VERSION ""

NS_ :

BS_:

BU_: BMS PCU DASH DCU LVPDB DART SN_FRONT SN_REAR IVT

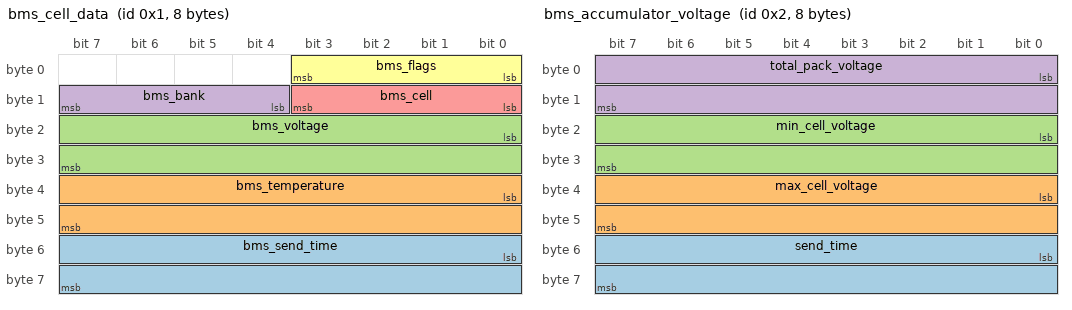
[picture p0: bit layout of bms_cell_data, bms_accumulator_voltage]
BO_ 1 bms_cell_data: 8 BMS
 SG_ bms_send_time : 48|16@1+ (1,0) [0|0] "" Vector__XXX
 SG_ bms_temperature : 32|16@1- (1,0) [0|0] "" Vector__XXX
 SG_ bms_voltage : 16|16@1+ (1,0) [0|0] "" Vector__XXX
 SG_ bms_bank : 12|4@1+ (1,0) [0|0] "" Vector__XXX
 SG_ bms_cell : 8|4@1+ (1,0) [0|0] "" Vector__XXX
 SG_ bms_flags : 0|4@1+ (1,0) [0|0] "" Vector__XXX

BO_ 2 bms_accumulator_voltage: 8 BMS
 SG_ send_time : 48|16@1+ (1,0) [0|0] "" Vector__XXX
 SG_ max_cell_voltage : 32|16@1+ (1,0) [0|0] "" Vector__XXX
 SG_ min_cell_voltage : 16|16@1+ (1,0) [0|0] "" Vector__XXX
 SG_ total_pack_voltage : 0|16@1+ (1,0) [0|0] "" Vector__XXX

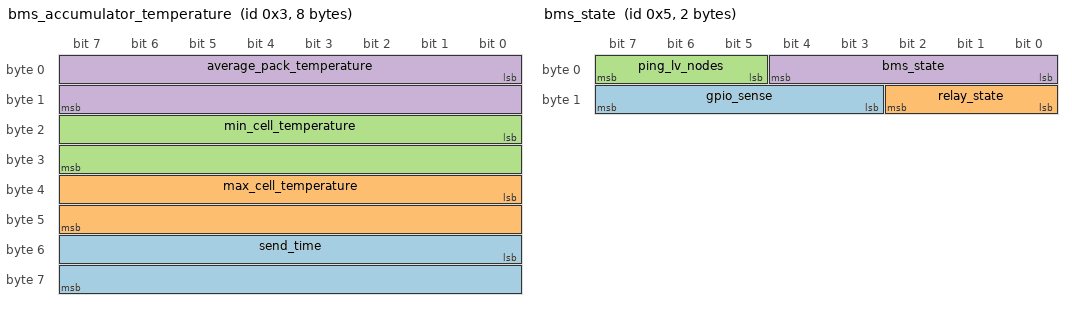
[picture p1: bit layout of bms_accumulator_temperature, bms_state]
BO_ 3 bms_accumulator_temperature: 8 BMS
 SG_ send_time : 48|16@1+ (1,0) [0|0] "" Vector__XXX
 SG_ max_cell_temperature : 32|16@1- (1,0) [0|0] "" Vector__XXX
 SG_ min_cell_temperature : 16|16@1- (1,0) [0|0] "" Vector__XXX
 SG_ average_pack_temperature : 0|16@1- (1,0) [0|0] "" Vector__XXX

BO_ 4 accumulator_faults: 1 BMS
 SG_ imd_fault : 1|1@1+ (1,0) [0|0] "" Vector__XXX
 SG_ bms_fault : 0|1@1+ (1,0) [0|0] "" Vector__XXX

BO_ 5 bms_state: 2 BMS
 SG_ gpio_sense : 11|5@1+ (1,0) [0|0] "" Vector__XXX
 SG_ relay_state : 8|3@1+ (1,0) [0|0] "" Vector__XXX
 SG_ ping_lv_nodes : 5|3@1+ (1,0) [0|0] "" Vector__XXX
 SG_ bms_state : 0|5@1+ (1,0) [0|0] "" Vector__XXX

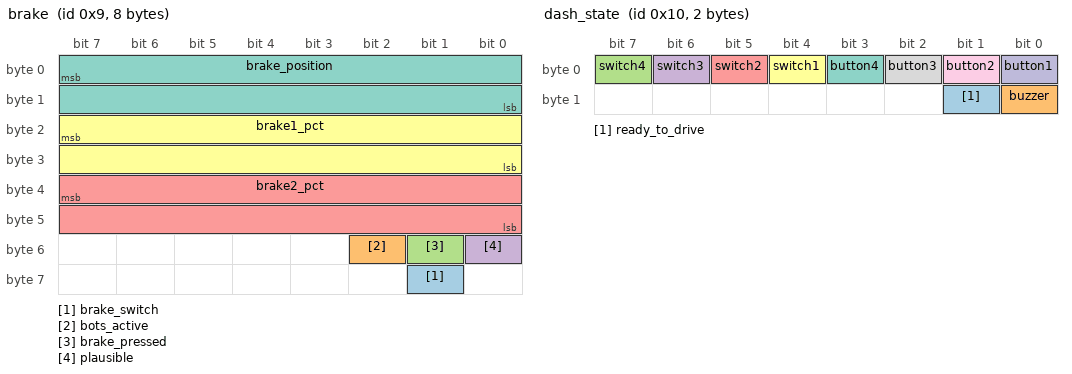
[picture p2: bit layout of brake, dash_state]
BO_ 9 brake: 8 PCU
 SG_ brake_switch : 57|1@1+ (1,0) [0|0] "" Vector__XXX
 SG_ bots_active : 50|1@1+ (1,0) [0|0] "" Vector__XXX
 SG_ brake_pressed : 49|1@1+ (1,0) [0|0] "" Vector__XXX
 SG_ plausible : 48|1@1+ (1,0) [0|0] "" Vector__XXX
 SG_ brake2_pct : 39|16@0+ (0.01,0) [0|0] "%" Vector__XXX
 SG_ brake1_pct : 23|16@0+ (0.01,0) [0|0] "%" Vector__XXX
 SG_ brake_position : 7|16@0+ (0.01,0) [0|0] "%" Vector__XXX

BO_ 10 bspd_state: 1 PCU
 SG_ bspd_state : 0|8@1+ (1,0) [0|0] "" Vector__XXX

BO_ 11 res_state: 2 PCU
 SG_ res_state : 0|8@1+ (1,0) [0|0] "" Vector__XXX

BO_ 16 dash_state: 2 DASH
 SG_ ready_to_drive : 9|1@1+ (1,0) [0|0] "" Vector__XXX
 SG_ buzzer : 8|1@1+ (1,0) [0|0] "" Vector__XXX
 SG_ switch4 : 7|1@1+ (1,0) [0|0] "" Vector__XXX
 SG_ switch3 : 6|1@1+ (1,0) [0|0] "" Vector__XXX
 SG_ switch2 : 5|1@1+ (1,0) [0|0] "" Vector__XXX
 SG_ switch1 : 4|1@1+ (1,0) [0|0] "" Vector__XXX
 SG_ button4 : 3|1@1+ (1,0) [0|0] "" Vector__XXX
 SG_ button3 : 2|1@1+ (1,0) [0|0] "" Vector__XXX
 SG_ button2 : 1|1@1+ (1,0) [0|0] "" Vector__XXX
 SG_ button1 : 0|1@1+ (1,0) [0|0] "" Vector__XXX

BO_ 22 lvpdb_lv_24v_bus_and_12v_bus_vol: 4 LVPDB
 SG_ lv_12v_voltage : 16|16@1+ (1,0) [0|0] "" Vector__XXX
 SG_ lv_24v_voltage : 0|16@1+ (1,0) [0|0] "" Vector__XXX

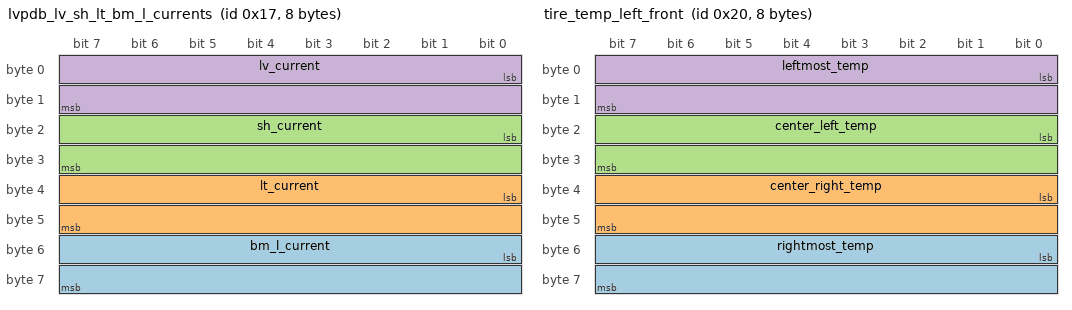
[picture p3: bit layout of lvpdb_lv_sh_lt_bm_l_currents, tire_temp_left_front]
BO_ 23 lvpdb_lv_sh_lt_bm_l_currents: 8 LVPDB
 SG_ bm_l_current : 48|16@1+ (1,0) [0|0] "" Vector__XXX
 SG_ lt_current : 32|16@1+ (1,0) [0|0] "" Vector__XXX
 SG_ sh_current : 16|16@1+ (1,0) [0|0] "" Vector__XXX
 SG_ lv_current : 0|16@1+ (1,0) [0|0] "" Vector__XXX

BO_ 24 lvpdb_sm_af1_af2_cp_rf_currents: 8 LVPDB
 SG_ cp_rf_current : 32|16@1+ (1,0) [0|0] "" Vector__XXX
 SG_ af1_af2_current : 16|16@1+ (1,0) [0|0] "" Vector__XXX
 SG_ sm_current : 0|16@1+ (1,0) [0|0] "" Vector__XXX

BO_ 30 linpot_front: 4 SN_FRONT
 SG_ linpot_right : 16|16@1+ (0.01,0) [0|0] "mm" Vector__XXX
 SG_ linpot_left : 0|16@1+ (0.01,0) [0|0] "mm" Vector__XXX

BO_ 31 linpot_rear: 4 SN_REAR
 SG_ linpot_right : 16|16@1+ (0.01,0) [0|0] "mm" Vector__XXX
 SG_ linpot_left : 0|16@1+ (0.01,0) [0|0] "mm" Vector__XXX

BO_ 32 tire_temp_left_front: 8 SN_FRONT
 SG_ rightmost_temp : 48|16@1+ (1,0) [0|0] "" Vector__XXX
 SG_ center_right_temp : 32|16@1+ (1,0) [0|0] "" Vector__XXX
 SG_ center_left_temp : 16|16@1+ (1,0) [0|0] "" Vector__XXX
 SG_ leftmost_temp : 0|16@1+ (1,0) [0|0] "" Vector__XXX

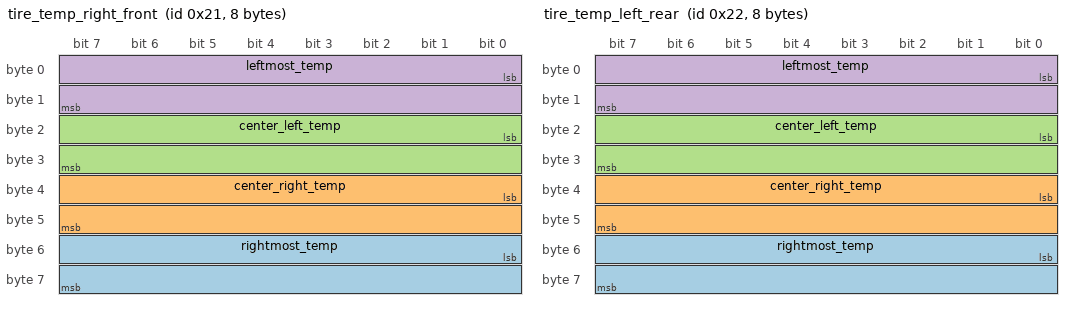
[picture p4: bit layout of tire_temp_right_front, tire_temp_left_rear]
BO_ 33 tire_temp_right_front: 8 SN_FRONT
 SG_ rightmost_temp : 48|16@1+ (1,0) [0|0] "" Vector__XXX
 SG_ center_right_temp : 32|16@1+ (1,0) [0|0] "" Vector__XXX
 SG_ center_left_temp : 16|16@1+ (1,0) [0|0] "" Vector__XXX
 SG_ leftmost_temp : 0|16@1+ (1,0) [0|0] "" Vector__XXX

BO_ 34 tire_temp_left_rear: 8 SN_REAR
 SG_ rightmost_temp : 48|16@1+ (1,0) [0|0] "" Vector__XXX
 SG_ center_right_temp : 32|16@1+ (1,0) [0|0] "" Vector__XXX
 SG_ center_left_temp : 16|16@1+ (1,0) [0|0] "" Vector__XXX
 SG_ leftmost_temp : 0|16@1+ (1,0) [0|0] "" Vector__XXX

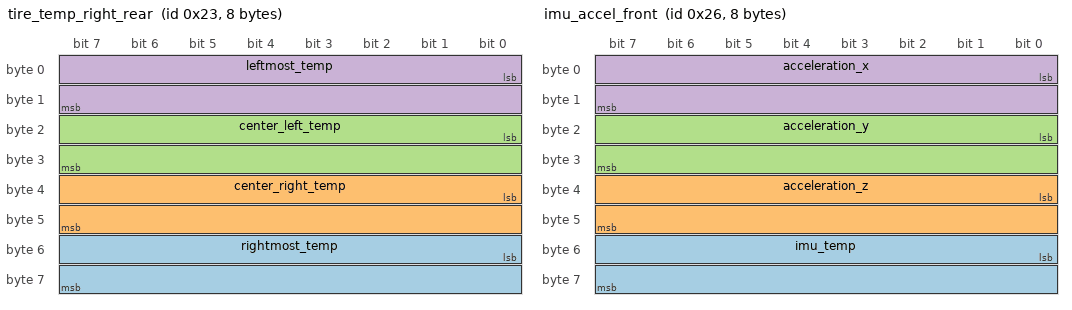
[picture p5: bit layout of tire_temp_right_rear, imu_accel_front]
BO_ 35 tire_temp_right_rear: 8 SN_REAR
 SG_ rightmost_temp : 48|16@1+ (1,0) [0|0] "" Vector__XXX
 SG_ center_right_temp : 32|16@1+ (1,0) [0|0] "" Vector__XXX
 SG_ center_left_temp : 16|16@1+ (1,0) [0|0] "" Vector__XXX
 SG_ leftmost_temp : 0|16@1+ (1,0) [0|0] "" Vector__XXX

BO_ 36 wss_front: 8 SN_FRONT
 SG_ wss_dir_flags : 32|8@1+ (1,0) [0|0] "" Vector__XXX
 SG_ wss_right : 16|16@1+ (0.01,0) [0|0] "mph" Vector__XXX
 SG_ wss_left : 0|16@1+ (0.01,0) [0|0] "mph" Vector__XXX

BO_ 37 wss_rear: 8 SN_REAR
 SG_ wss_dir_flags : 32|8@1+ (1,0) [0|0] "" Vector__XXX
 SG_ wss_right : 16|16@1+ (0.01,0) [0|0] "mph" Vector__XXX
 SG_ wss_left : 0|16@1+ (0.01,0) [0|0] "mph" Vector__XXX

BO_ 38 imu_accel_front: 8 SN_FRONT
 SG_ imu_temp : 48|16@1- (0.01,0) [0|0] "degC" Vector__XXX
 SG_ acceleration_z : 32|16@1- (0.061,0) [0|0] "mg" Vector__XXX
 SG_ acceleration_y : 16|16@1- (0.061,0) [0|0] "mg" Vector__XXX
 SG_ acceleration_x : 0|16@1- (0.061,0) [0|0] "mg" Vector__XXX

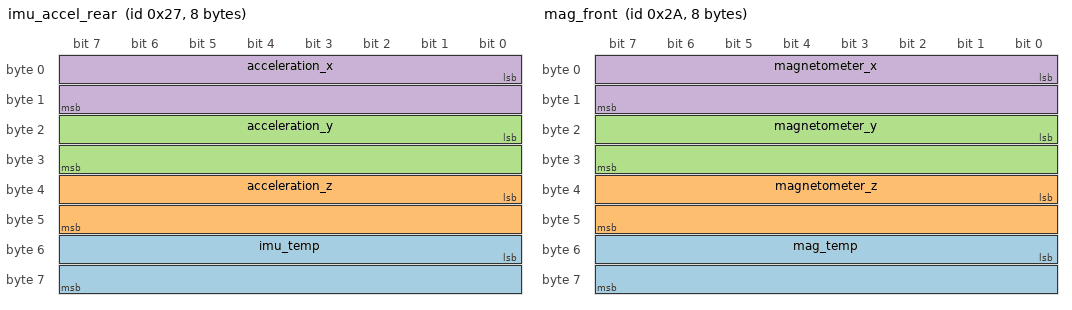
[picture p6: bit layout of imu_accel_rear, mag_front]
BO_ 39 imu_accel_rear: 8 SN_REAR
 SG_ imu_temp : 48|16@1- (0.01,0) [0|0] "degC" Vector__XXX
 SG_ acceleration_z : 32|16@1- (0.061,0) [0|0] "mg" Vector__XXX
 SG_ acceleration_y : 16|16@1- (0.061,0) [0|0] "mg" Vector__XXX
 SG_ acceleration_x : 0|16@1- (0.061,0) [0|0] "mg" Vector__XXX

BO_ 40 imu_gyro_front: 6 SN_FRONT
 SG_ gyro_z : 32|16@1- (70,0) [0|0] "mdps" Vector__XXX
 SG_ gyro_y : 16|16@1- (70,0) [0|0] "mdps" Vector__XXX
 SG_ gyro_x : 0|16@1- (70,0) [0|0] "mdps" Vector__XXX

BO_ 41 imu_gyro_rear: 6 SN_REAR
 SG_ gyro_z : 32|16@1- (70,0) [0|0] "mdps" Vector__XXX
 SG_ gyro_y : 16|16@1- (70,0) [0|0] "mdps" Vector__XXX
 SG_ gyro_x : 0|16@1- (70,0) [0|0] "mdps" Vector__XXX

BO_ 42 mag_front: 8 SN_FRONT
 SG_ mag_temp : 48|16@1- (0.01,0) [0|0] "degC" Vector__XXX
 SG_ magnetometer_z : 32|16@1- (0.5844,0) [0|0] "mG" Vector__XXX
 SG_ magnetometer_y : 16|16@1- (0.5844,0) [0|0] "mG" Vector__XXX
 SG_ magnetometer_x : 0|16@1- (0.5844,0) [0|0] "mG" Vector__XXX

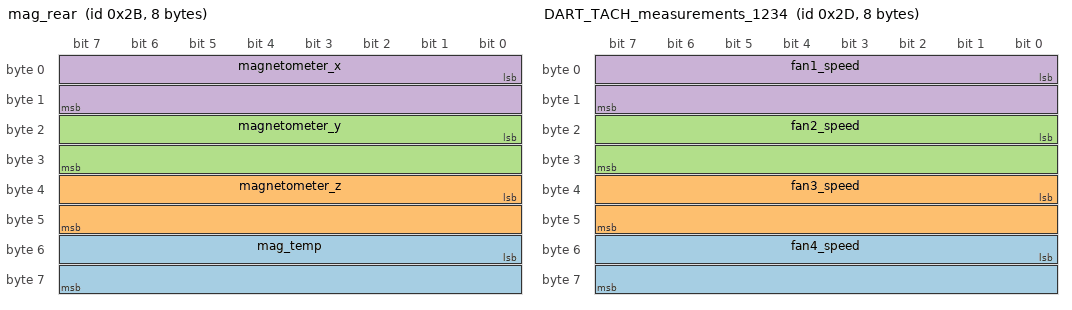
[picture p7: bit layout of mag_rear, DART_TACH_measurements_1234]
BO_ 43 mag_rear: 8 SN_REAR
 SG_ mag_temp : 48|16@1- (0.01,0) [0|0] "degC" Vector__XXX
 SG_ magnetometer_z : 32|16@1- (0.5844,0) [0|0] "mG" Vector__XXX
 SG_ magnetometer_y : 16|16@1- (0.5844,0) [0|0] "mG" Vector__XXX
 SG_ magnetometer_x : 0|16@1- (0.5844,0) [0|0] "mG" Vector__XXX

BO_ 45 DART_TACH_measurements_1234: 8 DART
 SG_ fan4_speed : 48|16@1+ (1,0) [0|0] "" Vector__XXX
 SG_ fan3_speed : 32|16@1+ (1,0) [0|0] "" Vector__XXX
 SG_ fan2_speed : 16|16@1+ (1,0) [0|0] "" Vector__XXX
 SG_ fan1_speed : 0|16@1+ (1,0) [0|0] "" Vector__XXX

BO_ 46 DART_TACH_measurements_5: 2 DART
 SG_ fan5_speed : 0|16@1+ (1,0) [0|0] "" Vector__XXX

BO_ 52 bbb_tps: 4 BMS
 SG_ current : 16|16@1+ (1,0) [0|0] "" Vector__XXX
 SG_ voltage : 0|16@1+ (1,0) [0|0] "" Vector__XXX

BO_ 53 pcu_tps: 4 PCU
 SG_ current : 16|16@1+ (1,0) [0|0] "mA" Vector__XXX
 SG_ voltage : 0|16@1+ (1,0) [0|0] "mV" Vector__XXX

BO_ 54 dash_tps: 4 DASH
 SG_ current : 16|16@1+ (1,0) [0|0] "" Vector__XXX
 SG_ voltage : 0|16@1+ (1,0) [0|0] "" Vector__XXX

BO_ 55 dcu_tps: 4 DCU
 SG_ current : 16|16@1+ (1,0) [0|0] "" Vector__XXX
 SG_ voltage : 0|16@1+ (1,0) [0|0] "" Vector__XXX

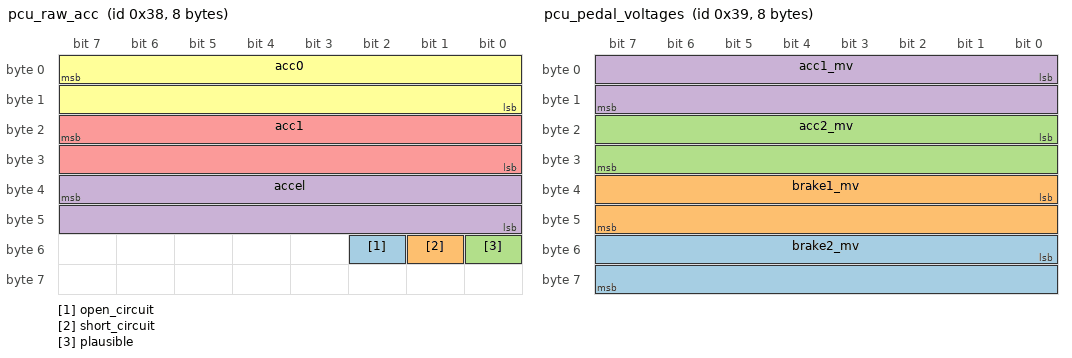
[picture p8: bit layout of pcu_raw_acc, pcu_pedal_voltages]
BO_ 56 pcu_raw_acc: 8 PCU
 SG_ open_circuit : 50|1@1+ (1,0) [0|0] "" Vector__XXX
 SG_ short_circuit : 49|1@1+ (1,0) [0|0] "" Vector__XXX
 SG_ plausible : 48|1@1+ (1,0) [0|0] "" Vector__XXX
 SG_ accel : 39|16@0+ (0.01,0) [0|0] "%" Vector__XXX
 SG_ acc1 : 23|16@0+ (0.01,0) [0|0] "%" Vector__XXX
 SG_ acc0 : 7|16@0+ (0.01,0) [0|0] "%" Vector__XXX

BO_ 57 pcu_pedal_voltages: 8 PCU
 SG_ brake2_mv : 48|16@1+ (1,0) [0|0] "mV" Vector__XXX
 SG_ brake1_mv : 32|16@1+ (1,0) [0|0] "mV" Vector__XXX
 SG_ acc2_mv : 16|16@1+ (1,0) [0|0] "mV" Vector__XXX
 SG_ acc1_mv : 0|16@1+ (1,0) [0|0] "mV" Vector__XXX

BO_ 64 gps_pos_front: 8 SN_FRONT
 SG_ longitude : 32|32@1- (1e-07,0) [0|0] "deg" Vector__XXX
 SG_ latitude : 0|32@1- (1e-07,0) [0|0] "deg" Vector__XXX

BO_ 65 gps_altitude_front: 8 SN_FRONT
 SG_ vdop : 48|16@1+ (0.01,0) [0|0] "" Vector__XXX
 SG_ hdop : 32|16@1+ (0.01,0) [0|0] "" Vector__XXX
 SG_ altitude : 0|32@1- (0.01,0) [0|0] "m" Vector__XXX

BO_ 66 gps_motion_front: 4 SN_FRONT
 SG_ course : 16|16@1+ (0.01,0) [0|0] "deg" Vector__XXX
 SG_ speed : 0|16@1+ (0.01,0) [0|0] "km/h" Vector__XXX

BO_ 67 gps_time_front: 3 SN_FRONT
 SG_ seconds : 16|8@1- (1,0) [0|0] "" Vector__XXX
 SG_ minutes : 8|8@1- (1,0) [0|0] "" Vector__XXX
 SG_ hours : 0|8@1- (1,0) [0|0] "" Vector__XXX

BO_ 68 gps_date_front: 3 SN_FRONT
 SG_ year : 16|8@1- (1,0) [0|0] "" Vector__XXX
 SG_ month : 8|8@1- (1,0) [0|0] "" Vector__XXX
 SG_ day : 0|8@1- (1,0) [0|0] "" Vector__XXX

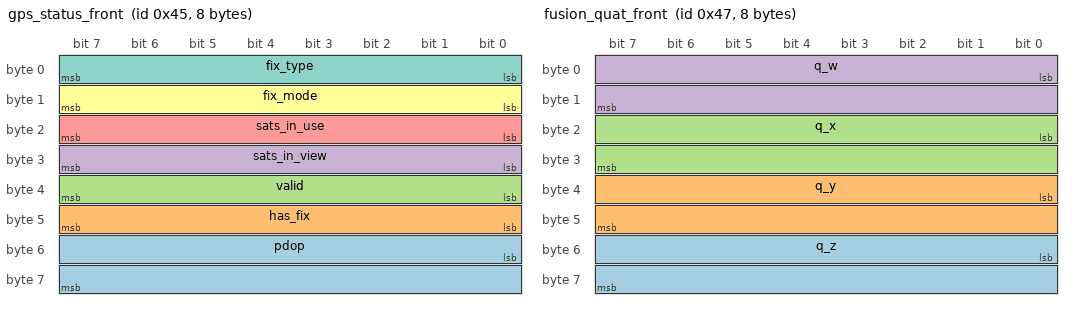
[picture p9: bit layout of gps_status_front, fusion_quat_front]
BO_ 69 gps_status_front: 8 SN_FRONT
 SG_ pdop : 48|16@1+ (0.01,0) [0|0] "" Vector__XXX
 SG_ has_fix : 40|8@1+ (1,0) [0|0] "" Vector__XXX
 SG_ valid : 32|8@1+ (1,0) [0|0] "" Vector__XXX
 SG_ sats_in_view : 24|8@1+ (1,0) [0|0] "" Vector__XXX
 SG_ sats_in_use : 16|8@1+ (1,0) [0|0] "" Vector__XXX
 SG_ fix_mode : 8|8@1+ (1,0) [0|0] "" Vector__XXX
 SG_ fix_type : 0|8@1+ (1,0) [0|0] "" Vector__XXX

BO_ 71 fusion_quat_front: 8 SN_FRONT
 SG_ q_z : 48|16@1- (3.051850947599719e-05,0) [0|0] "" Vector__XXX
 SG_ q_y : 32|16@1- (3.051850947599719e-05,0) [0|0] "" Vector__XXX
 SG_ q_x : 16|16@1- (3.051850947599719e-05,0) [0|0] "" Vector__XXX
 SG_ q_w : 0|16@1- (3.051850947599719e-05,0) [0|0] "" Vector__XXX

BO_ 72 fusion_euler_front: 6 SN_FRONT
 SG_ yaw : 32|16@1- (0.01,0) [0|0] "deg" Vector__XXX
 SG_ pitch : 16|16@1- (0.01,0) [0|0] "deg" Vector__XXX
 SG_ roll : 0|16@1- (0.01,0) [0|0] "deg" Vector__XXX

BO_ 73 fusion_lin_accel_front: 6 SN_FRONT
 SG_ lin_accel_z : 32|16@1- (1,0) [0|0] "mg" Vector__XXX
 SG_ lin_accel_y : 16|16@1- (1,0) [0|0] "mg" Vector__XXX
 SG_ lin_accel_x : 0|16@1- (1,0) [0|0] "mg" Vector__XXX

BO_ 74 fusion_earth_accel_front: 6 SN_FRONT
 SG_ earth_accel_z : 32|16@1- (1,0) [0|0] "mg" Vector__XXX
 SG_ earth_accel_y : 16|16@1- (1,0) [0|0] "mg" Vector__XXX
 SG_ earth_accel_x : 0|16@1- (1,0) [0|0] "mg" Vector__XXX

BO_ 75 fusion_status_front: 3 SN_FRONT
 SG_ mag_error : 16|8@1+ (0.1,0) [0|0] "deg" Vector__XXX
 SG_ accel_error : 8|8@1+ (0.1,0) [0|0] "deg" Vector__XXX
 SG_ flags : 0|8@1+ (1,0) [0|0] "" Vector__XXX

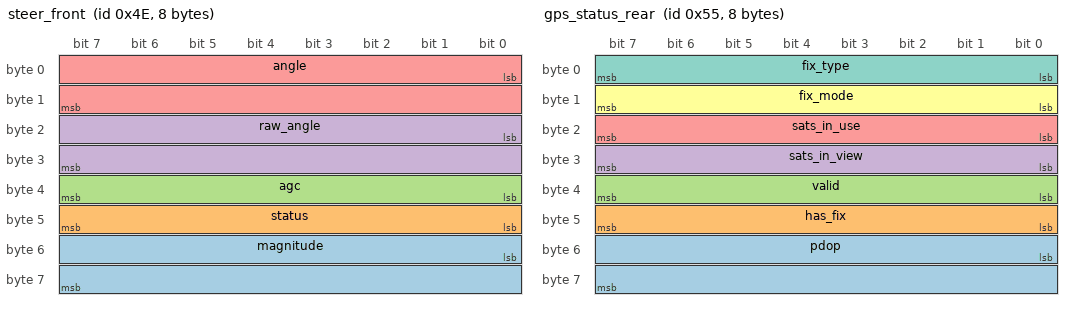
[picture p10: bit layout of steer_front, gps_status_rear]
BO_ 78 steer_front: 8 SN_FRONT
 SG_ magnitude : 48|16@1+ (1,0) [0|0] "" Vector__XXX
 SG_ status : 40|8@1+ (1,0) [0|0] "" Vector__XXX
 SG_ agc : 32|8@1+ (1,0) [0|0] "" Vector__XXX
 SG_ raw_angle : 16|16@1+ (0.087890625,0) [0|0] "deg" Vector__XXX
 SG_ angle : 0|16@1+ (0.087890625,0) [0|0] "deg" Vector__XXX

BO_ 80 gps_pos_rear: 8 SN_REAR
 SG_ longitude : 32|32@1- (1e-07,0) [0|0] "deg" Vector__XXX
 SG_ latitude : 0|32@1- (1e-07,0) [0|0] "deg" Vector__XXX

BO_ 81 gps_altitude_rear: 8 SN_REAR
 SG_ vdop : 48|16@1+ (0.01,0) [0|0] "" Vector__XXX
 SG_ hdop : 32|16@1+ (0.01,0) [0|0] "" Vector__XXX
 SG_ altitude : 0|32@1- (0.01,0) [0|0] "m" Vector__XXX

BO_ 82 gps_motion_rear: 4 SN_REAR
 SG_ course : 16|16@1+ (0.01,0) [0|0] "deg" Vector__XXX
 SG_ speed : 0|16@1+ (0.01,0) [0|0] "km/h" Vector__XXX

BO_ 83 gps_time_rear: 3 SN_REAR
 SG_ seconds : 16|8@1- (1,0) [0|0] "" Vector__XXX
 SG_ minutes : 8|8@1- (1,0) [0|0] "" Vector__XXX
 SG_ hours : 0|8@1- (1,0) [0|0] "" Vector__XXX

BO_ 84 gps_date_rear: 3 SN_REAR
 SG_ year : 16|8@1- (1,0) [0|0] "" Vector__XXX
 SG_ month : 8|8@1- (1,0) [0|0] "" Vector__XXX
 SG_ day : 0|8@1- (1,0) [0|0] "" Vector__XXX

BO_ 85 gps_status_rear: 8 SN_REAR
 SG_ pdop : 48|16@1+ (0.01,0) [0|0] "" Vector__XXX
 SG_ has_fix : 40|8@1+ (1,0) [0|0] "" Vector__XXX
 SG_ valid : 32|8@1+ (1,0) [0|0] "" Vector__XXX
 SG_ sats_in_view : 24|8@1+ (1,0) [0|0] "" Vector__XXX
 SG_ sats_in_use : 16|8@1+ (1,0) [0|0] "" Vector__XXX
 SG_ fix_mode : 8|8@1+ (1,0) [0|0] "" Vector__XXX
 SG_ fix_type : 0|8@1+ (1,0) [0|0] "" Vector__XXX

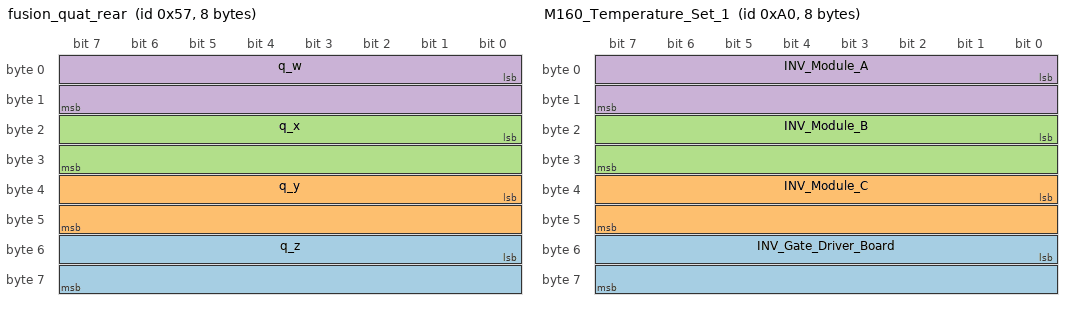
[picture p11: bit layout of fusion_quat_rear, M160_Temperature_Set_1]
BO_ 87 fusion_quat_rear: 8 SN_REAR
 SG_ q_z : 48|16@1- (3.051850947599719e-05,0) [0|0] "" Vector__XXX
 SG_ q_y : 32|16@1- (3.051850947599719e-05,0) [0|0] "" Vector__XXX
 SG_ q_x : 16|16@1- (3.051850947599719e-05,0) [0|0] "" Vector__XXX
 SG_ q_w : 0|16@1- (3.051850947599719e-05,0) [0|0] "" Vector__XXX

BO_ 88 fusion_euler_rear: 6 SN_REAR
 SG_ yaw : 32|16@1- (0.01,0) [0|0] "deg" Vector__XXX
 SG_ pitch : 16|16@1- (0.01,0) [0|0] "deg" Vector__XXX
 SG_ roll : 0|16@1- (0.01,0) [0|0] "deg" Vector__XXX

BO_ 89 fusion_lin_accel_rear: 6 SN_REAR
 SG_ lin_accel_z : 32|16@1- (1,0) [0|0] "mg" Vector__XXX
 SG_ lin_accel_y : 16|16@1- (1,0) [0|0] "mg" Vector__XXX
 SG_ lin_accel_x : 0|16@1- (1,0) [0|0] "mg" Vector__XXX

BO_ 90 fusion_earth_accel_rear: 6 SN_REAR
 SG_ earth_accel_z : 32|16@1- (1,0) [0|0] "mg" Vector__XXX
 SG_ earth_accel_y : 16|16@1- (1,0) [0|0] "mg" Vector__XXX
 SG_ earth_accel_x : 0|16@1- (1,0) [0|0] "mg" Vector__XXX

BO_ 91 fusion_status_rear: 3 SN_REAR
 SG_ mag_error : 16|8@1+ (0.1,0) [0|0] "deg" Vector__XXX
 SG_ accel_error : 8|8@1+ (0.1,0) [0|0] "deg" Vector__XXX
 SG_ flags : 0|8@1+ (1,0) [0|0] "" Vector__XXX

BO_ 160 M160_Temperature_Set_1: 8 INV
 SG_ INV_Gate_Driver_Board : 48|16@1- (0.1,0) [-3276.8|3276.7] "temperature:C" Vector__XXX
 SG_ INV_Module_C : 32|16@1- (0.1,0) [-3276.8|3276.7] "temperature:C" Vector__XXX
 SG_ INV_Module_B : 16|16@1- (0.1,0) [-3276.8|3276.7] "temperature:C" Vector__XXX
 SG_ INV_Module_A : 0|16@1- (0.1,0) [-3276.8|3276.7] "temperature:C" Vector__XXX

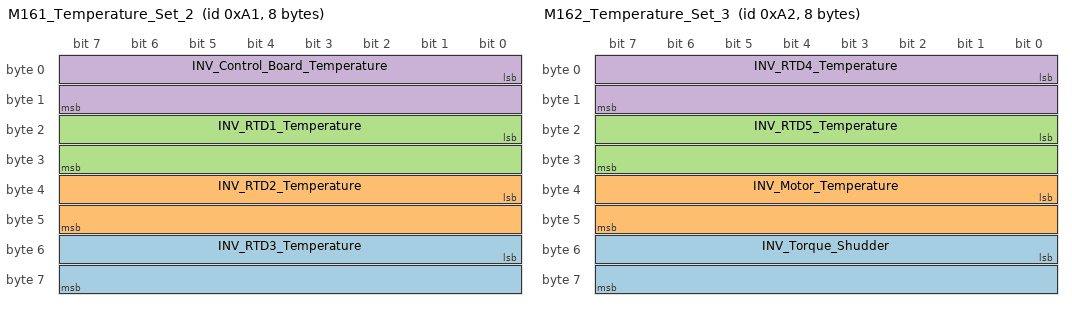
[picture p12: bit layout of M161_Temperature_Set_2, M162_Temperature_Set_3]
BO_ 161 M161_Temperature_Set_2: 8 INV
 SG_ INV_RTD3_Temperature : 48|16@1- (0.1,0) [-3276.8|3276.7] "temperature:C" Vector__XXX
 SG_ INV_RTD2_Temperature : 32|16@1- (0.1,0) [-3276.8|3276.7] "temperature:C" Vector__XXX
 SG_ INV_RTD1_Temperature : 16|16@1- (0.1,0) [-3276.8|3276.7] "temperature:C" Vector__XXX
 SG_ INV_Control_Board_Temperature : 0|16@1- (0.1,0) [-3276.8|3276.7] "temperature:C" Vector__XXX

BO_ 162 M162_Temperature_Set_3: 8 INV
 SG_ INV_Torque_Shudder : 48|16@1- (0.1,0) [-3276.8|3276.7] "torque:N.m" Vector__XXX
 SG_ INV_Motor_Temperature : 32|16@1- (0.1,0) [-3276.8|3276.7] "temperature:C" Vector__XXX
 SG_ INV_RTD5_Temperature : 16|16@1- (0.1,0) [-3276.8|3276.7] "temperature:C" Vector__XXX
 SG_ INV_RTD4_Temperature : 0|16@1- (0.1,0) [-3276.8|3276.7] "temperature:C" Vector__XXX

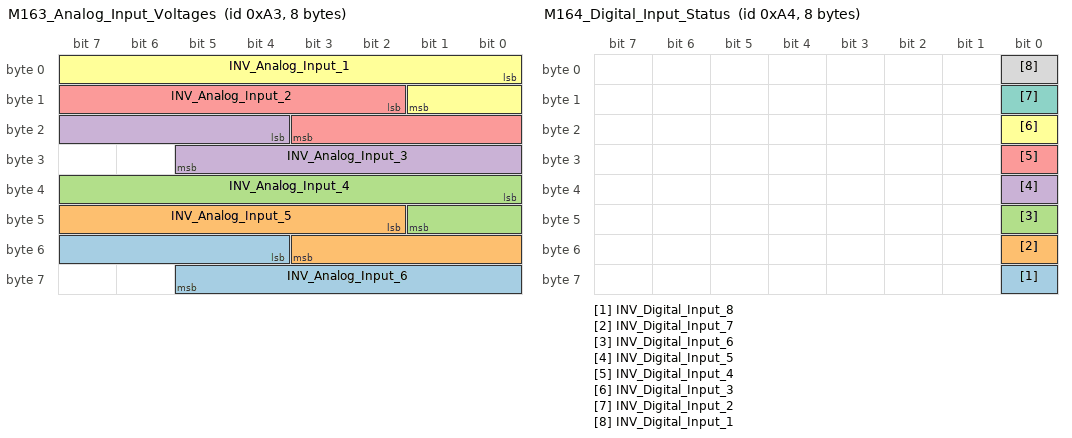
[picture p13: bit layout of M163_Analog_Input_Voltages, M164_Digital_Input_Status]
BO_ 163 M163_Analog_Input_Voltages: 8 INV
 SG_ INV_Analog_Input_6 : 52|10@1+ (0.01,0) [0|10.23] "voltage:V" Vector__XXX
 SG_ INV_Analog_Input_5 : 42|10@1+ (0.01,0) [0|10.23] "voltage:V" Vector__XXX
 SG_ INV_Analog_Input_4 : 32|10@1+ (0.01,0) [0|10.23] "voltage:V" Vector__XXX
 SG_ INV_Analog_Input_3 : 20|10@1+ (0.01,0) [0|10.23] "voltage:V" Vector__XXX
 SG_ INV_Analog_Input_2 : 10|10@1+ (0.01,0) [0|10.23] "voltage:V" Vector__XXX
 SG_ INV_Analog_Input_1 : 0|10@1+ (0.01,0) [0|10.23] "voltage:V" Vector__XXX

BO_ 164 M164_Digital_Input_Status: 8 INV
 SG_ INV_Digital_Input_8 : 56|1@1+ (1,0) [0|1] "" Vector__XXX
 SG_ INV_Digital_Input_7 : 48|1@1+ (1,0) [0|1] "" Vector__XXX
 SG_ INV_Digital_Input_6 : 40|1@1+ (1,0) [0|1] "" Vector__XXX
 SG_ INV_Digital_Input_5 : 32|1@1+ (1,0) [0|1] "" Vector__XXX
 SG_ INV_Digital_Input_4 : 24|1@1+ (1,0) [0|1] "" Vector__XXX
 SG_ INV_Digital_Input_3 : 16|1@1+ (1,0) [0|1] "" Vector__XXX
 SG_ INV_Digital_Input_2 : 8|1@1+ (1,0) [0|1] "" Vector__XXX
 SG_ INV_Digital_Input_1 : 0|1@1+ (1,0) [0|1] "" Vector__XXX

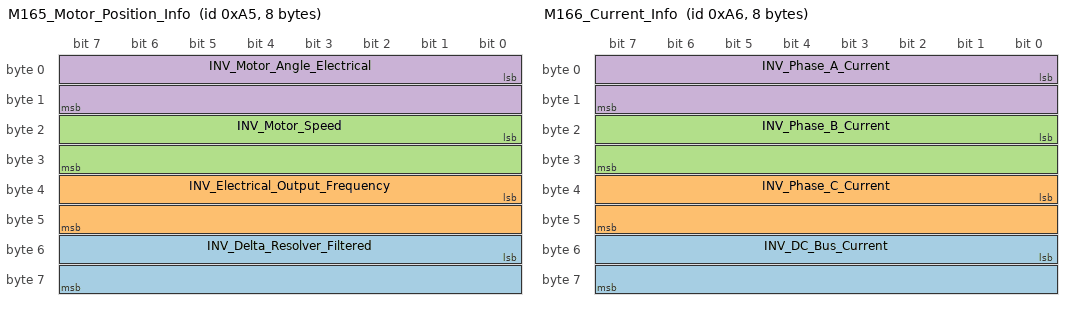
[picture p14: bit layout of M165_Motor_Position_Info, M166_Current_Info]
BO_ 165 M165_Motor_Position_Info: 8 INV
 SG_ INV_Delta_Resolver_Filtered : 48|16@1- (0.1,0) [-3276.8|3276.7] "angle:deg" Vector__XXX
 SG_ INV_Electrical_Output_Frequency : 32|16@1- (0.1,0) [-3276.8|3276.7] "frequency:Hz" Vector__XXX
 SG_ INV_Motor_Speed : 16|16@1- (1,0) [-32768|32767] "angular_speed:rpm" Vector__XXX
 SG_ INV_Motor_Angle_Electrical : 0|16@1+ (0.1,0) [0|6553.5] "angle:deg" Vector__XXX

BO_ 166 M166_Current_Info: 8 INV
 SG_ INV_DC_Bus_Current : 48|16@1- (0.1,0) [-3276.8|3276.7] "current:A" Vector__XXX
 SG_ INV_Phase_C_Current : 32|16@1- (0.1,0) [-3276.8|3276.7] "current:A" Vector__XXX
 SG_ INV_Phase_B_Current : 16|16@1- (0.1,0) [-3276.8|3276.7] "current:A" Vector__XXX
 SG_ INV_Phase_A_Current : 0|16@1- (0.1,0) [-3276.8|3276.7] "current:A" Vector__XXX

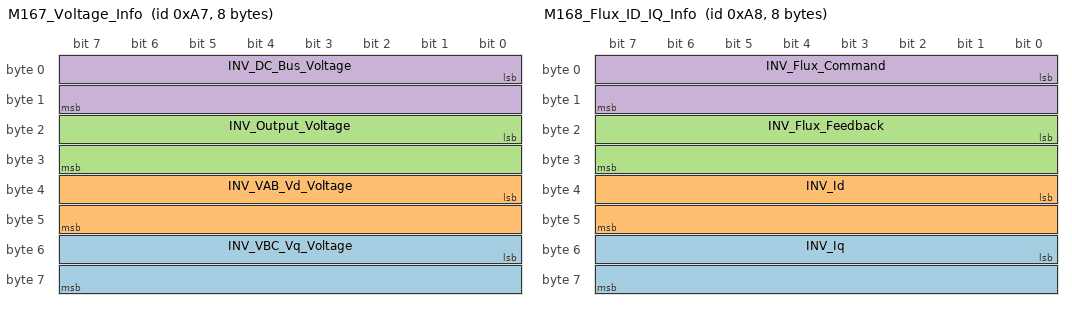
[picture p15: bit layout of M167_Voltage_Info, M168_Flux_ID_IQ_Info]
BO_ 167 M167_Voltage_Info: 8 INV
 SG_ INV_VBC_Vq_Voltage : 48|16@1- (0.1,0) [-3276.8|3276.7] "voltage:V" Vector__XXX
 SG_ INV_VAB_Vd_Voltage : 32|16@1- (0.1,0) [-3276.8|3276.7] "voltage:V" Vector__XXX
 SG_ INV_Output_Voltage : 16|16@1- (0.1,0) [-3276.8|3276.7] "voltage:V" Vector__XXX
 SG_ INV_DC_Bus_Voltage : 0|16@1- (0.1,0) [-3276.8|3276.7] "voltage:V" Vector__XXX

BO_ 168 M168_Flux_ID_IQ_Info: 8 INV
 SG_ INV_Iq : 48|16@1- (0.1,0) [-3276.8|3276.7] "current:A" Vector__XXX
 SG_ INV_Id : 32|16@1- (0.1,0) [-3276.8|3276.7] "current:A" Vector__XXX
 SG_ INV_Flux_Feedback : 16|16@1- (0.001,0) [-32.768|32.767] "flux:Wb" Vector__XXX
 SG_ INV_Flux_Command : 0|16@1- (0.001,0) [-32.768|32.767] "flux:Wb" Vector__XXX

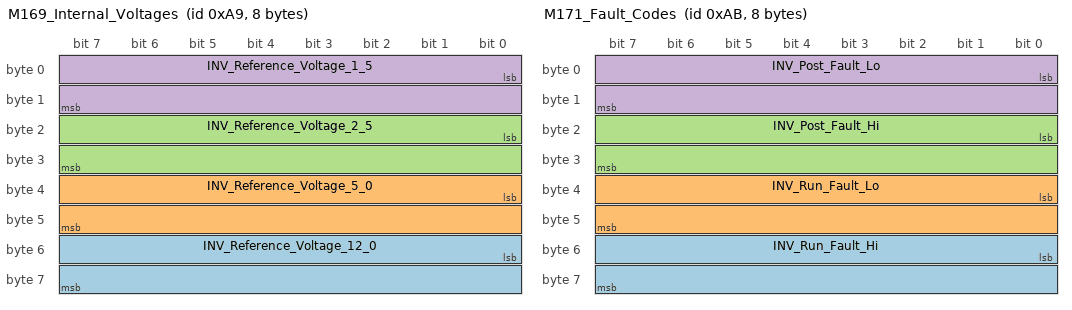
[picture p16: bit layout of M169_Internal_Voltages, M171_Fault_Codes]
BO_ 169 M169_Internal_Voltages: 8 INV
 SG_ INV_Reference_Voltage_12_0 : 48|16@1- (0.01,0) [-327.68|327.67] "voltage:V" Vector__XXX
 SG_ INV_Reference_Voltage_5_0 : 32|16@1- (0.01,0) [-327.68|327.67] "voltage:V" Vector__XXX
 SG_ INV_Reference_Voltage_2_5 : 16|16@1- (0.01,0) [-327.68|327.67] "voltage:V" Vector__XXX
 SG_ INV_Reference_Voltage_1_5 : 0|16@1- (0.01,0) [-327.68|327.67] "voltage:V" Vector__XXX

BO_ 170 M170_Internal_States: 8 INV
 SG_ INV_Low_Speed_Limiting : 61|1@1+ (1,0) [0|1] "" Vector__XXX
 SG_ INV_Max_Speed_Limiting : 59|1@1+ (1,0) [0|1] "" Vector__XXX
 SG_ INV_BMS_Torque_Limiting : 58|1@1+ (1,0) [0|1] "" Vector__XXX
 SG_ INV_BMS_Active : 57|1@1+ (1,0) [0|1] "" Vector__XXX
 SG_ INV_Direction_Command : 56|1@1+ (1,0) [0|1] "" Vector__XXX
 SG_ INV_Inverter_Enable_Lockout : 55|1@1+ (1,0) [0|1] "" Vector__XXX
 SG_ INV_Start_Mode_Active : 54|1@1+ (1,0) [0|1] "" Vector__XXX
 SG_ INV_Inverter_Enable_State : 48|1@1+ (1,0) [0|1] "" Vector__XXX
 SG_ INV_Rolling_Counter : 44|4@1+ (1,0) [0|15] "" Vector__XXX
 SG_ INV_Inverter_Command_Mode : 40|1@1+ (1,0) [0|1] "" Vector__XXX
 SG_ INV_Inverter_Discharge_State : 37|3@1+ (1,0) [0|7] "" Vector__XXX
 SG_ INV_Inverter_Run_Mode : 32|1@1+ (1,0) [0|1] "" Vector__XXX
 SG_ INV_Relay_6_Status : 29|1@1+ (1,0) [0|1] "" Vector__XXX
 SG_ INV_Relay_5_Status : 28|1@1+ (1,0) [0|1] "" Vector__XXX
 SG_ INV_Relay_4_Status : 27|1@1+ (1,0) [0|1] "" Vector__XXX
 SG_ INV_Relay_3_Status : 26|1@1+ (1,0) [0|1] "" Vector__XXX
 SG_ INV_Relay_2_Status : 25|1@1+ (1,0) [0|1] "" Vector__XXX
 SG_ INV_Relay_1_Status : 24|1@1+ (1,0) [0|1] "" Vector__XXX
 SG_ INV_Inverter_State : 16|8@1+ (1,0) [0|255] "" Vector__XXX
 SG_ INV_PWM_Frequency : 8|8@1+ (1,0) [0|255] "kHz" Vector__XXX
 SG_ INV_VSM_State : 0|8@1+ (1,0) [0|15] "" Vector__XXX

BO_ 171 M171_Fault_Codes: 8 INV
 SG_ INV_Run_Fault_Hi : 48|16@1+ (1,0) [0|65535] "" Vector__XXX
 SG_ INV_Run_Fault_Lo : 32|16@1+ (1,0) [0|65535] "" Vector__XXX
 SG_ INV_Post_Fault_Hi : 16|16@1+ (1,0) [0|65535] "" Vector__XXX
 SG_ INV_Post_Fault_Lo : 0|16@1+ (1,0) [0|65535] "" Vector__XXX

BO_ 172 M172_Torque_And_Timer_Info: 8 INV
 SG_ INV_Power_On_Timer : 32|32@1+ (0.003,0) [0|12884800] "time:sec" Vector__XXX
 SG_ INV_Torque_Feedback : 16|16@1- (0.1,0) [-3276.8|3276.7] "torque:N.m" Vector__XXX
 SG_ INV_Commanded_Torque : 0|16@1- (0.1,0) [-3276.8|3276.7] "torque:N.m" Vector__XXX

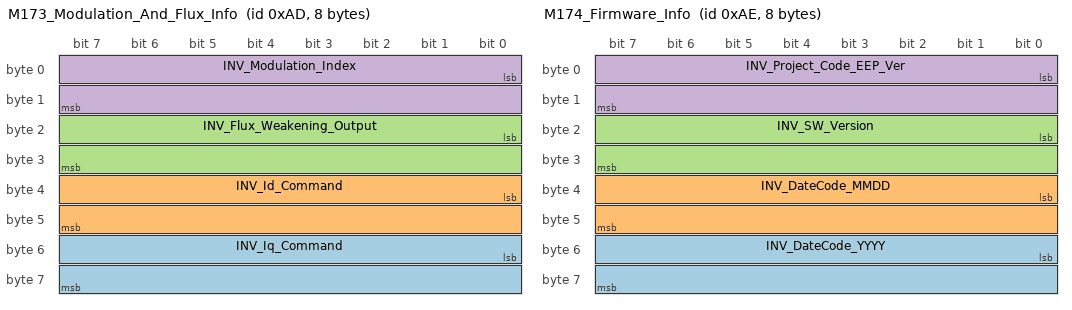
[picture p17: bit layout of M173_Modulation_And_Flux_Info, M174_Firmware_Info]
BO_ 173 M173_Modulation_And_Flux_Info: 8 INV
 SG_ INV_Iq_Command : 48|16@1- (0.1,0) [-3276.8|3276.7] "current:A" Vector__XXX
 SG_ INV_Id_Command : 32|16@1- (0.1,0) [-3276.8|3276.7] "current:A" Vector__XXX
 SG_ INV_Flux_Weakening_Output : 16|16@1- (0.1,0) [-3276.8|3276.7] "current:A" Vector__XXX
 SG_ INV_Modulation_Index : 0|16@1- (0.0001,0) [0|3.2767] "" Vector__XXX

BO_ 174 M174_Firmware_Info: 8 INV
 SG_ INV_DateCode_YYYY : 48|16@1+ (1,0) [0|65535] "" Vector__XXX
 SG_ INV_DateCode_MMDD : 32|16@1+ (1,0) [0|65535] "" Vector__XXX
 SG_ INV_SW_Version : 16|16@1+ (1,0) [0|65535] "" Vector__XXX
 SG_ INV_Project_Code_EEP_Ver : 0|16@1+ (1,0) [0|65535] "" Vector__XXX

BO_ 175 M175_Diag_Data_Message: 8 INV
 SG_ INV_Diag_Run_Faults_Hi m5 : 48|16@1+ (1,0) [0|65535] "" Vector__XXX
 SG_ INV_Diag_Vqs_Cmd m4 : 48|16@1- (0.1,0) [-1000|1000] "voltage:V" Vector__XXX
 SG_ INV_Diag_FW_Output m3 : 48|16@1- (0.1,0) [-2000|2000] "current:A" Vector__XXX
 SG_ INV_Diag_Iq_cmd m2 : 48|16@1- (0.1,0) [-2000|2000] "current:A" Vector__XXX
 SG_ INV_Diag_Ib m1 : 48|16@1- (0.1,0) [-2000|2000] "current:A" Vector__XXX
 SG_ INV_Diag_Sin m0 : 48|16@1- (1,0) [-5|5] "voltage:V" Vector__XXX
 SG_ INV_Diag_Run_Faults_Lo m5 : 32|16@1+ (1,0) [0|65535] "" Vector__XXX
 SG_ INV_Diag_Vd_Cmd m4 : 32|16@1- (0.1,0) [-1000|1000] "voltage:V" Vector__XXX
 SG_ INV_Diag_Mod_Index m3 : 32|16@1- (0.0001,0) [0|2] "" Vector__XXX
 SG_ INV_Diag_Vdc m2 : 32|16@1- (0.1,0) [0|1000] "voltage:V" Vector__XXX
 SG_ INV_Diag_Ia m1 : 32|16@1- (0.1,0) [-2000|2000] "current:A" Vector__XXX
 SG_ INV_Diag_Gamma_Observer m0 : 32|16@1- (0.1,0) [0|360] "angle:deg" Vector__XXX
 SG_ INV_Diag_12V m5 : 16|16@1+ (0.01,0) [0|36] "voltage:V" Vector__XXX
 SG_ INV_Diag_Vq_Cmd m4 : 16|16@1- (0.1,0) [-1000|1000] "voltage:V" Vector__XXX
 SG_ INV_Diag_Id_cmd m3 : 16|16@1- (0.1,0) [-2000|2000] "current:A" Vector__XXX
 SG_ INV_Diag_Ic m2 : 16|16@1- (0.1,0) [-2000|2000] "current:A" Vector__XXX
 SG_ INV_Diag_Cos m1 : 16|16@1- (1,0) [-5|5] "voltage:V" Vector__XXX
 SG_ INV_Diag_Gamma_Resolver m0 : 16|16@1- (0.1,0) [0|360] "angle:deg" Vector__XXX
 SG_ INV_Diag_Segment M : 8|8@1+ (1,0) [0|5] "" Vector__XXX
 SG_ INV_Diag_Record : 0|8@1+ (1,0) [0|160] "" Vector__XXX

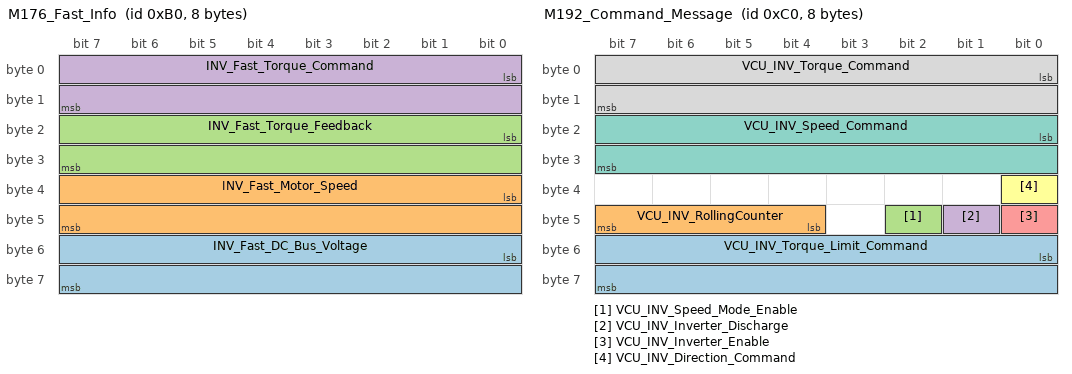
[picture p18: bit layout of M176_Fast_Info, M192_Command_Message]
BO_ 176 M176_Fast_Info: 8 INV
 SG_ INV_Fast_DC_Bus_Voltage : 48|16@1- (0.1,0) [-3276.8|3276.7] "voltage:V" Vector__XXX
 SG_ INV_Fast_Motor_Speed : 32|16@1- (1,0) [-32768|32767] "angular_speed:rpm" Vector__XXX
 SG_ INV_Fast_Torque_Feedback : 16|16@1- (0.1,0) [-3276.8|3276.7] "torque:N.m" Vector__XXX
 SG_ INV_Fast_Torque_Command : 0|16@1- (0.1,0) [-3276.8|3276.7] "torque:N.m" Vector__XXX

BO_ 192 M192_Command_Message: 8 VCU
 SG_ VCU_INV_Torque_Limit_Command : 48|16@1- (0.1,0) [-3276.8|3276.7] "torque:N.m" Vector__XXX
 SG_ VCU_INV_RollingCounter : 44|4@1+ (1,0) [0|15] "" Vector__XXX
 SG_ VCU_INV_Speed_Mode_Enable : 42|1@1+ (1,0) [0|1] "" Vector__XXX
 SG_ VCU_INV_Inverter_Discharge : 41|1@1+ (1,0) [0|1] "" Vector__XXX
 SG_ VCU_INV_Inverter_Enable : 40|1@1+ (1,0) [0|1] "Bit" Vector__XXX
 SG_ VCU_INV_Direction_Command : 32|1@1+ (1,0) [0|1] "Bit" Vector__XXX
 SG_ VCU_INV_Speed_Command : 16|16@1- (1,0) [-32768|32767] "rpm" Vector__XXX
 SG_ VCU_INV_Torque_Command : 0|16@1- (0.1,0) [-3276.8|3276.7] "torque:N.m" Vector__XXX

BO_ 193 M193_Read_Write_Param_Command: 8 VCU
 SG_ VCU_INV_Data_Command : 32|16@1- (1,0) [-32768|32767] "" Vector__XXX
 SG_ VCU_INV_Read_Write_Command : 16|1@1+ (1,0) [0|1] "" Vector__XXX
 SG_ VCU_INV_Parameter_Address_Comman : 0|16@1+ (1,0) [0|65535] "" Vector__XXX

BO_ 194 M194_Read_Write_Param_Response: 8 INV
 SG_ INV_Data_Response : 32|16@1- (1,0) [-32768|32767] "" Vector__XXX
 SG_ INV_Write_Success : 16|1@1+ (1,0) [0|1] "" Vector__XXX
 SG_ INV_Parameter_Address_Response : 0|16@1+ (1,0) [0|65535] "" Vector__XXX

BO_ 208 pcu_heartbeat: 8 PCU
 SG_ error63 : 63|1@1+ (1,0) [0|0] "" Vector__XXX
 SG_ error62 : 62|1@1+ (1,0) [0|0] "" Vector__XXX
 SG_ error61 : 61|1@1+ (1,0) [0|0] "" Vector__XXX
 SG_ error60 : 60|1@1+ (1,0) [0|0] "" Vector__XXX
 SG_ error59 : 59|1@1+ (1,0) [0|0] "" Vector__XXX
 SG_ error58 : 58|1@1+ (1,0) [0|0] "" Vector__XXX
 SG_ error57 : 57|1@1+ (1,0) [0|0] "" Vector__XXX
 SG_ error56 : 56|1@1+ (1,0) [0|0] "" Vector__XXX
 SG_ error55 : 55|1@1+ (1,0) [0|0] "" Vector__XXX
 SG_ error54 : 54|1@1+ (1,0) [0|0] "" Vector__XXX
 SG_ error53 : 53|1@1+ (1,0) [0|0] "" Vector__XXX
 SG_ error52 : 52|1@1+ (1,0) [0|0] "" Vector__XXX
 SG_ error51 : 51|1@1+ (1,0) [0|0] "" Vector__XXX
 SG_ error50 : 50|1@1+ (1,0) [0|0] "" Vector__XXX
 SG_ error49 : 49|1@1+ (1,0) [0|0] "" Vector__XXX
 SG_ error48 : 48|1@1+ (1,0) [0|0] "" Vector__XXX
 SG_ error47 : 47|1@1+ (1,0) [0|0] "" Vector__XXX
 SG_ error46 : 46|1@1+ (1,0) [0|0] "" Vector__XXX
 SG_ error45 : 45|1@1+ (1,0) [0|0] "" Vector__XXX
 SG_ error44 : 44|1@1+ (1,0) [0|0] "" Vector__XXX
 SG_ error43 : 43|1@1+ (1,0) [0|0] "" Vector__XXX
 SG_ error42 : 42|1@1+ (1,0) [0|0] "" Vector__XXX
 SG_ error41 : 41|1@1+ (1,0) [0|0] "" Vector__XXX
 SG_ error40 : 40|1@1+ (1,0) [0|0] "" Vector__XXX
 SG_ error39 : 39|1@1+ (1,0) [0|0] "" Vector__XXX
 SG_ error38 : 38|1@1+ (1,0) [0|0] "" Vector__XXX
 SG_ error37 : 37|1@1+ (1,0) [0|0] "" Vector__XXX
 SG_ error36 : 36|1@1+ (1,0) [0|0] "" Vector__XXX
 SG_ error35 : 35|1@1+ (1,0) [0|0] "" Vector__XXX
 SG_ error34 : 34|1@1+ (1,0) [0|0] "" Vector__XXX
 SG_ error33 : 33|1@1+ (1,0) [0|0] "" Vector__XXX
 SG_ error32 : 32|1@1+ (1,0) [0|0] "" Vector__XXX
 SG_ error31 : 31|1@1+ (1,0) [0|0] "" Vector__XXX
 SG_ error30 : 30|1@1+ (1,0) [0|0] "" Vector__XXX
 SG_ error29 : 29|1@1+ (1,0) [0|0] "" Vector__XXX
 SG_ error28 : 28|1@1+ (1,0) [0|0] "" Vector__XXX
 SG_ error27 : 27|1@1+ (1,0) [0|0] "" Vector__XXX
 SG_ error26 : 26|1@1+ (1,0) [0|0] "" Vector__XXX
 SG_ error25 : 25|1@1+ (1,0) [0|0] "" Vector__XXX
 SG_ error24 : 24|1@1+ (1,0) [0|0] "" Vector__XXX
 SG_ error23 : 23|1@1+ (1,0) [0|0] "" Vector__XXX
 SG_ error22 : 22|1@1+ (1,0) [0|0] "" Vector__XXX
 SG_ error21 : 21|1@1+ (1,0) [0|0] "" Vector__XXX
 SG_ error20 : 20|1@1+ (1,0) [0|0] "" Vector__XXX
 SG_ error19 : 19|1@1+ (1,0) [0|0] "" Vector__XXX
 SG_ error18 : 18|1@1+ (1,0) [0|0] "" Vector__XXX
 SG_ error17 : 17|1@1+ (1,0) [0|0] "" Vector__XXX
 SG_ error16 : 16|1@1+ (1,0) [0|0] "" Vector__XXX
 SG_ error15 : 15|1@1+ (1,0) [0|0] "" Vector__XXX
 SG_ error14 : 14|1@1+ (1,0) [0|0] "" Vector__XXX
 SG_ error13 : 13|1@1+ (1,0) [0|0] "" Vector__XXX
 SG_ error12 : 12|1@1+ (1,0) [0|0] "" Vector__XXX
 SG_ error11 : 11|1@1+ (1,0) [0|0] "" Vector__XXX
 SG_ error10 : 10|1@1+ (1,0) [0|0] "" Vector__XXX
 SG_ error9 : 9|1@1+ (1,0) [0|0] "" Vector__XXX
 SG_ error8 : 8|1@1+ (1,0) [0|0] "" Vector__XXX
 SG_ error7 : 7|1@1+ (1,0) [0|0] "" Vector__XXX
 SG_ error6 : 6|1@1+ (1,0) [0|0] "" Vector__XXX
 SG_ error5 : 5|1@1+ (1,0) [0|0] "" Vector__XXX
 SG_ error4 : 4|1@1+ (1,0) [0|0] "" Vector__XXX
 SG_ error3 : 3|1@1+ (1,0) [0|0] "" Vector__XXX
 SG_ error2 : 2|1@1+ (1,0) [0|0] "" Vector__XXX
 SG_ error1 : 1|1@1+ (1,0) [0|0] "" Vector__XXX
 SG_ error0 : 0|1@1+ (1,0) [0|0] "" Vector__XXX

BO_ 209 dash_heartbeat: 8 DASH
 SG_ error63 : 63|1@1+ (1,0) [0|0] "" Vector__XXX
 SG_ error62 : 62|1@1+ (1,0) [0|0] "" Vector__XXX
 SG_ error61 : 61|1@1+ (1,0) [0|0] "" Vector__XXX
 SG_ error60 : 60|1@1+ (1,0) [0|0] "" Vector__XXX
 SG_ error59 : 59|1@1+ (1,0) [0|0] "" Vector__XXX
 SG_ error58 : 58|1@1+ (1,0) [0|0] "" Vector__XXX
 SG_ error57 : 57|1@1+ (1,0) [0|0] "" Vector__XXX
 SG_ error56 : 56|1@1+ (1,0) [0|0] "" Vector__XXX
 SG_ error55 : 55|1@1+ (1,0) [0|0] "" Vector__XXX
 SG_ error54 : 54|1@1+ (1,0) [0|0] "" Vector__XXX
 SG_ error53 : 53|1@1+ (1,0) [0|0] "" Vector__XXX
 SG_ error52 : 52|1@1+ (1,0) [0|0] "" Vector__XXX
 SG_ error51 : 51|1@1+ (1,0) [0|0] "" Vector__XXX
 SG_ error50 : 50|1@1+ (1,0) [0|0] "" Vector__XXX
 SG_ error49 : 49|1@1+ (1,0) [0|0] "" Vector__XXX
 SG_ error48 : 48|1@1+ (1,0) [0|0] "" Vector__XXX
 SG_ error47 : 47|1@1+ (1,0) [0|0] "" Vector__XXX
 SG_ error46 : 46|1@1+ (1,0) [0|0] "" Vector__XXX
 SG_ error45 : 45|1@1+ (1,0) [0|0] "" Vector__XXX
 SG_ error44 : 44|1@1+ (1,0) [0|0] "" Vector__XXX
 SG_ error43 : 43|1@1+ (1,0) [0|0] "" Vector__XXX
 SG_ error42 : 42|1@1+ (1,0) [0|0] "" Vector__XXX
 SG_ error41 : 41|1@1+ (1,0) [0|0] "" Vector__XXX
 SG_ error40 : 40|1@1+ (1,0) [0|0] "" Vector__XXX
 SG_ error39 : 39|1@1+ (1,0) [0|0] "" Vector__XXX
 SG_ error38 : 38|1@1+ (1,0) [0|0] "" Vector__XXX
 SG_ error37 : 37|1@1+ (1,0) [0|0] "" Vector__XXX
 SG_ error36 : 36|1@1+ (1,0) [0|0] "" Vector__XXX
 SG_ error35 : 35|1@1+ (1,0) [0|0] "" Vector__XXX
 SG_ error34 : 34|1@1+ (1,0) [0|0] "" Vector__XXX
 SG_ error33 : 33|1@1+ (1,0) [0|0] "" Vector__XXX
 SG_ error32 : 32|1@1+ (1,0) [0|0] "" Vector__XXX
 SG_ error31 : 31|1@1+ (1,0) [0|0] "" Vector__XXX
 SG_ error30 : 30|1@1+ (1,0) [0|0] "" Vector__XXX
 SG_ error29 : 29|1@1+ (1,0) [0|0] "" Vector__XXX
 SG_ error28 : 28|1@1+ (1,0) [0|0] "" Vector__XXX
 SG_ error27 : 27|1@1+ (1,0) [0|0] "" Vector__XXX
 SG_ error26 : 26|1@1+ (1,0) [0|0] "" Vector__XXX
 SG_ error25 : 25|1@1+ (1,0) [0|0] "" Vector__XXX
 SG_ error24 : 24|1@1+ (1,0) [0|0] "" Vector__XXX
 SG_ error23 : 23|1@1+ (1,0) [0|0] "" Vector__XXX
 SG_ error22 : 22|1@1+ (1,0) [0|0] "" Vector__XXX
 SG_ error21 : 21|1@1+ (1,0) [0|0] "" Vector__XXX
 SG_ error20 : 20|1@1+ (1,0) [0|0] "" Vector__XXX
 SG_ error19 : 19|1@1+ (1,0) [0|0] "" Vector__XXX
 SG_ error18 : 18|1@1+ (1,0) [0|0] "" Vector__XXX
 SG_ error17 : 17|1@1+ (1,0) [0|0] "" Vector__XXX
 SG_ error16 : 16|1@1+ (1,0) [0|0] "" Vector__XXX
 SG_ error15 : 15|1@1+ (1,0) [0|0] "" Vector__XXX
 SG_ error14 : 14|1@1+ (1,0) [0|0] "" Vector__XXX
 SG_ error13 : 13|1@1+ (1,0) [0|0] "" Vector__XXX
 SG_ error12 : 12|1@1+ (1,0) [0|0] "" Vector__XXX
 SG_ error11 : 11|1@1+ (1,0) [0|0] "" Vector__XXX
 SG_ error10 : 10|1@1+ (1,0) [0|0] "" Vector__XXX
 SG_ error9 : 9|1@1+ (1,0) [0|0] "" Vector__XXX
 SG_ error8 : 8|1@1+ (1,0) [0|0] "" Vector__XXX
 SG_ error7 : 7|1@1+ (1,0) [0|0] "" Vector__XXX
 SG_ error6 : 6|1@1+ (1,0) [0|0] "" Vector__XXX
 SG_ error5 : 5|1@1+ (1,0) [0|0] "" Vector__XXX
 SG_ error4 : 4|1@1+ (1,0) [0|0] "" Vector__XXX
 SG_ error3 : 3|1@1+ (1,0) [0|0] "" Vector__XXX
 SG_ error2 : 2|1@1+ (1,0) [0|0] "" Vector__XXX
 SG_ error1 : 1|1@1+ (1,0) [0|0] "" Vector__XXX
 SG_ io_expander_error : 0|1@1+ (1,0) [0|0] "" Vector__XXX

BO_ 210 lvpdb_heartbeat: 8 LVPDB
 SG_ error63 : 63|1@1+ (1,0) [0|0] "" Vector__XXX
 SG_ error62 : 62|1@1+ (1,0) [0|0] "" Vector__XXX
 SG_ error61 : 61|1@1+ (1,0) [0|0] "" Vector__XXX
 SG_ error60 : 60|1@1+ (1,0) [0|0] "" Vector__XXX
 SG_ error59 : 59|1@1+ (1,0) [0|0] "" Vector__XXX
 SG_ error58 : 58|1@1+ (1,0) [0|0] "" Vector__XXX
 SG_ error57 : 57|1@1+ (1,0) [0|0] "" Vector__XXX
 SG_ error56 : 56|1@1+ (1,0) [0|0] "" Vector__XXX
 SG_ error55 : 55|1@1+ (1,0) [0|0] "" Vector__XXX
 SG_ error54 : 54|1@1+ (1,0) [0|0] "" Vector__XXX
 SG_ error53 : 53|1@1+ (1,0) [0|0] "" Vector__XXX
 SG_ error52 : 52|1@1+ (1,0) [0|0] "" Vector__XXX
 SG_ error51 : 51|1@1+ (1,0) [0|0] "" Vector__XXX
 SG_ error50 : 50|1@1+ (1,0) [0|0] "" Vector__XXX
 SG_ error49 : 49|1@1+ (1,0) [0|0] "" Vector__XXX
 SG_ error48 : 48|1@1+ (1,0) [0|0] "" Vector__XXX
 SG_ error47 : 47|1@1+ (1,0) [0|0] "" Vector__XXX
 SG_ error46 : 46|1@1+ (1,0) [0|0] "" Vector__XXX
 SG_ error45 : 45|1@1+ (1,0) [0|0] "" Vector__XXX
 SG_ error44 : 44|1@1+ (1,0) [0|0] "" Vector__XXX
 SG_ error43 : 43|1@1+ (1,0) [0|0] "" Vector__XXX
 SG_ error42 : 42|1@1+ (1,0) [0|0] "" Vector__XXX
 SG_ error41 : 41|1@1+ (1,0) [0|0] "" Vector__XXX
 SG_ error40 : 40|1@1+ (1,0) [0|0] "" Vector__XXX
 SG_ error39 : 39|1@1+ (1,0) [0|0] "" Vector__XXX
 SG_ error38 : 38|1@1+ (1,0) [0|0] "" Vector__XXX
 SG_ error37 : 37|1@1+ (1,0) [0|0] "" Vector__XXX
 SG_ error36 : 36|1@1+ (1,0) [0|0] "" Vector__XXX
 SG_ error35 : 35|1@1+ (1,0) [0|0] "" Vector__XXX
 SG_ error34 : 34|1@1+ (1,0) [0|0] "" Vector__XXX
 SG_ error33 : 33|1@1+ (1,0) [0|0] "" Vector__XXX
 SG_ error32 : 32|1@1+ (1,0) [0|0] "" Vector__XXX
 SG_ error31 : 31|1@1+ (1,0) [0|0] "" Vector__XXX
 SG_ error30 : 30|1@1+ (1,0) [0|0] "" Vector__XXX
 SG_ error29 : 29|1@1+ (1,0) [0|0] "" Vector__XXX
 SG_ error28 : 28|1@1+ (1,0) [0|0] "" Vector__XXX
 SG_ error27 : 27|1@1+ (1,0) [0|0] "" Vector__XXX
 SG_ error26 : 26|1@1+ (1,0) [0|0] "" Vector__XXX
 SG_ error25 : 25|1@1+ (1,0) [0|0] "" Vector__XXX
 SG_ error24 : 24|1@1+ (1,0) [0|0] "" Vector__XXX
 SG_ error23 : 23|1@1+ (1,0) [0|0] "" Vector__XXX
 SG_ error22 : 22|1@1+ (1,0) [0|0] "" Vector__XXX
 SG_ error21 : 21|1@1+ (1,0) [0|0] "" Vector__XXX
 SG_ error20 : 20|1@1+ (1,0) [0|0] "" Vector__XXX
 SG_ error19 : 19|1@1+ (1,0) [0|0] "" Vector__XXX
 SG_ error18 : 18|1@1+ (1,0) [0|0] "" Vector__XXX
 SG_ error17 : 17|1@1+ (1,0) [0|0] "" Vector__XXX
 SG_ error16 : 16|1@1+ (1,0) [0|0] "" Vector__XXX
 SG_ dash_state_stale : 15|1@1+ (1,0) [0|0] "" Vector__XXX
 SG_ tps_cp_rf_power_not_good : 14|1@1+ (1,0) [0|0] "" Vector__XXX
 SG_ tps_af1_af2_power_not_good : 13|1@1+ (1,0) [0|0] "" Vector__XXX
 SG_ tps_sm_power_not_good : 12|1@1+ (1,0) [0|0] "" Vector__XXX
 SG_ tps_bm_l_power_not_good : 11|1@1+ (1,0) [0|0] "" Vector__XXX
 SG_ tps_lt_power_not_good : 10|1@1+ (1,0) [0|0] "" Vector__XXX
 SG_ tps_sh_power_not_good : 9|1@1+ (1,0) [0|0] "" Vector__XXX
 SG_ tps_lv_power_not_good : 8|1@1+ (1,0) [0|0] "" Vector__XXX
 SG_ tps_cp_rf_poll_failed : 7|1@1+ (1,0) [0|0] "" Vector__XXX
 SG_ tps_af1_af2_poll_failed : 6|1@1+ (1,0) [0|0] "" Vector__XXX
 SG_ tps_sm_poll_failed : 5|1@1+ (1,0) [0|0] "" Vector__XXX
 SG_ tps_bm_l_poll_failed : 4|1@1+ (1,0) [0|0] "" Vector__XXX
 SG_ tps_lt_poll_failed : 3|1@1+ (1,0) [0|0] "" Vector__XXX
 SG_ tps_sh_poll_failed : 2|1@1+ (1,0) [0|0] "" Vector__XXX
 SG_ tps_lv_poll_failed : 1|1@1+ (1,0) [0|0] "" Vector__XXX
 SG_ tps_init_failed : 0|1@1+ (1,0) [0|0] "" Vector__XXX

BO_ 211 dcu_heartbeat: 8 DCU
 SG_ error63 : 63|1@1+ (1,0) [0|0] "" Vector__XXX
 SG_ error62 : 62|1@1+ (1,0) [0|0] "" Vector__XXX
 SG_ error61 : 61|1@1+ (1,0) [0|0] "" Vector__XXX
 SG_ error60 : 60|1@1+ (1,0) [0|0] "" Vector__XXX
 SG_ error59 : 59|1@1+ (1,0) [0|0] "" Vector__XXX
 SG_ error58 : 58|1@1+ (1,0) [0|0] "" Vector__XXX
 SG_ error57 : 57|1@1+ (1,0) [0|0] "" Vector__XXX
 SG_ error56 : 56|1@1+ (1,0) [0|0] "" Vector__XXX
 SG_ error55 : 55|1@1+ (1,0) [0|0] "" Vector__XXX
 SG_ error54 : 54|1@1+ (1,0) [0|0] "" Vector__XXX
 SG_ error53 : 53|1@1+ (1,0) [0|0] "" Vector__XXX
 SG_ error52 : 52|1@1+ (1,0) [0|0] "" Vector__XXX
 SG_ error51 : 51|1@1+ (1,0) [0|0] "" Vector__XXX
 SG_ error50 : 50|1@1+ (1,0) [0|0] "" Vector__XXX
 SG_ error49 : 49|1@1+ (1,0) [0|0] "" Vector__XXX
 SG_ error48 : 48|1@1+ (1,0) [0|0] "" Vector__XXX
 SG_ error47 : 47|1@1+ (1,0) [0|0] "" Vector__XXX
 SG_ error46 : 46|1@1+ (1,0) [0|0] "" Vector__XXX
 SG_ error45 : 45|1@1+ (1,0) [0|0] "" Vector__XXX
 SG_ error44 : 44|1@1+ (1,0) [0|0] "" Vector__XXX
 SG_ error43 : 43|1@1+ (1,0) [0|0] "" Vector__XXX
 SG_ error42 : 42|1@1+ (1,0) [0|0] "" Vector__XXX
 SG_ error41 : 41|1@1+ (1,0) [0|0] "" Vector__XXX
 SG_ error40 : 40|1@1+ (1,0) [0|0] "" Vector__XXX
 SG_ error39 : 39|1@1+ (1,0) [0|0] "" Vector__XXX
 SG_ error38 : 38|1@1+ (1,0) [0|0] "" Vector__XXX
 SG_ error37 : 37|1@1+ (1,0) [0|0] "" Vector__XXX
 SG_ error36 : 36|1@1+ (1,0) [0|0] "" Vector__XXX
 SG_ error35 : 35|1@1+ (1,0) [0|0] "" Vector__XXX
 SG_ error34 : 34|1@1+ (1,0) [0|0] "" Vector__XXX
 SG_ error33 : 33|1@1+ (1,0) [0|0] "" Vector__XXX
 SG_ error32 : 32|1@1+ (1,0) [0|0] "" Vector__XXX
 SG_ error31 : 31|1@1+ (1,0) [0|0] "" Vector__XXX
 SG_ error30 : 30|1@1+ (1,0) [0|0] "" Vector__XXX
 SG_ error29 : 29|1@1+ (1,0) [0|0] "" Vector__XXX
 SG_ error28 : 28|1@1+ (1,0) [0|0] "" Vector__XXX
 SG_ error27 : 27|1@1+ (1,0) [0|0] "" Vector__XXX
 SG_ error26 : 26|1@1+ (1,0) [0|0] "" Vector__XXX
 SG_ error25 : 25|1@1+ (1,0) [0|0] "" Vector__XXX
 SG_ error24 : 24|1@1+ (1,0) [0|0] "" Vector__XXX
 SG_ error23 : 23|1@1+ (1,0) [0|0] "" Vector__XXX
 SG_ error22 : 22|1@1+ (1,0) [0|0] "" Vector__XXX
 SG_ error21 : 21|1@1+ (1,0) [0|0] "" Vector__XXX
 SG_ error20 : 20|1@1+ (1,0) [0|0] "" Vector__XXX
 SG_ error19 : 19|1@1+ (1,0) [0|0] "" Vector__XXX
 SG_ error18 : 18|1@1+ (1,0) [0|0] "" Vector__XXX
 SG_ error17 : 17|1@1+ (1,0) [0|0] "" Vector__XXX
 SG_ error16 : 16|1@1+ (1,0) [0|0] "" Vector__XXX
 SG_ error15 : 15|1@1+ (1,0) [0|0] "" Vector__XXX
 SG_ error14 : 14|1@1+ (1,0) [0|0] "" Vector__XXX
 SG_ error13 : 13|1@1+ (1,0) [0|0] "" Vector__XXX
 SG_ error12 : 12|1@1+ (1,0) [0|0] "" Vector__XXX
 SG_ error11 : 11|1@1+ (1,0) [0|0] "" Vector__XXX
 SG_ error10 : 10|1@1+ (1,0) [0|0] "" Vector__XXX
 SG_ error9 : 9|1@1+ (1,0) [0|0] "" Vector__XXX
 SG_ error8 : 8|1@1+ (1,0) [0|0] "" Vector__XXX
 SG_ error7 : 7|1@1+ (1,0) [0|0] "" Vector__XXX
 SG_ error6 : 6|1@1+ (1,0) [0|0] "" Vector__XXX
 SG_ error5 : 5|1@1+ (1,0) [0|0] "" Vector__XXX
 SG_ error4 : 4|1@1+ (1,0) [0|0] "" Vector__XXX
 SG_ error3 : 3|1@1+ (1,0) [0|0] "" Vector__XXX
 SG_ error2 : 2|1@1+ (1,0) [0|0] "" Vector__XXX
 SG_ error1 : 1|1@1+ (1,0) [0|0] "" Vector__XXX
 SG_ error0 : 0|1@1+ (1,0) [0|0] "" Vector__XXX

BO_ 212 heartbeat_front: 8 SN_FRONT
 SG_ error63 : 63|1@1+ (1,0) [0|0] "" Vector__XXX
 SG_ error62 : 62|1@1+ (1,0) [0|0] "" Vector__XXX
 SG_ error61 : 61|1@1+ (1,0) [0|0] "" Vector__XXX
 SG_ error60 : 60|1@1+ (1,0) [0|0] "" Vector__XXX
 SG_ error59 : 59|1@1+ (1,0) [0|0] "" Vector__XXX
 SG_ error58 : 58|1@1+ (1,0) [0|0] "" Vector__XXX
 SG_ error57 : 57|1@1+ (1,0) [0|0] "" Vector__XXX
 SG_ error56 : 56|1@1+ (1,0) [0|0] "" Vector__XXX
 SG_ error55 : 55|1@1+ (1,0) [0|0] "" Vector__XXX
 SG_ error54 : 54|1@1+ (1,0) [0|0] "" Vector__XXX
 SG_ error53 : 53|1@1+ (1,0) [0|0] "" Vector__XXX
 SG_ error52 : 52|1@1+ (1,0) [0|0] "" Vector__XXX
 SG_ error51 : 51|1@1+ (1,0) [0|0] "" Vector__XXX
 SG_ error50 : 50|1@1+ (1,0) [0|0] "" Vector__XXX
 SG_ error49 : 49|1@1+ (1,0) [0|0] "" Vector__XXX
 SG_ error48 : 48|1@1+ (1,0) [0|0] "" Vector__XXX
 SG_ error47 : 47|1@1+ (1,0) [0|0] "" Vector__XXX
 SG_ error46 : 46|1@1+ (1,0) [0|0] "" Vector__XXX
 SG_ error45 : 45|1@1+ (1,0) [0|0] "" Vector__XXX
 SG_ error44 : 44|1@1+ (1,0) [0|0] "" Vector__XXX
 SG_ error43 : 43|1@1+ (1,0) [0|0] "" Vector__XXX
 SG_ error42 : 42|1@1+ (1,0) [0|0] "" Vector__XXX
 SG_ error41 : 41|1@1+ (1,0) [0|0] "" Vector__XXX
 SG_ error40 : 40|1@1+ (1,0) [0|0] "" Vector__XXX
 SG_ error39 : 39|1@1+ (1,0) [0|0] "" Vector__XXX
 SG_ error38 : 38|1@1+ (1,0) [0|0] "" Vector__XXX
 SG_ error37 : 37|1@1+ (1,0) [0|0] "" Vector__XXX
 SG_ error36 : 36|1@1+ (1,0) [0|0] "" Vector__XXX
 SG_ error35 : 35|1@1+ (1,0) [0|0] "" Vector__XXX
 SG_ error34 : 34|1@1+ (1,0) [0|0] "" Vector__XXX
 SG_ error33 : 33|1@1+ (1,0) [0|0] "" Vector__XXX
 SG_ error32 : 32|1@1+ (1,0) [0|0] "" Vector__XXX
 SG_ error31 : 31|1@1+ (1,0) [0|0] "" Vector__XXX
 SG_ error30 : 30|1@1+ (1,0) [0|0] "" Vector__XXX
 SG_ error29 : 29|1@1+ (1,0) [0|0] "" Vector__XXX
 SG_ error28 : 28|1@1+ (1,0) [0|0] "" Vector__XXX
 SG_ error27 : 27|1@1+ (1,0) [0|0] "" Vector__XXX
 SG_ error26 : 26|1@1+ (1,0) [0|0] "" Vector__XXX
 SG_ error25 : 25|1@1+ (1,0) [0|0] "" Vector__XXX
 SG_ error24 : 24|1@1+ (1,0) [0|0] "" Vector__XXX
 SG_ error23 : 23|1@1+ (1,0) [0|0] "" Vector__XXX
 SG_ error22 : 22|1@1+ (1,0) [0|0] "" Vector__XXX
 SG_ error21 : 21|1@1+ (1,0) [0|0] "" Vector__XXX
 SG_ error20 : 20|1@1+ (1,0) [0|0] "" Vector__XXX
 SG_ error19 : 19|1@1+ (1,0) [0|0] "" Vector__XXX
 SG_ can_rx_overflow : 18|1@1+ (1,0) [0|0] "" Vector__XXX
 SG_ can_tx_overflow : 17|1@1+ (1,0) [0|0] "" Vector__XXX
 SG_ can_bus_off : 16|1@1+ (1,0) [0|0] "" Vector__XXX
 SG_ error15 : 15|1@1+ (1,0) [0|0] "" Vector__XXX
 SG_ error14 : 14|1@1+ (1,0) [0|0] "" Vector__XXX
 SG_ error13 : 13|1@1+ (1,0) [0|0] "" Vector__XXX
 SG_ wss_right_no_signal : 12|1@1+ (1,0) [0|0] "" Vector__XXX
 SG_ wss_left_no_signal : 11|1@1+ (1,0) [0|0] "" Vector__XXX
 SG_ gps_link_slow : 10|1@1+ (1,0) [0|0] "" Vector__XXX
 SG_ gps_stale : 9|1@1+ (1,0) [0|0] "" Vector__XXX
 SG_ gps_no_fix : 8|1@1+ (1,0) [0|0] "" Vector__XXX
 SG_ error7 : 7|1@1+ (1,0) [0|0] "" Vector__XXX
 SG_ lp_out_of_range : 6|1@1+ (1,0) [0|0] "" Vector__XXX
 SG_ fusion_uncalibrated : 5|1@1+ (1,0) [0|0] "" Vector__XXX
 SG_ gps_init_failed : 4|1@1+ (1,0) [0|0] "" Vector__XXX
 SG_ mag_read_failed : 3|1@1+ (1,0) [0|0] "" Vector__XXX
 SG_ mag_init_failed : 2|1@1+ (1,0) [0|0] "" Vector__XXX
 SG_ imu_read_failed : 1|1@1+ (1,0) [0|0] "" Vector__XXX
 SG_ imu_init_failed : 0|1@1+ (1,0) [0|0] "" Vector__XXX

BO_ 213 heartbeat_rear: 8 SN_REAR
 SG_ error63 : 63|1@1+ (1,0) [0|0] "" Vector__XXX
 SG_ error62 : 62|1@1+ (1,0) [0|0] "" Vector__XXX
 SG_ error61 : 61|1@1+ (1,0) [0|0] "" Vector__XXX
 SG_ error60 : 60|1@1+ (1,0) [0|0] "" Vector__XXX
 SG_ error59 : 59|1@1+ (1,0) [0|0] "" Vector__XXX
 SG_ error58 : 58|1@1+ (1,0) [0|0] "" Vector__XXX
 SG_ error57 : 57|1@1+ (1,0) [0|0] "" Vector__XXX
 SG_ error56 : 56|1@1+ (1,0) [0|0] "" Vector__XXX
 SG_ error55 : 55|1@1+ (1,0) [0|0] "" Vector__XXX
 SG_ error54 : 54|1@1+ (1,0) [0|0] "" Vector__XXX
 SG_ error53 : 53|1@1+ (1,0) [0|0] "" Vector__XXX
 SG_ error52 : 52|1@1+ (1,0) [0|0] "" Vector__XXX
 SG_ error51 : 51|1@1+ (1,0) [0|0] "" Vector__XXX
 SG_ error50 : 50|1@1+ (1,0) [0|0] "" Vector__XXX
 SG_ error49 : 49|1@1+ (1,0) [0|0] "" Vector__XXX
 SG_ error48 : 48|1@1+ (1,0) [0|0] "" Vector__XXX
 SG_ error47 : 47|1@1+ (1,0) [0|0] "" Vector__XXX
 SG_ error46 : 46|1@1+ (1,0) [0|0] "" Vector__XXX
 SG_ error45 : 45|1@1+ (1,0) [0|0] "" Vector__XXX
 SG_ error44 : 44|1@1+ (1,0) [0|0] "" Vector__XXX
 SG_ error43 : 43|1@1+ (1,0) [0|0] "" Vector__XXX
 SG_ error42 : 42|1@1+ (1,0) [0|0] "" Vector__XXX
 SG_ error41 : 41|1@1+ (1,0) [0|0] "" Vector__XXX
 SG_ error40 : 40|1@1+ (1,0) [0|0] "" Vector__XXX
 SG_ error39 : 39|1@1+ (1,0) [0|0] "" Vector__XXX
 SG_ error38 : 38|1@1+ (1,0) [0|0] "" Vector__XXX
 SG_ error37 : 37|1@1+ (1,0) [0|0] "" Vector__XXX
 SG_ error36 : 36|1@1+ (1,0) [0|0] "" Vector__XXX
 SG_ error35 : 35|1@1+ (1,0) [0|0] "" Vector__XXX
 SG_ error34 : 34|1@1+ (1,0) [0|0] "" Vector__XXX
 SG_ error33 : 33|1@1+ (1,0) [0|0] "" Vector__XXX
 SG_ error32 : 32|1@1+ (1,0) [0|0] "" Vector__XXX
 SG_ error31 : 31|1@1+ (1,0) [0|0] "" Vector__XXX
 SG_ error30 : 30|1@1+ (1,0) [0|0] "" Vector__XXX
 SG_ error29 : 29|1@1+ (1,0) [0|0] "" Vector__XXX
 SG_ error28 : 28|1@1+ (1,0) [0|0] "" Vector__XXX
 SG_ error27 : 27|1@1+ (1,0) [0|0] "" Vector__XXX
 SG_ error26 : 26|1@1+ (1,0) [0|0] "" Vector__XXX
 SG_ error25 : 25|1@1+ (1,0) [0|0] "" Vector__XXX
 SG_ error24 : 24|1@1+ (1,0) [0|0] "" Vector__XXX
 SG_ error23 : 23|1@1+ (1,0) [0|0] "" Vector__XXX
 SG_ error22 : 22|1@1+ (1,0) [0|0] "" Vector__XXX
 SG_ error21 : 21|1@1+ (1,0) [0|0] "" Vector__XXX
 SG_ error20 : 20|1@1+ (1,0) [0|0] "" Vector__XXX
 SG_ error19 : 19|1@1+ (1,0) [0|0] "" Vector__XXX
 SG_ can_rx_overflow : 18|1@1+ (1,0) [0|0] "" Vector__XXX
 SG_ can_tx_overflow : 17|1@1+ (1,0) [0|0] "" Vector__XXX
 SG_ can_bus_off : 16|1@1+ (1,0) [0|0] "" Vector__XXX
 SG_ error15 : 15|1@1+ (1,0) [0|0] "" Vector__XXX
 SG_ error14 : 14|1@1+ (1,0) [0|0] "" Vector__XXX
 SG_ error13 : 13|1@1+ (1,0) [0|0] "" Vector__XXX
 SG_ wss_right_no_signal : 12|1@1+ (1,0) [0|0] "" Vector__XXX
 SG_ wss_left_no_signal : 11|1@1+ (1,0) [0|0] "" Vector__XXX
 SG_ gps_link_slow : 10|1@1+ (1,0) [0|0] "" Vector__XXX
 SG_ gps_stale : 9|1@1+ (1,0) [0|0] "" Vector__XXX
 SG_ gps_no_fix : 8|1@1+ (1,0) [0|0] "" Vector__XXX
 SG_ error7 : 7|1@1+ (1,0) [0|0] "" Vector__XXX
 SG_ lp_out_of_range : 6|1@1+ (1,0) [0|0] "" Vector__XXX
 SG_ fusion_uncalibrated : 5|1@1+ (1,0) [0|0] "" Vector__XXX
 SG_ gps_init_failed : 4|1@1+ (1,0) [0|0] "" Vector__XXX
 SG_ mag_read_failed : 3|1@1+ (1,0) [0|0] "" Vector__XXX
 SG_ mag_init_failed : 2|1@1+ (1,0) [0|0] "" Vector__XXX
 SG_ imu_read_failed : 1|1@1+ (1,0) [0|0] "" Vector__XXX
 SG_ imu_init_failed : 0|1@1+ (1,0) [0|0] "" Vector__XXX

BO_ 224 FEB_PING_PONG_counter1: 8 BMS
 SG_ counter : 0|32@1- (1,0) [0|0] "" Vector__XXX

BO_ 225 FEB_PING_PONG_counter2: 8 BMS
 SG_ counter : 0|32@1- (1,0) [0|0] "" Vector__XXX

BO_ 226 FEB_PING_PONG_counter3: 8 BMS
 SG_ counter : 0|32@1- (1,0) [0|0] "" Vector__XXX

BO_ 227 FEB_PING_PONG_counter4: 8 BMS
 SG_ counter : 0|32@1- (1,0) [0|0] "" Vector__XXX

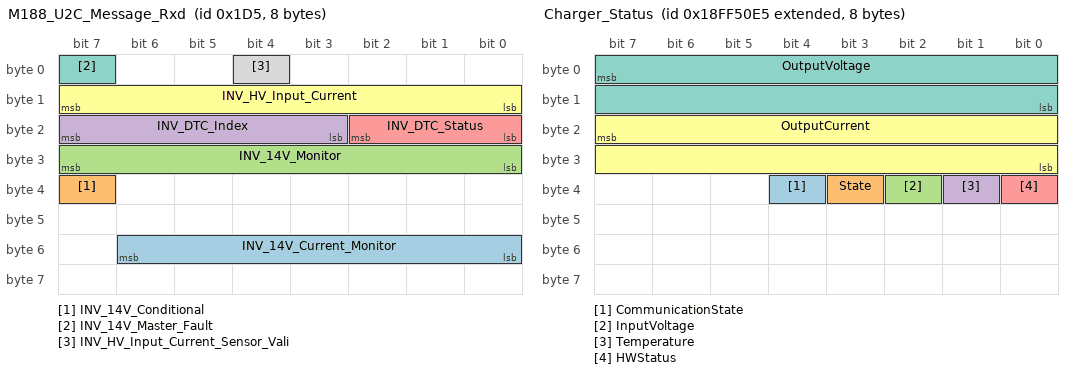
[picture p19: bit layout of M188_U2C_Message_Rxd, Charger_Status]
BO_ 469 M188_U2C_Message_Rxd: 8 U2C
 SG_ INV_14V_Current_Monitor : 48|7@1+ (1,0) [0|127] "" Vector__XXX
 SG_ INV_14V_Conditional : 39|1@1+ (1,0) [0|1] "" Vector__XXX
 SG_ INV_14V_Monitor : 24|8@1+ (1,0) [0|255] "" Vector__XXX
 SG_ INV_DTC_Index : 19|5@1+ (1,0) [0|31] "" Vector__XXX
 SG_ INV_DTC_Status : 16|3@1+ (1,0) [0|7] "" Vector__XXX
 SG_ INV_HV_Input_Current : 8|8@1+ (1,0) [0|255] "" Vector__XXX
 SG_ INV_14V_Master_Fault : 7|1@1+ (1,0) [0|1] "" Vector__XXX
 SG_ INV_HV_Input_Current_Sensor_Vali : 4|1@1+ (1,0) [0|1] "" Vector__XXX

BO_ 471 M187_U2C_Command_Txd: 8 INV
 SG_ U2C_Setpoint_Calc : 8|8@1+ (1,0) [0|255] "" Vector__XXX
 SG_ U2C_ID_Byte : 0|8@1+ (1,0) [0|255] "" Vector__XXX

BO_ 514 BMS_Current_Limit: 8 BMS
 SG_ INV_Max_Charge_Current : 16|16@1+ (1,0) [0|1000] "current:A" Vector__XXX
 SG_ INV_Max_Discharge_Current : 0|16@1+ (1,0) [0|1000] "current:A" Vector__XXX

BO_ 516 bms_cell_voltages: 8 BMS
 SG_ module_10_cell_16 m39 : 50|14@1+ (0.0005,0) [0|0] "V" Vector__XXX
 SG_ module_10_cell_12 m38 : 50|14@1+ (0.0005,0) [0|0] "V" Vector__XXX
 SG_ module_10_cell_8 m37 : 50|14@1+ (0.0005,0) [0|0] "V" Vector__XXX
 SG_ module_10_cell_4 m36 : 50|14@1+ (0.0005,0) [0|0] "V" Vector__XXX
 SG_ module_9_cell_16 m35 : 50|14@1+ (0.0005,0) [0|0] "V" Vector__XXX
 SG_ module_9_cell_12 m34 : 50|14@1+ (0.0005,0) [0|0] "V" Vector__XXX
 SG_ module_9_cell_8 m33 : 50|14@1+ (0.0005,0) [0|0] "V" Vector__XXX
 SG_ module_9_cell_4 m32 : 50|14@1+ (0.0005,0) [0|0] "V" Vector__XXX
 SG_ module_8_cell_16 m31 : 50|14@1+ (0.0005,0) [0|0] "V" Vector__XXX
 SG_ module_8_cell_12 m30 : 50|14@1+ (0.0005,0) [0|0] "V" Vector__XXX
 SG_ module_8_cell_8 m29 : 50|14@1+ (0.0005,0) [0|0] "V" Vector__XXX
 SG_ module_8_cell_4 m28 : 50|14@1+ (0.0005,0) [0|0] "V" Vector__XXX
 SG_ module_7_cell_16 m27 : 50|14@1+ (0.0005,0) [0|0] "V" Vector__XXX
 SG_ module_7_cell_12 m26 : 50|14@1+ (0.0005,0) [0|0] "V" Vector__XXX
 SG_ module_7_cell_8 m25 : 50|14@1+ (0.0005,0) [0|0] "V" Vector__XXX
 SG_ module_7_cell_4 m24 : 50|14@1+ (0.0005,0) [0|0] "V" Vector__XXX
 SG_ module_6_cell_16 m23 : 50|14@1+ (0.0005,0) [0|0] "V" Vector__XXX
 SG_ module_6_cell_12 m22 : 50|14@1+ (0.0005,0) [0|0] "V" Vector__XXX
 SG_ module_6_cell_8 m21 : 50|14@1+ (0.0005,0) [0|0] "V" Vector__XXX
 SG_ module_6_cell_4 m20 : 50|14@1+ (0.0005,0) [0|0] "V" Vector__XXX
 SG_ module_5_cell_16 m19 : 50|14@1+ (0.0005,0) [0|0] "V" Vector__XXX
 SG_ module_5_cell_12 m18 : 50|14@1+ (0.0005,0) [0|0] "V" Vector__XXX
 SG_ module_5_cell_8 m17 : 50|14@1+ (0.0005,0) [0|0] "V" Vector__XXX
 SG_ module_5_cell_4 m16 : 50|14@1+ (0.0005,0) [0|0] "V" Vector__XXX
 SG_ module_4_cell_16 m15 : 50|14@1+ (0.0005,0) [0|0] "V" Vector__XXX
 SG_ module_4_cell_12 m14 : 50|14@1+ (0.0005,0) [0|0] "V" Vector__XXX
 SG_ module_4_cell_8 m13 : 50|14@1+ (0.0005,0) [0|0] "V" Vector__XXX
 SG_ module_4_cell_4 m12 : 50|14@1+ (0.0005,0) [0|0] "V" Vector__XXX
 SG_ module_3_cell_16 m11 : 50|14@1+ (0.0005,0) [0|0] "V" Vector__XXX
 SG_ module_3_cell_12 m10 : 50|14@1+ (0.0005,0) [0|0] "V" Vector__XXX
 SG_ module_3_cell_8 m9 : 50|14@1+ (0.0005,0) [0|0] "V" Vector__XXX
 SG_ module_3_cell_4 m8 : 50|14@1+ (0.0005,0) [0|0] "V" Vector__XXX
 SG_ module_2_cell_16 m7 : 50|14@1+ (0.0005,0) [0|0] "V" Vector__XXX
 SG_ module_2_cell_12 m6 : 50|14@1+ (0.0005,0) [0|0] "V" Vector__XXX
 SG_ module_2_cell_8 m5 : 50|14@1+ (0.0005,0) [0|0] "V" Vector__XXX
 SG_ module_2_cell_4 m4 : 50|14@1+ (0.0005,0) [0|0] "V" Vector__XXX
 SG_ module_1_cell_16 m3 : 50|14@1+ (0.0005,0) [0|0] "V" Vector__XXX
 SG_ module_1_cell_12 m2 : 50|14@1+ (0.0005,0) [0|0] "V" Vector__XXX
 SG_ module_1_cell_8 m1 : 50|14@1+ (0.0005,0) [0|0] "V" Vector__XXX
 SG_ module_1_cell_4 m0 : 50|14@1+ (0.0005,0) [0|0] "V" Vector__XXX
 SG_ module_10_cell_15 m39 : 36|14@1+ (0.0005,0) [0|0] "V" Vector__XXX
 SG_ module_10_cell_11 m38 : 36|14@1+ (0.0005,0) [0|0] "V" Vector__XXX
 SG_ module_10_cell_7 m37 : 36|14@1+ (0.0005,0) [0|0] "V" Vector__XXX
 SG_ module_10_cell_3 m36 : 36|14@1+ (0.0005,0) [0|0] "V" Vector__XXX
 SG_ module_9_cell_15 m35 : 36|14@1+ (0.0005,0) [0|0] "V" Vector__XXX
 SG_ module_9_cell_11 m34 : 36|14@1+ (0.0005,0) [0|0] "V" Vector__XXX
 SG_ module_9_cell_7 m33 : 36|14@1+ (0.0005,0) [0|0] "V" Vector__XXX
 SG_ module_9_cell_3 m32 : 36|14@1+ (0.0005,0) [0|0] "V" Vector__XXX
 SG_ module_8_cell_15 m31 : 36|14@1+ (0.0005,0) [0|0] "V" Vector__XXX
 SG_ module_8_cell_11 m30 : 36|14@1+ (0.0005,0) [0|0] "V" Vector__XXX
 SG_ module_8_cell_7 m29 : 36|14@1+ (0.0005,0) [0|0] "V" Vector__XXX
 SG_ module_8_cell_3 m28 : 36|14@1+ (0.0005,0) [0|0] "V" Vector__XXX
 SG_ module_7_cell_15 m27 : 36|14@1+ (0.0005,0) [0|0] "V" Vector__XXX
 SG_ module_7_cell_11 m26 : 36|14@1+ (0.0005,0) [0|0] "V" Vector__XXX
 SG_ module_7_cell_7 m25 : 36|14@1+ (0.0005,0) [0|0] "V" Vector__XXX
 SG_ module_7_cell_3 m24 : 36|14@1+ (0.0005,0) [0|0] "V" Vector__XXX
 SG_ module_6_cell_15 m23 : 36|14@1+ (0.0005,0) [0|0] "V" Vector__XXX
 SG_ module_6_cell_11 m22 : 36|14@1+ (0.0005,0) [0|0] "V" Vector__XXX
 SG_ module_6_cell_7 m21 : 36|14@1+ (0.0005,0) [0|0] "V" Vector__XXX
 SG_ module_6_cell_3 m20 : 36|14@1+ (0.0005,0) [0|0] "V" Vector__XXX
 SG_ module_5_cell_15 m19 : 36|14@1+ (0.0005,0) [0|0] "V" Vector__XXX
 SG_ module_5_cell_11 m18 : 36|14@1+ (0.0005,0) [0|0] "V" Vector__XXX
 SG_ module_5_cell_7 m17 : 36|14@1+ (0.0005,0) [0|0] "V" Vector__XXX
 SG_ module_5_cell_3 m16 : 36|14@1+ (0.0005,0) [0|0] "V" Vector__XXX
 SG_ module_4_cell_15 m15 : 36|14@1+ (0.0005,0) [0|0] "V" Vector__XXX
 SG_ module_4_cell_11 m14 : 36|14@1+ (0.0005,0) [0|0] "V" Vector__XXX
 SG_ module_4_cell_7 m13 : 36|14@1+ (0.0005,0) [0|0] "V" Vector__XXX
 SG_ module_4_cell_3 m12 : 36|14@1+ (0.0005,0) [0|0] "V" Vector__XXX
 SG_ module_3_cell_15 m11 : 36|14@1+ (0.0005,0) [0|0] "V" Vector__XXX
 SG_ module_3_cell_11 m10 : 36|14@1+ (0.0005,0) [0|0] "V" Vector__XXX
 SG_ module_3_cell_7 m9 : 36|14@1+ (0.0005,0) [0|0] "V" Vector__XXX
 SG_ module_3_cell_3 m8 : 36|14@1+ (0.0005,0) [0|0] "V" Vector__XXX
 SG_ module_2_cell_15 m7 : 36|14@1+ (0.0005,0) [0|0] "V" Vector__XXX
 SG_ module_2_cell_11 m6 : 36|14@1+ (0.0005,0) [0|0] "V" Vector__XXX
 SG_ module_2_cell_7 m5 : 36|14@1+ (0.0005,0) [0|0] "V" Vector__XXX
 SG_ module_2_cell_3 m4 : 36|14@1+ (0.0005,0) [0|0] "V" Vector__XXX
 SG_ module_1_cell_15 m3 : 36|14@1+ (0.0005,0) [0|0] "V" Vector__XXX
 SG_ module_1_cell_11 m2 : 36|14@1+ (0.0005,0) [0|0] "V" Vector__XXX
 SG_ module_1_cell_7 m1 : 36|14@1+ (0.0005,0) [0|0] "V" Vector__XXX
 SG_ module_1_cell_3 m0 : 36|14@1+ (0.0005,0) [0|0] "V" Vector__XXX
 SG_ module_10_cell_14 m39 : 22|14@1+ (0.0005,0) [0|0] "V" Vector__XXX
 SG_ module_10_cell_10 m38 : 22|14@1+ (0.0005,0) [0|0] "V" Vector__XXX
 SG_ module_10_cell_6 m37 : 22|14@1+ (0.0005,0) [0|0] "V" Vector__XXX
 SG_ module_10_cell_2 m36 : 22|14@1+ (0.0005,0) [0|0] "V" Vector__XXX
 SG_ module_9_cell_14 m35 : 22|14@1+ (0.0005,0) [0|0] "V" Vector__XXX
 SG_ module_9_cell_10 m34 : 22|14@1+ (0.0005,0) [0|0] "V" Vector__XXX
 SG_ module_9_cell_6 m33 : 22|14@1+ (0.0005,0) [0|0] "V" Vector__XXX
 SG_ module_9_cell_2 m32 : 22|14@1+ (0.0005,0) [0|0] "V" Vector__XXX
 SG_ module_8_cell_14 m31 : 22|14@1+ (0.0005,0) [0|0] "V" Vector__XXX
 SG_ module_8_cell_10 m30 : 22|14@1+ (0.0005,0) [0|0] "V" Vector__XXX
 SG_ module_8_cell_6 m29 : 22|14@1+ (0.0005,0) [0|0] "V" Vector__XXX
 SG_ module_8_cell_2 m28 : 22|14@1+ (0.0005,0) [0|0] "V" Vector__XXX
 SG_ module_7_cell_14 m27 : 22|14@1+ (0.0005,0) [0|0] "V" Vector__XXX
 SG_ module_7_cell_10 m26 : 22|14@1+ (0.0005,0) [0|0] "V" Vector__XXX
 SG_ module_7_cell_6 m25 : 22|14@1+ (0.0005,0) [0|0] "V" Vector__XXX
 SG_ module_7_cell_2 m24 : 22|14@1+ (0.0005,0) [0|0] "V" Vector__XXX
 SG_ module_6_cell_14 m23 : 22|14@1+ (0.0005,0) [0|0] "V" Vector__XXX
 SG_ module_6_cell_10 m22 : 22|14@1+ (0.0005,0) [0|0] "V" Vector__XXX
 SG_ module_6_cell_6 m21 : 22|14@1+ (0.0005,0) [0|0] "V" Vector__XXX
 SG_ module_6_cell_2 m20 : 22|14@1+ (0.0005,0) [0|0] "V" Vector__XXX
 SG_ module_5_cell_14 m19 : 22|14@1+ (0.0005,0) [0|0] "V" Vector__XXX
 SG_ module_5_cell_10 m18 : 22|14@1+ (0.0005,0) [0|0] "V" Vector__XXX
 SG_ module_5_cell_6 m17 : 22|14@1+ (0.0005,0) [0|0] "V" Vector__XXX
 SG_ module_5_cell_2 m16 : 22|14@1+ (0.0005,0) [0|0] "V" Vector__XXX
 SG_ module_4_cell_14 m15 : 22|14@1+ (0.0005,0) [0|0] "V" Vector__XXX
 SG_ module_4_cell_10 m14 : 22|14@1+ (0.0005,0) [0|0] "V" Vector__XXX
 SG_ module_4_cell_6 m13 : 22|14@1+ (0.0005,0) [0|0] "V" Vector__XXX
 SG_ module_4_cell_2 m12 : 22|14@1+ (0.0005,0) [0|0] "V" Vector__XXX
 SG_ module_3_cell_14 m11 : 22|14@1+ (0.0005,0) [0|0] "V" Vector__XXX
 SG_ module_3_cell_10 m10 : 22|14@1+ (0.0005,0) [0|0] "V" Vector__XXX
 SG_ module_3_cell_6 m9 : 22|14@1+ (0.0005,0) [0|0] "V" Vector__XXX
 SG_ module_3_cell_2 m8 : 22|14@1+ (0.0005,0) [0|0] "V" Vector__XXX
 SG_ module_2_cell_14 m7 : 22|14@1+ (0.0005,0) [0|0] "V" Vector__XXX
 SG_ module_2_cell_10 m6 : 22|14@1+ (0.0005,0) [0|0] "V" Vector__XXX
 SG_ module_2_cell_6 m5 : 22|14@1+ (0.0005,0) [0|0] "V" Vector__XXX
 SG_ module_2_cell_2 m4 : 22|14@1+ (0.0005,0) [0|0] "V" Vector__XXX
 SG_ module_1_cell_14 m3 : 22|14@1+ (0.0005,0) [0|0] "V" Vector__XXX
 SG_ module_1_cell_10 m2 : 22|14@1+ (0.0005,0) [0|0] "V" Vector__XXX
 SG_ module_1_cell_6 m1 : 22|14@1+ (0.0005,0) [0|0] "V" Vector__XXX
 SG_ module_1_cell_2 m0 : 22|14@1+ (0.0005,0) [0|0] "V" Vector__XXX
 SG_ module_10_cell_13 m39 : 8|14@1+ (0.0005,0) [0|0] "V" Vector__XXX
 SG_ module_10_cell_9 m38 : 8|14@1+ (0.0005,0) [0|0] "V" Vector__XXX
 SG_ module_10_cell_5 m37 : 8|14@1+ (0.0005,0) [0|0] "V" Vector__XXX
 SG_ module_10_cell_1 m36 : 8|14@1+ (0.0005,0) [0|0] "V" Vector__XXX
 SG_ module_9_cell_13 m35 : 8|14@1+ (0.0005,0) [0|0] "V" Vector__XXX
 SG_ module_9_cell_9 m34 : 8|14@1+ (0.0005,0) [0|0] "V" Vector__XXX
 SG_ module_9_cell_5 m33 : 8|14@1+ (0.0005,0) [0|0] "V" Vector__XXX
 SG_ module_9_cell_1 m32 : 8|14@1+ (0.0005,0) [0|0] "V" Vector__XXX
 SG_ module_8_cell_13 m31 : 8|14@1+ (0.0005,0) [0|0] "V" Vector__XXX
 SG_ module_8_cell_9 m30 : 8|14@1+ (0.0005,0) [0|0] "V" Vector__XXX
 SG_ module_8_cell_5 m29 : 8|14@1+ (0.0005,0) [0|0] "V" Vector__XXX
 SG_ module_8_cell_1 m28 : 8|14@1+ (0.0005,0) [0|0] "V" Vector__XXX
 SG_ module_7_cell_13 m27 : 8|14@1+ (0.0005,0) [0|0] "V" Vector__XXX
 SG_ module_7_cell_9 m26 : 8|14@1+ (0.0005,0) [0|0] "V" Vector__XXX
 SG_ module_7_cell_5 m25 : 8|14@1+ (0.0005,0) [0|0] "V" Vector__XXX
 SG_ module_7_cell_1 m24 : 8|14@1+ (0.0005,0) [0|0] "V" Vector__XXX
 SG_ module_6_cell_13 m23 : 8|14@1+ (0.0005,0) [0|0] "V" Vector__XXX
 SG_ module_6_cell_9 m22 : 8|14@1+ (0.0005,0) [0|0] "V" Vector__XXX
 SG_ module_6_cell_5 m21 : 8|14@1+ (0.0005,0) [0|0] "V" Vector__XXX
 SG_ module_6_cell_1 m20 : 8|14@1+ (0.0005,0) [0|0] "V" Vector__XXX
 SG_ module_5_cell_13 m19 : 8|14@1+ (0.0005,0) [0|0] "V" Vector__XXX
 SG_ module_5_cell_9 m18 : 8|14@1+ (0.0005,0) [0|0] "V" Vector__XXX
 SG_ module_5_cell_5 m17 : 8|14@1+ (0.0005,0) [0|0] "V" Vector__XXX
 SG_ module_5_cell_1 m16 : 8|14@1+ (0.0005,0) [0|0] "V" Vector__XXX
 SG_ module_4_cell_13 m15 : 8|14@1+ (0.0005,0) [0|0] "V" Vector__XXX
 SG_ module_4_cell_9 m14 : 8|14@1+ (0.0005,0) [0|0] "V" Vector__XXX
 SG_ module_4_cell_5 m13 : 8|14@1+ (0.0005,0) [0|0] "V" Vector__XXX
 SG_ module_4_cell_1 m12 : 8|14@1+ (0.0005,0) [0|0] "V" Vector__XXX
 SG_ module_3_cell_13 m11 : 8|14@1+ (0.0005,0) [0|0] "V" Vector__XXX
 SG_ module_3_cell_9 m10 : 8|14@1+ (0.0005,0) [0|0] "V" Vector__XXX
 SG_ module_3_cell_5 m9 : 8|14@1+ (0.0005,0) [0|0] "V" Vector__XXX
 SG_ module_3_cell_1 m8 : 8|14@1+ (0.0005,0) [0|0] "V" Vector__XXX
 SG_ module_2_cell_13 m7 : 8|14@1+ (0.0005,0) [0|0] "V" Vector__XXX
 SG_ module_2_cell_9 m6 : 8|14@1+ (0.0005,0) [0|0] "V" Vector__XXX
 SG_ module_2_cell_5 m5 : 8|14@1+ (0.0005,0) [0|0] "V" Vector__XXX
 SG_ module_2_cell_1 m4 : 8|14@1+ (0.0005,0) [0|0] "V" Vector__XXX
 SG_ module_1_cell_13 m3 : 8|14@1+ (0.0005,0) [0|0] "V" Vector__XXX
 SG_ module_1_cell_9 m2 : 8|14@1+ (0.0005,0) [0|0] "V" Vector__XXX
 SG_ module_1_cell_5 m1 : 8|14@1+ (0.0005,0) [0|0] "V" Vector__XXX
 SG_ module_1_cell_1 m0 : 8|14@1+ (0.0005,0) [0|0] "V" Vector__XXX
 SG_ page M : 0|8@1+ (1,0) [0|0] "" Vector__XXX

BO_ 517 bms_cell_temperatures: 8 BMS
 SG_ module_10_temp_40 m108 : 50|14@1- (0.1,0) [0|0] "degC" Vector__XXX
 SG_ module_10_temp_36 m107 : 50|14@1- (0.1,0) [0|0] "degC" Vector__XXX
 SG_ module_10_temp_32 m106 : 50|14@1- (0.1,0) [0|0] "degC" Vector__XXX
 SG_ module_10_temp_28 m105 : 50|14@1- (0.1,0) [0|0] "degC" Vector__XXX
 SG_ module_10_temp_24 m104 : 50|14@1- (0.1,0) [0|0] "degC" Vector__XXX
 SG_ module_10_temp_20 m103 : 50|14@1- (0.1,0) [0|0] "degC" Vector__XXX
 SG_ module_10_temp_16 m102 : 50|14@1- (0.1,0) [0|0] "degC" Vector__XXX
 SG_ module_10_temp_12 m101 : 50|14@1- (0.1,0) [0|0] "degC" Vector__XXX
 SG_ module_10_temp_8 m100 : 50|14@1- (0.1,0) [0|0] "degC" Vector__XXX
 SG_ module_10_temp_4 m99 : 50|14@1- (0.1,0) [0|0] "degC" Vector__XXX
 SG_ module_9_temp_40 m97 : 50|14@1- (0.1,0) [0|0] "degC" Vector__XXX
 SG_ module_9_temp_36 m96 : 50|14@1- (0.1,0) [0|0] "degC" Vector__XXX
 SG_ module_9_temp_32 m95 : 50|14@1- (0.1,0) [0|0] "degC" Vector__XXX
 SG_ module_9_temp_28 m94 : 50|14@1- (0.1,0) [0|0] "degC" Vector__XXX
 SG_ module_9_temp_24 m93 : 50|14@1- (0.1,0) [0|0] "degC" Vector__XXX
 SG_ module_9_temp_20 m92 : 50|14@1- (0.1,0) [0|0] "degC" Vector__XXX
 SG_ module_9_temp_16 m91 : 50|14@1- (0.1,0) [0|0] "degC" Vector__XXX
 SG_ module_9_temp_12 m90 : 50|14@1- (0.1,0) [0|0] "degC" Vector__XXX
 SG_ module_9_temp_8 m89 : 50|14@1- (0.1,0) [0|0] "degC" Vector__XXX
 SG_ module_9_temp_4 m88 : 50|14@1- (0.1,0) [0|0] "degC" Vector__XXX
 SG_ module_8_temp_40 m86 : 50|14@1- (0.1,0) [0|0] "degC" Vector__XXX
 SG_ module_8_temp_36 m85 : 50|14@1- (0.1,0) [0|0] "degC" Vector__XXX
 SG_ module_8_temp_32 m84 : 50|14@1- (0.1,0) [0|0] "degC" Vector__XXX
 SG_ module_8_temp_28 m83 : 50|14@1- (0.1,0) [0|0] "degC" Vector__XXX
 SG_ module_8_temp_24 m82 : 50|14@1- (0.1,0) [0|0] "degC" Vector__XXX
 SG_ module_8_temp_20 m81 : 50|14@1- (0.1,0) [0|0] "degC" Vector__XXX
 SG_ module_8_temp_16 m80 : 50|14@1- (0.1,0) [0|0] "degC" Vector__XXX
 SG_ module_8_temp_12 m79 : 50|14@1- (0.1,0) [0|0] "degC" Vector__XXX
 SG_ module_8_temp_8 m78 : 50|14@1- (0.1,0) [0|0] "degC" Vector__XXX
 SG_ module_8_temp_4 m77 : 50|14@1- (0.1,0) [0|0] "degC" Vector__XXX
 SG_ module_7_temp_40 m75 : 50|14@1- (0.1,0) [0|0] "degC" Vector__XXX
 SG_ module_7_temp_36 m74 : 50|14@1- (0.1,0) [0|0] "degC" Vector__XXX
 SG_ module_7_temp_32 m73 : 50|14@1- (0.1,0) [0|0] "degC" Vector__XXX
 SG_ module_7_temp_28 m72 : 50|14@1- (0.1,0) [0|0] "degC" Vector__XXX
 SG_ module_7_temp_24 m71 : 50|14@1- (0.1,0) [0|0] "degC" Vector__XXX
 SG_ module_7_temp_20 m70 : 50|14@1- (0.1,0) [0|0] "degC" Vector__XXX
 SG_ module_7_temp_16 m69 : 50|14@1- (0.1,0) [0|0] "degC" Vector__XXX
 SG_ module_7_temp_12 m68 : 50|14@1- (0.1,0) [0|0] "degC" Vector__XXX
 SG_ module_7_temp_8 m67 : 50|14@1- (0.1,0) [0|0] "degC" Vector__XXX
 SG_ module_7_temp_4 m66 : 50|14@1- (0.1,0) [0|0] "degC" Vector__XXX
 SG_ module_6_temp_40 m64 : 50|14@1- (0.1,0) [0|0] "degC" Vector__XXX
 SG_ module_6_temp_36 m63 : 50|14@1- (0.1,0) [0|0] "degC" Vector__XXX
 SG_ module_6_temp_32 m62 : 50|14@1- (0.1,0) [0|0] "degC" Vector__XXX
 SG_ module_6_temp_28 m61 : 50|14@1- (0.1,0) [0|0] "degC" Vector__XXX
 SG_ module_6_temp_24 m60 : 50|14@1- (0.1,0) [0|0] "degC" Vector__XXX
 SG_ module_6_temp_20 m59 : 50|14@1- (0.1,0) [0|0] "degC" Vector__XXX
 SG_ module_6_temp_16 m58 : 50|14@1- (0.1,0) [0|0] "degC" Vector__XXX
 SG_ module_6_temp_12 m57 : 50|14@1- (0.1,0) [0|0] "degC" Vector__XXX
 SG_ module_6_temp_8 m56 : 50|14@1- (0.1,0) [0|0] "degC" Vector__XXX
 SG_ module_6_temp_4 m55 : 50|14@1- (0.1,0) [0|0] "degC" Vector__XXX
 SG_ module_5_temp_40 m53 : 50|14@1- (0.1,0) [0|0] "degC" Vector__XXX
 SG_ module_5_temp_36 m52 : 50|14@1- (0.1,0) [0|0] "degC" Vector__XXX
 SG_ module_5_temp_32 m51 : 50|14@1- (0.1,0) [0|0] "degC" Vector__XXX
 SG_ module_5_temp_28 m50 : 50|14@1- (0.1,0) [0|0] "degC" Vector__XXX
 SG_ module_5_temp_24 m49 : 50|14@1- (0.1,0) [0|0] "degC" Vector__XXX
 SG_ module_5_temp_20 m48 : 50|14@1- (0.1,0) [0|0] "degC" Vector__XXX
 SG_ module_5_temp_16 m47 : 50|14@1- (0.1,0) [0|0] "degC" Vector__XXX
 SG_ module_5_temp_12 m46 : 50|14@1- (0.1,0) [0|0] "degC" Vector__XXX
 SG_ module_5_temp_8 m45 : 50|14@1- (0.1,0) [0|0] "degC" Vector__XXX
 SG_ module_5_temp_4 m44 : 50|14@1- (0.1,0) [0|0] "degC" Vector__XXX
 SG_ module_4_temp_40 m42 : 50|14@1- (0.1,0) [0|0] "degC" Vector__XXX
 SG_ module_4_temp_36 m41 : 50|14@1- (0.1,0) [0|0] "degC" Vector__XXX
 SG_ module_4_temp_32 m40 : 50|14@1- (0.1,0) [0|0] "degC" Vector__XXX
 SG_ module_4_temp_28 m39 : 50|14@1- (0.1,0) [0|0] "degC" Vector__XXX
 SG_ module_4_temp_24 m38 : 50|14@1- (0.1,0) [0|0] "degC" Vector__XXX
 SG_ module_4_temp_20 m37 : 50|14@1- (0.1,0) [0|0] "degC" Vector__XXX
 SG_ module_4_temp_16 m36 : 50|14@1- (0.1,0) [0|0] "degC" Vector__XXX
 SG_ module_4_temp_12 m35 : 50|14@1- (0.1,0) [0|0] "degC" Vector__XXX
 SG_ module_4_temp_8 m34 : 50|14@1- (0.1,0) [0|0] "degC" Vector__XXX
 SG_ module_4_temp_4 m33 : 50|14@1- (0.1,0) [0|0] "degC" Vector__XXX
 SG_ module_3_temp_40 m31 : 50|14@1- (0.1,0) [0|0] "degC" Vector__XXX
 SG_ module_3_temp_36 m30 : 50|14@1- (0.1,0) [0|0] "degC" Vector__XXX
 SG_ module_3_temp_32 m29 : 50|14@1- (0.1,0) [0|0] "degC" Vector__XXX
 SG_ module_3_temp_28 m28 : 50|14@1- (0.1,0) [0|0] "degC" Vector__XXX
 SG_ module_3_temp_24 m27 : 50|14@1- (0.1,0) [0|0] "degC" Vector__XXX
 SG_ module_3_temp_20 m26 : 50|14@1- (0.1,0) [0|0] "degC" Vector__XXX
 SG_ module_3_temp_16 m25 : 50|14@1- (0.1,0) [0|0] "degC" Vector__XXX
 SG_ module_3_temp_12 m24 : 50|14@1- (0.1,0) [0|0] "degC" Vector__XXX
 SG_ module_3_temp_8 m23 : 50|14@1- (0.1,0) [0|0] "degC" Vector__XXX
 SG_ module_3_temp_4 m22 : 50|14@1- (0.1,0) [0|0] "degC" Vector__XXX
 SG_ module_2_temp_40 m20 : 50|14@1- (0.1,0) [0|0] "degC" Vector__XXX
 SG_ module_2_temp_36 m19 : 50|14@1- (0.1,0) [0|0] "degC" Vector__XXX
 SG_ module_2_temp_32 m18 : 50|14@1- (0.1,0) [0|0] "degC" Vector__XXX
 SG_ module_2_temp_28 m17 : 50|14@1- (0.1,0) [0|0] "degC" Vector__XXX
 SG_ module_2_temp_24 m16 : 50|14@1- (0.1,0) [0|0] "degC" Vector__XXX
 SG_ module_2_temp_20 m15 : 50|14@1- (0.1,0) [0|0] "degC" Vector__XXX
 SG_ module_2_temp_16 m14 : 50|14@1- (0.1,0) [0|0] "degC" Vector__XXX
 SG_ module_2_temp_12 m13 : 50|14@1- (0.1,0) [0|0] "degC" Vector__XXX
 SG_ module_2_temp_8 m12 : 50|14@1- (0.1,0) [0|0] "degC" Vector__XXX
 SG_ module_2_temp_4 m11 : 50|14@1- (0.1,0) [0|0] "degC" Vector__XXX
 SG_ module_1_temp_40 m9 : 50|14@1- (0.1,0) [0|0] "degC" Vector__XXX
 SG_ module_1_temp_36 m8 : 50|14@1- (0.1,0) [0|0] "degC" Vector__XXX
 SG_ module_1_temp_32 m7 : 50|14@1- (0.1,0) [0|0] "degC" Vector__XXX
 SG_ module_1_temp_28 m6 : 50|14@1- (0.1,0) [0|0] "degC" Vector__XXX
 SG_ module_1_temp_24 m5 : 50|14@1- (0.1,0) [0|0] "degC" Vector__XXX
 SG_ module_1_temp_20 m4 : 50|14@1- (0.1,0) [0|0] "degC" Vector__XXX
 SG_ module_1_temp_16 m3 : 50|14@1- (0.1,0) [0|0] "degC" Vector__XXX
 SG_ module_1_temp_12 m2 : 50|14@1- (0.1,0) [0|0] "degC" Vector__XXX
 SG_ module_1_temp_8 m1 : 50|14@1- (0.1,0) [0|0] "degC" Vector__XXX
 SG_ module_1_temp_4 m0 : 50|14@1- (0.1,0) [0|0] "degC" Vector__XXX
 SG_ module_10_temp_39 m108 : 36|14@1- (0.1,0) [0|0] "degC" Vector__XXX
 SG_ module_10_temp_35 m107 : 36|14@1- (0.1,0) [0|0] "degC" Vector__XXX
 SG_ module_10_temp_31 m106 : 36|14@1- (0.1,0) [0|0] "degC" Vector__XXX
 SG_ module_10_temp_27 m105 : 36|14@1- (0.1,0) [0|0] "degC" Vector__XXX
 SG_ module_10_temp_23 m104 : 36|14@1- (0.1,0) [0|0] "degC" Vector__XXX
 SG_ module_10_temp_19 m103 : 36|14@1- (0.1,0) [0|0] "degC" Vector__XXX
 SG_ module_10_temp_15 m102 : 36|14@1- (0.1,0) [0|0] "degC" Vector__XXX
 SG_ module_10_temp_11 m101 : 36|14@1- (0.1,0) [0|0] "degC" Vector__XXX
 SG_ module_10_temp_7 m100 : 36|14@1- (0.1,0) [0|0] "degC" Vector__XXX
 SG_ module_10_temp_3 m99 : 36|14@1- (0.1,0) [0|0] "degC" Vector__XXX
 SG_ module_9_temp_39 m97 : 36|14@1- (0.1,0) [0|0] "degC" Vector__XXX
 SG_ module_9_temp_35 m96 : 36|14@1- (0.1,0) [0|0] "degC" Vector__XXX
 SG_ module_9_temp_31 m95 : 36|14@1- (0.1,0) [0|0] "degC" Vector__XXX
 SG_ module_9_temp_27 m94 : 36|14@1- (0.1,0) [0|0] "degC" Vector__XXX
 SG_ module_9_temp_23 m93 : 36|14@1- (0.1,0) [0|0] "degC" Vector__XXX
 SG_ module_9_temp_19 m92 : 36|14@1- (0.1,0) [0|0] "degC" Vector__XXX
 SG_ module_9_temp_15 m91 : 36|14@1- (0.1,0) [0|0] "degC" Vector__XXX
 SG_ module_9_temp_11 m90 : 36|14@1- (0.1,0) [0|0] "degC" Vector__XXX
 SG_ module_9_temp_7 m89 : 36|14@1- (0.1,0) [0|0] "degC" Vector__XXX
 SG_ module_9_temp_3 m88 : 36|14@1- (0.1,0) [0|0] "degC" Vector__XXX
 SG_ module_8_temp_39 m86 : 36|14@1- (0.1,0) [0|0] "degC" Vector__XXX
 SG_ module_8_temp_35 m85 : 36|14@1- (0.1,0) [0|0] "degC" Vector__XXX
 SG_ module_8_temp_31 m84 : 36|14@1- (0.1,0) [0|0] "degC" Vector__XXX
 SG_ module_8_temp_27 m83 : 36|14@1- (0.1,0) [0|0] "degC" Vector__XXX
 SG_ module_8_temp_23 m82 : 36|14@1- (0.1,0) [0|0] "degC" Vector__XXX
 SG_ module_8_temp_19 m81 : 36|14@1- (0.1,0) [0|0] "degC" Vector__XXX
 SG_ module_8_temp_15 m80 : 36|14@1- (0.1,0) [0|0] "degC" Vector__XXX
 SG_ module_8_temp_11 m79 : 36|14@1- (0.1,0) [0|0] "degC" Vector__XXX
 SG_ module_8_temp_7 m78 : 36|14@1- (0.1,0) [0|0] "degC" Vector__XXX
 SG_ module_8_temp_3 m77 : 36|14@1- (0.1,0) [0|0] "degC" Vector__XXX
 SG_ module_7_temp_39 m75 : 36|14@1- (0.1,0) [0|0] "degC" Vector__XXX
 SG_ module_7_temp_35 m74 : 36|14@1- (0.1,0) [0|0] "degC" Vector__XXX
 SG_ module_7_temp_31 m73 : 36|14@1- (0.1,0) [0|0] "degC" Vector__XXX
 SG_ module_7_temp_27 m72 : 36|14@1- (0.1,0) [0|0] "degC" Vector__XXX
 SG_ module_7_temp_23 m71 : 36|14@1- (0.1,0) [0|0] "degC" Vector__XXX
 SG_ module_7_temp_19 m70 : 36|14@1- (0.1,0) [0|0] "degC" Vector__XXX
 SG_ module_7_temp_15 m69 : 36|14@1- (0.1,0) [0|0] "degC" Vector__XXX
 SG_ module_7_temp_11 m68 : 36|14@1- (0.1,0) [0|0] "degC" Vector__XXX
 SG_ module_7_temp_7 m67 : 36|14@1- (0.1,0) [0|0] "degC" Vector__XXX
 SG_ module_7_temp_3 m66 : 36|14@1- (0.1,0) [0|0] "degC" Vector__XXX
 SG_ module_6_temp_39 m64 : 36|14@1- (0.1,0) [0|0] "degC" Vector__XXX
 SG_ module_6_temp_35 m63 : 36|14@1- (0.1,0) [0|0] "degC" Vector__XXX
 SG_ module_6_temp_31 m62 : 36|14@1- (0.1,0) [0|0] "degC" Vector__XXX
 SG_ module_6_temp_27 m61 : 36|14@1- (0.1,0) [0|0] "degC" Vector__XXX
 SG_ module_6_temp_23 m60 : 36|14@1- (0.1,0) [0|0] "degC" Vector__XXX
 SG_ module_6_temp_19 m59 : 36|14@1- (0.1,0) [0|0] "degC" Vector__XXX
 SG_ module_6_temp_15 m58 : 36|14@1- (0.1,0) [0|0] "degC" Vector__XXX
 SG_ module_6_temp_11 m57 : 36|14@1- (0.1,0) [0|0] "degC" Vector__XXX
 SG_ module_6_temp_7 m56 : 36|14@1- (0.1,0) [0|0] "degC" Vector__XXX
 SG_ module_6_temp_3 m55 : 36|14@1- (0.1,0) [0|0] "degC" Vector__XXX
 SG_ module_5_temp_39 m53 : 36|14@1- (0.1,0) [0|0] "degC" Vector__XXX
 SG_ module_5_temp_35 m52 : 36|14@1- (0.1,0) [0|0] "degC" Vector__XXX
 SG_ module_5_temp_31 m51 : 36|14@1- (0.1,0) [0|0] "degC" Vector__XXX
 SG_ module_5_temp_27 m50 : 36|14@1- (0.1,0) [0|0] "degC" Vector__XXX
 SG_ module_5_temp_23 m49 : 36|14@1- (0.1,0) [0|0] "degC" Vector__XXX
 SG_ module_5_temp_19 m48 : 36|14@1- (0.1,0) [0|0] "degC" Vector__XXX
 SG_ module_5_temp_15 m47 : 36|14@1- (0.1,0) [0|0] "degC" Vector__XXX
 SG_ module_5_temp_11 m46 : 36|14@1- (0.1,0) [0|0] "degC" Vector__XXX
 SG_ module_5_temp_7 m45 : 36|14@1- (0.1,0) [0|0] "degC" Vector__XXX
 SG_ module_5_temp_3 m44 : 36|14@1- (0.1,0) [0|0] "degC" Vector__XXX
 SG_ module_4_temp_39 m42 : 36|14@1- (0.1,0) [0|0] "degC" Vector__XXX
 SG_ module_4_temp_35 m41 : 36|14@1- (0.1,0) [0|0] "degC" Vector__XXX
 SG_ module_4_temp_31 m40 : 36|14@1- (0.1,0) [0|0] "degC" Vector__XXX
 SG_ module_4_temp_27 m39 : 36|14@1- (0.1,0) [0|0] "degC" Vector__XXX
 SG_ module_4_temp_23 m38 : 36|14@1- (0.1,0) [0|0] "degC" Vector__XXX
 SG_ module_4_temp_19 m37 : 36|14@1- (0.1,0) [0|0] "degC" Vector__XXX
 SG_ module_4_temp_15 m36 : 36|14@1- (0.1,0) [0|0] "degC" Vector__XXX
 SG_ module_4_temp_11 m35 : 36|14@1- (0.1,0) [0|0] "degC" Vector__XXX
 SG_ module_4_temp_7 m34 : 36|14@1- (0.1,0) [0|0] "degC" Vector__XXX
 SG_ module_4_temp_3 m33 : 36|14@1- (0.1,0) [0|0] "degC" Vector__XXX
 SG_ module_3_temp_39 m31 : 36|14@1- (0.1,0) [0|0] "degC" Vector__XXX
 SG_ module_3_temp_35 m30 : 36|14@1- (0.1,0) [0|0] "degC" Vector__XXX
 SG_ module_3_temp_31 m29 : 36|14@1- (0.1,0) [0|0] "degC" Vector__XXX
 SG_ module_3_temp_27 m28 : 36|14@1- (0.1,0) [0|0] "degC" Vector__XXX
 SG_ module_3_temp_23 m27 : 36|14@1- (0.1,0) [0|0] "degC" Vector__XXX
 SG_ module_3_temp_19 m26 : 36|14@1- (0.1,0) [0|0] "degC" Vector__XXX
 SG_ module_3_temp_15 m25 : 36|14@1- (0.1,0) [0|0] "degC" Vector__XXX
 SG_ module_3_temp_11 m24 : 36|14@1- (0.1,0) [0|0] "degC" Vector__XXX
 SG_ module_3_temp_7 m23 : 36|14@1- (0.1,0) [0|0] "degC" Vector__XXX
 SG_ module_3_temp_3 m22 : 36|14@1- (0.1,0) [0|0] "degC" Vector__XXX
 SG_ module_2_temp_39 m20 : 36|14@1- (0.1,0) [0|0] "degC" Vector__XXX
 SG_ module_2_temp_35 m19 : 36|14@1- (0.1,0) [0|0] "degC" Vector__XXX
 SG_ module_2_temp_31 m18 : 36|14@1- (0.1,0) [0|0] "degC" Vector__XXX
 SG_ module_2_temp_27 m17 : 36|14@1- (0.1,0) [0|0] "degC" Vector__XXX
 SG_ module_2_temp_23 m16 : 36|14@1- (0.1,0) [0|0] "degC" Vector__XXX
 SG_ module_2_temp_19 m15 : 36|14@1- (0.1,0) [0|0] "degC" Vector__XXX
 SG_ module_2_temp_15 m14 : 36|14@1- (0.1,0) [0|0] "degC" Vector__XXX
 SG_ module_2_temp_11 m13 : 36|14@1- (0.1,0) [0|0] "degC" Vector__XXX
 SG_ module_2_temp_7 m12 : 36|14@1- (0.1,0) [0|0] "degC" Vector__XXX
 SG_ module_2_temp_3 m11 : 36|14@1- (0.1,0) [0|0] "degC" Vector__XXX
 SG_ module_1_temp_39 m9 : 36|14@1- (0.1,0) [0|0] "degC" Vector__XXX
 SG_ module_1_temp_35 m8 : 36|14@1- (0.1,0) [0|0] "degC" Vector__XXX
 SG_ module_1_temp_31 m7 : 36|14@1- (0.1,0) [0|0] "degC" Vector__XXX
 SG_ module_1_temp_27 m6 : 36|14@1- (0.1,0) [0|0] "degC" Vector__XXX
 SG_ module_1_temp_23 m5 : 36|14@1- (0.1,0) [0|0] "degC" Vector__XXX
 SG_ module_1_temp_19 m4 : 36|14@1- (0.1,0) [0|0] "degC" Vector__XXX
 SG_ module_1_temp_15 m3 : 36|14@1- (0.1,0) [0|0] "degC" Vector__XXX
 SG_ module_1_temp_11 m2 : 36|14@1- (0.1,0) [0|0] "degC" Vector__XXX
 SG_ module_1_temp_7 m1 : 36|14@1- (0.1,0) [0|0] "degC" Vector__XXX
 SG_ module_1_temp_3 m0 : 36|14@1- (0.1,0) [0|0] "degC" Vector__XXX
 SG_ module_10_temp_38 m108 : 22|14@1- (0.1,0) [0|0] "degC" Vector__XXX
 SG_ module_10_temp_34 m107 : 22|14@1- (0.1,0) [0|0] "degC" Vector__XXX
 SG_ module_10_temp_30 m106 : 22|14@1- (0.1,0) [0|0] "degC" Vector__XXX
 SG_ module_10_temp_26 m105 : 22|14@1- (0.1,0) [0|0] "degC" Vector__XXX
 SG_ module_10_temp_22 m104 : 22|14@1- (0.1,0) [0|0] "degC" Vector__XXX
 SG_ module_10_temp_18 m103 : 22|14@1- (0.1,0) [0|0] "degC" Vector__XXX
 SG_ module_10_temp_14 m102 : 22|14@1- (0.1,0) [0|0] "degC" Vector__XXX
 SG_ module_10_temp_10 m101 : 22|14@1- (0.1,0) [0|0] "degC" Vector__XXX
 SG_ module_10_temp_6 m100 : 22|14@1- (0.1,0) [0|0] "degC" Vector__XXX
 SG_ module_10_temp_2 m99 : 22|14@1- (0.1,0) [0|0] "degC" Vector__XXX
 SG_ module_9_temp_38 m97 : 22|14@1- (0.1,0) [0|0] "degC" Vector__XXX
 SG_ module_9_temp_34 m96 : 22|14@1- (0.1,0) [0|0] "degC" Vector__XXX
 SG_ module_9_temp_30 m95 : 22|14@1- (0.1,0) [0|0] "degC" Vector__XXX
 SG_ module_9_temp_26 m94 : 22|14@1- (0.1,0) [0|0] "degC" Vector__XXX
 SG_ module_9_temp_22 m93 : 22|14@1- (0.1,0) [0|0] "degC" Vector__XXX
 SG_ module_9_temp_18 m92 : 22|14@1- (0.1,0) [0|0] "degC" Vector__XXX
 SG_ module_9_temp_14 m91 : 22|14@1- (0.1,0) [0|0] "degC" Vector__XXX
 SG_ module_9_temp_10 m90 : 22|14@1- (0.1,0) [0|0] "degC" Vector__XXX
 SG_ module_9_temp_6 m89 : 22|14@1- (0.1,0) [0|0] "degC" Vector__XXX
 SG_ module_9_temp_2 m88 : 22|14@1- (0.1,0) [0|0] "degC" Vector__XXX
 SG_ module_8_temp_38 m86 : 22|14@1- (0.1,0) [0|0] "degC" Vector__XXX
 SG_ module_8_temp_34 m85 : 22|14@1- (0.1,0) [0|0] "degC" Vector__XXX
 SG_ module_8_temp_30 m84 : 22|14@1- (0.1,0) [0|0] "degC" Vector__XXX
 SG_ module_8_temp_26 m83 : 22|14@1- (0.1,0) [0|0] "degC" Vector__XXX
 SG_ module_8_temp_22 m82 : 22|14@1- (0.1,0) [0|0] "degC" Vector__XXX
 SG_ module_8_temp_18 m81 : 22|14@1- (0.1,0) [0|0] "degC" Vector__XXX
 SG_ module_8_temp_14 m80 : 22|14@1- (0.1,0) [0|0] "degC" Vector__XXX
 SG_ module_8_temp_10 m79 : 22|14@1- (0.1,0) [0|0] "degC" Vector__XXX
 SG_ module_8_temp_6 m78 : 22|14@1- (0.1,0) [0|0] "degC" Vector__XXX
 SG_ module_8_temp_2 m77 : 22|14@1- (0.1,0) [0|0] "degC" Vector__XXX
 SG_ module_7_temp_38 m75 : 22|14@1- (0.1,0) [0|0] "degC" Vector__XXX
 SG_ module_7_temp_34 m74 : 22|14@1- (0.1,0) [0|0] "degC" Vector__XXX
 SG_ module_7_temp_30 m73 : 22|14@1- (0.1,0) [0|0] "degC" Vector__XXX
 SG_ module_7_temp_26 m72 : 22|14@1- (0.1,0) [0|0] "degC" Vector__XXX
 SG_ module_7_temp_22 m71 : 22|14@1- (0.1,0) [0|0] "degC" Vector__XXX
 SG_ module_7_temp_18 m70 : 22|14@1- (0.1,0) [0|0] "degC" Vector__XXX
 SG_ module_7_temp_14 m69 : 22|14@1- (0.1,0) [0|0] "degC" Vector__XXX
 SG_ module_7_temp_10 m68 : 22|14@1- (0.1,0) [0|0] "degC" Vector__XXX
 SG_ module_7_temp_6 m67 : 22|14@1- (0.1,0) [0|0] "degC" Vector__XXX
 SG_ module_7_temp_2 m66 : 22|14@1- (0.1,0) [0|0] "degC" Vector__XXX
 SG_ module_6_temp_38 m64 : 22|14@1- (0.1,0) [0|0] "degC" Vector__XXX
 SG_ module_6_temp_34 m63 : 22|14@1- (0.1,0) [0|0] "degC" Vector__XXX
 SG_ module_6_temp_30 m62 : 22|14@1- (0.1,0) [0|0] "degC" Vector__XXX
 SG_ module_6_temp_26 m61 : 22|14@1- (0.1,0) [0|0] "degC" Vector__XXX
 SG_ module_6_temp_22 m60 : 22|14@1- (0.1,0) [0|0] "degC" Vector__XXX
 SG_ module_6_temp_18 m59 : 22|14@1- (0.1,0) [0|0] "degC" Vector__XXX
 SG_ module_6_temp_14 m58 : 22|14@1- (0.1,0) [0|0] "degC" Vector__XXX
 SG_ module_6_temp_10 m57 : 22|14@1- (0.1,0) [0|0] "degC" Vector__XXX
 SG_ module_6_temp_6 m56 : 22|14@1- (0.1,0) [0|0] "degC" Vector__XXX
 SG_ module_6_temp_2 m55 : 22|14@1- (0.1,0) [0|0] "degC" Vector__XXX
 SG_ module_5_temp_38 m53 : 22|14@1- (0.1,0) [0|0] "degC" Vector__XXX
 SG_ module_5_temp_34 m52 : 22|14@1- (0.1,0) [0|0] "degC" Vector__XXX
 SG_ module_5_temp_30 m51 : 22|14@1- (0.1,0) [0|0] "degC" Vector__XXX
 SG_ module_5_temp_26 m50 : 22|14@1- (0.1,0) [0|0] "degC" Vector__XXX
 SG_ module_5_temp_22 m49 : 22|14@1- (0.1,0) [0|0] "degC" Vector__XXX
 SG_ module_5_temp_18 m48 : 22|14@1- (0.1,0) [0|0] "degC" Vector__XXX
 SG_ module_5_temp_14 m47 : 22|14@1- (0.1,0) [0|0] "degC" Vector__XXX
 SG_ module_5_temp_10 m46 : 22|14@1- (0.1,0) [0|0] "degC" Vector__XXX
 SG_ module_5_temp_6 m45 : 22|14@1- (0.1,0) [0|0] "degC" Vector__XXX
 SG_ module_5_temp_2 m44 : 22|14@1- (0.1,0) [0|0] "degC" Vector__XXX
 SG_ module_4_temp_38 m42 : 22|14@1- (0.1,0) [0|0] "degC" Vector__XXX
 SG_ module_4_temp_34 m41 : 22|14@1- (0.1,0) [0|0] "degC" Vector__XXX
 SG_ module_4_temp_30 m40 : 22|14@1- (0.1,0) [0|0] "degC" Vector__XXX
 SG_ module_4_temp_26 m39 : 22|14@1- (0.1,0) [0|0] "degC" Vector__XXX
 SG_ module_4_temp_22 m38 : 22|14@1- (0.1,0) [0|0] "degC" Vector__XXX
 SG_ module_4_temp_18 m37 : 22|14@1- (0.1,0) [0|0] "degC" Vector__XXX
 SG_ module_4_temp_14 m36 : 22|14@1- (0.1,0) [0|0] "degC" Vector__XXX
 SG_ module_4_temp_10 m35 : 22|14@1- (0.1,0) [0|0] "degC" Vector__XXX
 SG_ module_4_temp_6 m34 : 22|14@1- (0.1,0) [0|0] "degC" Vector__XXX
 SG_ module_4_temp_2 m33 : 22|14@1- (0.1,0) [0|0] "degC" Vector__XXX
 SG_ module_3_temp_38 m31 : 22|14@1- (0.1,0) [0|0] "degC" Vector__XXX
 SG_ module_3_temp_34 m30 : 22|14@1- (0.1,0) [0|0] "degC" Vector__XXX
 SG_ module_3_temp_30 m29 : 22|14@1- (0.1,0) [0|0] "degC" Vector__XXX
 SG_ module_3_temp_26 m28 : 22|14@1- (0.1,0) [0|0] "degC" Vector__XXX
 SG_ module_3_temp_22 m27 : 22|14@1- (0.1,0) [0|0] "degC" Vector__XXX
 SG_ module_3_temp_18 m26 : 22|14@1- (0.1,0) [0|0] "degC" Vector__XXX
 SG_ module_3_temp_14 m25 : 22|14@1- (0.1,0) [0|0] "degC" Vector__XXX
 SG_ module_3_temp_10 m24 : 22|14@1- (0.1,0) [0|0] "degC" Vector__XXX
 SG_ module_3_temp_6 m23 : 22|14@1- (0.1,0) [0|0] "degC" Vector__XXX
 SG_ module_3_temp_2 m22 : 22|14@1- (0.1,0) [0|0] "degC" Vector__XXX
 SG_ module_2_temp_38 m20 : 22|14@1- (0.1,0) [0|0] "degC" Vector__XXX
 SG_ module_2_temp_34 m19 : 22|14@1- (0.1,0) [0|0] "degC" Vector__XXX
 SG_ module_2_temp_30 m18 : 22|14@1- (0.1,0) [0|0] "degC" Vector__XXX
 SG_ module_2_temp_26 m17 : 22|14@1- (0.1,0) [0|0] "degC" Vector__XXX
 SG_ module_2_temp_22 m16 : 22|14@1- (0.1,0) [0|0] "degC" Vector__XXX
 SG_ module_2_temp_18 m15 : 22|14@1- (0.1,0) [0|0] "degC" Vector__XXX
 SG_ module_2_temp_14 m14 : 22|14@1- (0.1,0) [0|0] "degC" Vector__XXX
 SG_ module_2_temp_10 m13 : 22|14@1- (0.1,0) [0|0] "degC" Vector__XXX
 SG_ module_2_temp_6 m12 : 22|14@1- (0.1,0) [0|0] "degC" Vector__XXX
 SG_ module_2_temp_2 m11 : 22|14@1- (0.1,0) [0|0] "degC" Vector__XXX
 SG_ module_1_temp_38 m9 : 22|14@1- (0.1,0) [0|0] "degC" Vector__XXX
 SG_ module_1_temp_34 m8 : 22|14@1- (0.1,0) [0|0] "degC" Vector__XXX
 SG_ module_1_temp_30 m7 : 22|14@1- (0.1,0) [0|0] "degC" Vector__XXX
 SG_ module_1_temp_26 m6 : 22|14@1- (0.1,0) [0|0] "degC" Vector__XXX
 SG_ module_1_temp_22 m5 : 22|14@1- (0.1,0) [0|0] "degC" Vector__XXX
 SG_ module_1_temp_18 m4 : 22|14@1- (0.1,0) [0|0] "degC" Vector__XXX
 SG_ module_1_temp_14 m3 : 22|14@1- (0.1,0) [0|0] "degC" Vector__XXX
 SG_ module_1_temp_10 m2 : 22|14@1- (0.1,0) [0|0] "degC" Vector__XXX
 SG_ module_1_temp_6 m1 : 22|14@1- (0.1,0) [0|0] "degC" Vector__XXX
 SG_ module_1_temp_2 m0 : 22|14@1- (0.1,0) [0|0] "degC" Vector__XXX
 SG_ module_10_temp_41 m109 : 8|14@1- (0.1,0) [0|0] "degC" Vector__XXX
 SG_ module_10_temp_37 m108 : 8|14@1- (0.1,0) [0|0] "degC" Vector__XXX
 SG_ module_10_temp_33 m107 : 8|14@1- (0.1,0) [0|0] "degC" Vector__XXX
 SG_ module_10_temp_29 m106 : 8|14@1- (0.1,0) [0|0] "degC" Vector__XXX
 SG_ module_10_temp_25 m105 : 8|14@1- (0.1,0) [0|0] "degC" Vector__XXX
 SG_ module_10_temp_21 m104 : 8|14@1- (0.1,0) [0|0] "degC" Vector__XXX
 SG_ module_10_temp_17 m103 : 8|14@1- (0.1,0) [0|0] "degC" Vector__XXX
 SG_ module_10_temp_13 m102 : 8|14@1- (0.1,0) [0|0] "degC" Vector__XXX
 SG_ module_10_temp_9 m101 : 8|14@1- (0.1,0) [0|0] "degC" Vector__XXX
 SG_ module_10_temp_5 m100 : 8|14@1- (0.1,0) [0|0] "degC" Vector__XXX
 SG_ module_10_temp_1 m99 : 8|14@1- (0.1,0) [0|0] "degC" Vector__XXX
 SG_ module_9_temp_41 m98 : 8|14@1- (0.1,0) [0|0] "degC" Vector__XXX
 SG_ module_9_temp_37 m97 : 8|14@1- (0.1,0) [0|0] "degC" Vector__XXX
 SG_ module_9_temp_33 m96 : 8|14@1- (0.1,0) [0|0] "degC" Vector__XXX
 SG_ module_9_temp_29 m95 : 8|14@1- (0.1,0) [0|0] "degC" Vector__XXX
 SG_ module_9_temp_25 m94 : 8|14@1- (0.1,0) [0|0] "degC" Vector__XXX
 SG_ module_9_temp_21 m93 : 8|14@1- (0.1,0) [0|0] "degC" Vector__XXX
 SG_ module_9_temp_17 m92 : 8|14@1- (0.1,0) [0|0] "degC" Vector__XXX
 SG_ module_9_temp_13 m91 : 8|14@1- (0.1,0) [0|0] "degC" Vector__XXX
 SG_ module_9_temp_9 m90 : 8|14@1- (0.1,0) [0|0] "degC" Vector__XXX
 SG_ module_9_temp_5 m89 : 8|14@1- (0.1,0) [0|0] "degC" Vector__XXX
 SG_ module_9_temp_1 m88 : 8|14@1- (0.1,0) [0|0] "degC" Vector__XXX
 SG_ module_8_temp_41 m87 : 8|14@1- (0.1,0) [0|0] "degC" Vector__XXX
 SG_ module_8_temp_37 m86 : 8|14@1- (0.1,0) [0|0] "degC" Vector__XXX
 SG_ module_8_temp_33 m85 : 8|14@1- (0.1,0) [0|0] "degC" Vector__XXX
 SG_ module_8_temp_29 m84 : 8|14@1- (0.1,0) [0|0] "degC" Vector__XXX
 SG_ module_8_temp_25 m83 : 8|14@1- (0.1,0) [0|0] "degC" Vector__XXX
 SG_ module_8_temp_21 m82 : 8|14@1- (0.1,0) [0|0] "degC" Vector__XXX
 SG_ module_8_temp_17 m81 : 8|14@1- (0.1,0) [0|0] "degC" Vector__XXX
 SG_ module_8_temp_13 m80 : 8|14@1- (0.1,0) [0|0] "degC" Vector__XXX
 SG_ module_8_temp_9 m79 : 8|14@1- (0.1,0) [0|0] "degC" Vector__XXX
 SG_ module_8_temp_5 m78 : 8|14@1- (0.1,0) [0|0] "degC" Vector__XXX
 SG_ module_8_temp_1 m77 : 8|14@1- (0.1,0) [0|0] "degC" Vector__XXX
 SG_ module_7_temp_41 m76 : 8|14@1- (0.1,0) [0|0] "degC" Vector__XXX
 SG_ module_7_temp_37 m75 : 8|14@1- (0.1,0) [0|0] "degC" Vector__XXX
 SG_ module_7_temp_33 m74 : 8|14@1- (0.1,0) [0|0] "degC" Vector__XXX
 SG_ module_7_temp_29 m73 : 8|14@1- (0.1,0) [0|0] "degC" Vector__XXX
 SG_ module_7_temp_25 m72 : 8|14@1- (0.1,0) [0|0] "degC" Vector__XXX
 SG_ module_7_temp_21 m71 : 8|14@1- (0.1,0) [0|0] "degC" Vector__XXX
 SG_ module_7_temp_17 m70 : 8|14@1- (0.1,0) [0|0] "degC" Vector__XXX
 SG_ module_7_temp_13 m69 : 8|14@1- (0.1,0) [0|0] "degC" Vector__XXX
 SG_ module_7_temp_9 m68 : 8|14@1- (0.1,0) [0|0] "degC" Vector__XXX
 SG_ module_7_temp_5 m67 : 8|14@1- (0.1,0) [0|0] "degC" Vector__XXX
 SG_ module_7_temp_1 m66 : 8|14@1- (0.1,0) [0|0] "degC" Vector__XXX
 SG_ module_6_temp_41 m65 : 8|14@1- (0.1,0) [0|0] "degC" Vector__XXX
 SG_ module_6_temp_37 m64 : 8|14@1- (0.1,0) [0|0] "degC" Vector__XXX
 SG_ module_6_temp_33 m63 : 8|14@1- (0.1,0) [0|0] "degC" Vector__XXX
 SG_ module_6_temp_29 m62 : 8|14@1- (0.1,0) [0|0] "degC" Vector__XXX
 SG_ module_6_temp_25 m61 : 8|14@1- (0.1,0) [0|0] "degC" Vector__XXX
 SG_ module_6_temp_21 m60 : 8|14@1- (0.1,0) [0|0] "degC" Vector__XXX
 SG_ module_6_temp_17 m59 : 8|14@1- (0.1,0) [0|0] "degC" Vector__XXX
 SG_ module_6_temp_13 m58 : 8|14@1- (0.1,0) [0|0] "degC" Vector__XXX
 SG_ module_6_temp_9 m57 : 8|14@1- (0.1,0) [0|0] "degC" Vector__XXX
 SG_ module_6_temp_5 m56 : 8|14@1- (0.1,0) [0|0] "degC" Vector__XXX
 SG_ module_6_temp_1 m55 : 8|14@1- (0.1,0) [0|0] "degC" Vector__XXX
 SG_ module_5_temp_41 m54 : 8|14@1- (0.1,0) [0|0] "degC" Vector__XXX
 SG_ module_5_temp_37 m53 : 8|14@1- (0.1,0) [0|0] "degC" Vector__XXX
 SG_ module_5_temp_33 m52 : 8|14@1- (0.1,0) [0|0] "degC" Vector__XXX
 SG_ module_5_temp_29 m51 : 8|14@1- (0.1,0) [0|0] "degC" Vector__XXX
 SG_ module_5_temp_25 m50 : 8|14@1- (0.1,0) [0|0] "degC" Vector__XXX
 SG_ module_5_temp_21 m49 : 8|14@1- (0.1,0) [0|0] "degC" Vector__XXX
 SG_ module_5_temp_17 m48 : 8|14@1- (0.1,0) [0|0] "degC" Vector__XXX
 SG_ module_5_temp_13 m47 : 8|14@1- (0.1,0) [0|0] "degC" Vector__XXX
 SG_ module_5_temp_9 m46 : 8|14@1- (0.1,0) [0|0] "degC" Vector__XXX
 SG_ module_5_temp_5 m45 : 8|14@1- (0.1,0) [0|0] "degC" Vector__XXX
 SG_ module_5_temp_1 m44 : 8|14@1- (0.1,0) [0|0] "degC" Vector__XXX
 SG_ module_4_temp_41 m43 : 8|14@1- (0.1,0) [0|0] "degC" Vector__XXX
 SG_ module_4_temp_37 m42 : 8|14@1- (0.1,0) [0|0] "degC" Vector__XXX
 SG_ module_4_temp_33 m41 : 8|14@1- (0.1,0) [0|0] "degC" Vector__XXX
 SG_ module_4_temp_29 m40 : 8|14@1- (0.1,0) [0|0] "degC" Vector__XXX
 SG_ module_4_temp_25 m39 : 8|14@1- (0.1,0) [0|0] "degC" Vector__XXX
 SG_ module_4_temp_21 m38 : 8|14@1- (0.1,0) [0|0] "degC" Vector__XXX
 SG_ module_4_temp_17 m37 : 8|14@1- (0.1,0) [0|0] "degC" Vector__XXX
 SG_ module_4_temp_13 m36 : 8|14@1- (0.1,0) [0|0] "degC" Vector__XXX
 SG_ module_4_temp_9 m35 : 8|14@1- (0.1,0) [0|0] "degC" Vector__XXX
 SG_ module_4_temp_5 m34 : 8|14@1- (0.1,0) [0|0] "degC" Vector__XXX
 SG_ module_4_temp_1 m33 : 8|14@1- (0.1,0) [0|0] "degC" Vector__XXX
 SG_ module_3_temp_41 m32 : 8|14@1- (0.1,0) [0|0] "degC" Vector__XXX
 SG_ module_3_temp_37 m31 : 8|14@1- (0.1,0) [0|0] "degC" Vector__XXX
 SG_ module_3_temp_33 m30 : 8|14@1- (0.1,0) [0|0] "degC" Vector__XXX
 SG_ module_3_temp_29 m29 : 8|14@1- (0.1,0) [0|0] "degC" Vector__XXX
 SG_ module_3_temp_25 m28 : 8|14@1- (0.1,0) [0|0] "degC" Vector__XXX
 SG_ module_3_temp_21 m27 : 8|14@1- (0.1,0) [0|0] "degC" Vector__XXX
 SG_ module_3_temp_17 m26 : 8|14@1- (0.1,0) [0|0] "degC" Vector__XXX
 SG_ module_3_temp_13 m25 : 8|14@1- (0.1,0) [0|0] "degC" Vector__XXX
 SG_ module_3_temp_9 m24 : 8|14@1- (0.1,0) [0|0] "degC" Vector__XXX
 SG_ module_3_temp_5 m23 : 8|14@1- (0.1,0) [0|0] "degC" Vector__XXX
 SG_ module_3_temp_1 m22 : 8|14@1- (0.1,0) [0|0] "degC" Vector__XXX
 SG_ module_2_temp_41 m21 : 8|14@1- (0.1,0) [0|0] "degC" Vector__XXX
 SG_ module_2_temp_37 m20 : 8|14@1- (0.1,0) [0|0] "degC" Vector__XXX
 SG_ module_2_temp_33 m19 : 8|14@1- (0.1,0) [0|0] "degC" Vector__XXX
 SG_ module_2_temp_29 m18 : 8|14@1- (0.1,0) [0|0] "degC" Vector__XXX
 SG_ module_2_temp_25 m17 : 8|14@1- (0.1,0) [0|0] "degC" Vector__XXX
 SG_ module_2_temp_21 m16 : 8|14@1- (0.1,0) [0|0] "degC" Vector__XXX
 SG_ module_2_temp_17 m15 : 8|14@1- (0.1,0) [0|0] "degC" Vector__XXX
 SG_ module_2_temp_13 m14 : 8|14@1- (0.1,0) [0|0] "degC" Vector__XXX
 SG_ module_2_temp_9 m13 : 8|14@1- (0.1,0) [0|0] "degC" Vector__XXX
 SG_ module_2_temp_5 m12 : 8|14@1- (0.1,0) [0|0] "degC" Vector__XXX
 SG_ module_2_temp_1 m11 : 8|14@1- (0.1,0) [0|0] "degC" Vector__XXX
 SG_ module_1_temp_41 m10 : 8|14@1- (0.1,0) [0|0] "degC" Vector__XXX
 SG_ module_1_temp_37 m9 : 8|14@1- (0.1,0) [0|0] "degC" Vector__XXX
 SG_ module_1_temp_33 m8 : 8|14@1- (0.1,0) [0|0] "degC" Vector__XXX
 SG_ module_1_temp_29 m7 : 8|14@1- (0.1,0) [0|0] "degC" Vector__XXX
 SG_ module_1_temp_25 m6 : 8|14@1- (0.1,0) [0|0] "degC" Vector__XXX
 SG_ module_1_temp_21 m5 : 8|14@1- (0.1,0) [0|0] "degC" Vector__XXX
 SG_ module_1_temp_17 m4 : 8|14@1- (0.1,0) [0|0] "degC" Vector__XXX
 SG_ module_1_temp_13 m3 : 8|14@1- (0.1,0) [0|0] "degC" Vector__XXX
 SG_ module_1_temp_9 m2 : 8|14@1- (0.1,0) [0|0] "degC" Vector__XXX
 SG_ module_1_temp_5 m1 : 8|14@1- (0.1,0) [0|0] "degC" Vector__XXX
 SG_ module_1_temp_1 m0 : 8|14@1- (0.1,0) [0|0] "degC" Vector__XXX
 SG_ page M : 0|8@1+ (1,0) [0|0] "" Vector__XXX

BO_ 1280 ebs_pressure_status: 8 PCU
 SG_ ebs_pressure_4 : 48|16@1- (0.0625,0) [0|0] "bar" Vector__XXX
 SG_ ebs_pressure_3 : 32|16@1- (0.0625,0) [0|0] "bar" Vector__XXX
 SG_ ebs_pressure_2 : 16|16@1- (0.0625,0) [0|0] "bar" Vector__XXX
 SG_ ebs_pressure_1 : 0|16@1- (0.0625,0) [0|0] "bar" Vector__XXX

BO_ 1313 IVTCurrent: 6 IVT
 SG_ current : 23|32@0- (-0.001,0) [0|0] "A" Vector__XXX
 SG_ counter : 7|16@0+ (1,0) [0|0] "" Vector__XXX

BO_ 1314 IVTVoltage1: 6 IVT
 SG_ voltage1 : 23|32@0- (0.001,0) [0|0] "V" Vector__XXX
 SG_ counter : 7|16@0+ (1,0) [0|0] "" Vector__XXX

BO_ 1315 IVTVoltage2: 6 IVT
 SG_ voltage2 : 23|32@0- (0.001,0) [0|0] "V" Vector__XXX
 SG_ counter : 7|16@0+ (1,0) [0|0] "" Vector__XXX

BO_ 1316 IVTVoltage3: 6 IVT
 SG_ voltage3 : 23|32@0- (0.001,0) [0|0] "V" Vector__XXX
 SG_ counter : 7|16@0+ (1,0) [0|0] "" Vector__XXX

BO_ 1317 IVTTemperature: 6 IVT
 SG_ temperature : 23|32@0- (0.1,0) [0|0] "degC" Vector__XXX
 SG_ counter : 7|16@0+ (1,0) [0|0] "" Vector__XXX

BO_ 2550588916 Charger_Limits: 8 BMS
 SG_ Control : 32|8@1+ (1,0) [0|0] "" Vector__XXX
 SG_ MaxCurrent : 23|16@0+ (0.1,0) [0|0] "A" Vector__XXX
 SG_ MaxVoltage : 7|16@0+ (0.1,0) [0|0] "V" Vector__XXX

BO_ 2566869221 Charger_Status: 8 ElconCharger
 SG_ CommunicationState : 36|1@1+ (1,0) [0|0] "" Vector__XXX
 SG_ State : 35|1@1+ (1,0) [0|0] "" Vector__XXX
 SG_ InputVoltage : 34|1@1+ (1,0) [0|0] "" Vector__XXX
 SG_ Temperature : 33|1@1+ (1,0) [0|0] "" Vector__XXX
 SG_ HWStatus : 32|1@1+ (1,0) [0|0] "" Vector__XXX
 SG_ OutputCurrent : 23|16@0+ (0.1,0) [0|0] "A" Vector__XXX
 SG_ OutputVoltage : 7|16@0+ (0.1,0) [0|0] "V" Vector__XXX

BO_TX_BU_ 224 : BMS,DASH,LVPDB,SN_FRONT;
BO_TX_BU_ 225 : BMS,DASH,LVPDB,SN_FRONT;
BO_TX_BU_ 226 : BMS,DASH,LVPDB,SN_FRONT;
BO_TX_BU_ 227 : BMS,DASH,LVPDB,SN_FRONT;

CM_ BO_ 1 "BMS message for cell data.";
CM_ BO_ 2 "BMS message for accumulator voltage.";
CM_ BO_ 3 "BMS message for accumulator temperature.";
CM_ BO_ 4 "Accumulator Faults";
CM_ BO_ 5 "BMS message for BMS state.";
CM_ BO_ 9 "PCU brake: position + 2 pressure sensors (centi-percent) + status flags";
CM_ BO_ 10 "BSPD message.";
CM_ BO_ 11 "RES message for RES state.";
CM_ BO_ 16 "Dash state + buttons and switches";
CM_ BO_ 22 "LVPDB message for voltages of 24v bus and 12v bus";
CM_ BO_ 23 "LVPDB message for currents of LV, SH, LT, BM_L";
CM_ BO_ 24 "LVPDB message for currents of SM, AF1_AF2, CP_RF";
CM_ BO_ 30 "Linear potentiometer positions.";
CM_ BO_ 31 "Linear potentiometer positions.";
CM_ BO_ 32 "Message for left tire temp data.";
CM_ BO_ 33 "Message for right tire temp data.";
CM_ BO_ 34 "Message for left tire temp data.";
CM_ BO_ 35 "Message for right tire temp data.";
CM_ BO_ 36 "Wheel speeds + direction flags.";
CM_ SG_ 36 wss_dir_flags "bit0: left wheel direction (0=fwd, 1=rev); bit1: right wheel direction";
CM_ BO_ 37 "Wheel speeds + direction flags.";
CM_ SG_ 37 wss_dir_flags "bit0: left wheel direction (0=fwd, 1=rev); bit1: right wheel direction";
CM_ BO_ 38 "IMU acceleration (LSM6DSOX, FS=2g) + die temperature.";
CM_ SG_ 38 imu_temp "LSM6DSOX die temperature";
CM_ SG_ 38 acceleration_z "LSM6DSOX @ FS=2g (matches lsm6dsox_from_fs2_to_mg)";
CM_ SG_ 38 acceleration_y "LSM6DSOX @ FS=2g (matches lsm6dsox_from_fs2_to_mg)";
CM_ SG_ 38 acceleration_x "LSM6DSOX @ FS=2g (matches lsm6dsox_from_fs2_to_mg)";
CM_ BO_ 39 "IMU acceleration (LSM6DSOX, FS=2g) + die temperature.";
CM_ SG_ 39 imu_temp "LSM6DSOX die temperature";
CM_ SG_ 39 acceleration_z "LSM6DSOX @ FS=2g (matches lsm6dsox_from_fs2_to_mg)";
CM_ SG_ 39 acceleration_y "LSM6DSOX @ FS=2g (matches lsm6dsox_from_fs2_to_mg)";
CM_ SG_ 39 acceleration_x "LSM6DSOX @ FS=2g (matches lsm6dsox_from_fs2_to_mg)";
CM_ BO_ 40 "IMU gyro (LSM6DSOX, FS=2000dps).";
CM_ SG_ 40 gyro_z "LSM6DSOX @ FS=2000dps (matches lsm6dsox_from_fs2000_to_mdps)";
CM_ SG_ 40 gyro_y "LSM6DSOX @ FS=2000dps (matches lsm6dsox_from_fs2000_to_mdps)";
CM_ SG_ 40 gyro_x "LSM6DSOX @ FS=2000dps (matches lsm6dsox_from_fs2000_to_mdps)";
CM_ BO_ 41 "IMU gyro (LSM6DSOX, FS=2000dps).";
CM_ SG_ 41 gyro_z "LSM6DSOX @ FS=2000dps (matches lsm6dsox_from_fs2000_to_mdps)";
CM_ SG_ 41 gyro_y "LSM6DSOX @ FS=2000dps (matches lsm6dsox_from_fs2000_to_mdps)";
CM_ SG_ 41 gyro_x "LSM6DSOX @ FS=2000dps (matches lsm6dsox_from_fs2000_to_mdps)";
CM_ BO_ 42 "Magnetometer (LIS3MDL, FS=16gauss) + die temperature.";
CM_ SG_ 42 mag_temp "LIS3MDL die temperature";
CM_ SG_ 42 magnetometer_z "LIS3MDL @ FS=16gauss (matches lis3mdl_from_fs16_to_gauss * 1000)";
CM_ SG_ 42 magnetometer_y "LIS3MDL @ FS=16gauss (matches lis3mdl_from_fs16_to_gauss * 1000)";
CM_ SG_ 42 magnetometer_x "LIS3MDL @ FS=16gauss (matches lis3mdl_from_fs16_to_gauss * 1000)";
CM_ BO_ 43 "Magnetometer (LIS3MDL, FS=16gauss) + die temperature.";
CM_ SG_ 43 mag_temp "LIS3MDL die temperature";
CM_ SG_ 43 magnetometer_z "LIS3MDL @ FS=16gauss (matches lis3mdl_from_fs16_to_gauss * 1000)";
CM_ SG_ 43 magnetometer_y "LIS3MDL @ FS=16gauss (matches lis3mdl_from_fs16_to_gauss * 1000)";
CM_ SG_ 43 magnetometer_x "LIS3MDL @ FS=16gauss (matches lis3mdl_from_fs16_to_gauss * 1000)";
CM_ BO_ 45 "DART message for Tachometer measurements first 4 fan speeds.";
CM_ BO_ 46 "DART message for Tachometer measurements 5th fan speed.";
CM_ BO_ 52 "BBB TPS Chip";
CM_ BO_ 53 "PCU TPS Chip";
CM_ BO_ 54 "Dash TPS Chip";
CM_ BO_ 55 "DCU TPS Chip";
CM_ BO_ 56 "PCU RAW ACC ADC";
CM_ BO_ 57 "PCU raw pedal sensor voltages (sensor-side mV): APPS1/2, brake 1/2";
CM_ BO_ 64 "GPS latitude/longitude.";
CM_ BO_ 65 "GPS altitude + horizontal/vertical DOP.";
CM_ BO_ 66 "GPS speed and course-over-ground.";
CM_ BO_ 67 "GPS Time data message (UTC).";
CM_ BO_ 68 "GPS Date data message.";
CM_ BO_ 69 "GPS fix quality, satellite counts, validity flags, position DOP.";
CM_ SG_ 69 fix_mode "1=NoFix, 2=2D, 3=3D";
CM_ SG_ 69 fix_type "0=Invalid, 1=GPS, 2=DGPS, 3=PPS";
CM_ BO_ 71 "Fusion AHRS orientation quaternion (w, x, y, z).";
CM_ BO_ 72 "Fusion AHRS Euler angles.";
CM_ BO_ 73 "Fusion linear acceleration (gravity removed, body frame).";
CM_ BO_ 74 "Fusion linear acceleration (gravity removed, earth frame).";
CM_ BO_ 75 "Fusion AHRS internal flags + accel/mag rejection errors.";
CM_ SG_ 75 flags "bit0 startup, bit1 angRateRecov, bit2 accelRecov, bit3 magRecov, bit4 accelIgnored, bit5 magIgnored";
CM_ BO_ 78 "Steering encoder filtered/raw angle, AGC gain, magnet status flags, and CORDIC magnitude.";
CM_ SG_ 78 magnitude "12-bit CORDIC magnitude";
CM_ SG_ 78 status "magnet flags (bit0=MH, bit1=ML, bit2=MD)";
CM_ SG_ 78 agc "AGC gain value";
CM_ SG_ 78 raw_angle "12-bit raw angle";
CM_ SG_ 78 angle "12-bit filtered angle";
CM_ BO_ 80 "GPS latitude/longitude.";
CM_ BO_ 81 "GPS altitude + horizontal/vertical DOP.";
CM_ BO_ 82 "GPS speed and course-over-ground.";
CM_ BO_ 83 "GPS Time data message (UTC).";
CM_ BO_ 84 "GPS Date data message.";
CM_ BO_ 85 "GPS fix quality, satellite counts, validity flags, position DOP.";
CM_ SG_ 85 fix_mode "1=NoFix, 2=2D, 3=3D";
CM_ SG_ 85 fix_type "0=Invalid, 1=GPS, 2=DGPS, 3=PPS";
CM_ BO_ 87 "Fusion AHRS orientation quaternion (w, x, y, z).";
CM_ BO_ 88 "Fusion AHRS Euler angles.";
CM_ BO_ 89 "Fusion linear acceleration (gravity removed, body frame).";
CM_ BO_ 90 "Fusion linear acceleration (gravity removed, earth frame).";
CM_ BO_ 91 "Fusion AHRS internal flags + accel/mag rejection errors.";
CM_ SG_ 91 flags "bit0 startup, bit1 angRateRecov, bit2 accelRecov, bit3 magRecov, bit4 accelIgnored, bit5 magIgnored";
CM_ SG_ 160 INV_Gate_Driver_Board "Gate Driver Board Temperature";
CM_ SG_ 160 INV_Module_C "IGBT Module C Temperature";
CM_ SG_ 160 INV_Module_B "IGBT Module B Temperature";
CM_ SG_ 160 INV_Module_A "IGBT Module A Temperature";
CM_ SG_ 161 INV_RTD3_Temperature "RTD input 3 (PT1000) Temperature";
CM_ SG_ 161 INV_RTD2_Temperature "RTD input 2 (PT1000) Temperature";
CM_ SG_ 161 INV_RTD1_Temperature "RTD input 1 (PT1000) Temperature";
CM_ SG_ 161 INV_Control_Board_Temperature "Control Board Temperature";
CM_ SG_ 162 INV_Torque_Shudder "Shudder compensation value of torque";
CM_ SG_ 162 INV_Motor_Temperature "Motor Temperature Sensor";
CM_ SG_ 162 INV_RTD5_Temperature "RTD 5 (PT100) Temperature (Gen 2 only)";
CM_ SG_ 162 INV_RTD4_Temperature "RTD 4 (PT100) Temperature (Gen 2 only)";
CM_ SG_ 163 INV_Analog_Input_6 "Voltage on Analog Input #6";
CM_ SG_ 163 INV_Analog_Input_5 "Voltage on Analog Input #5";
CM_ SG_ 163 INV_Analog_Input_4 "Voltage on Analog Input #4";
CM_ SG_ 163 INV_Analog_Input_3 "Voltage on Analog Input #3";
CM_ SG_ 163 INV_Analog_Input_2 "Voltage on Analog Input #2";
CM_ SG_ 163 INV_Analog_Input_1 "Voltage on Analog Input #1";
CM_ SG_ 164 INV_Digital_Input_8 "Status of Digital Input #8";
CM_ SG_ 164 INV_Digital_Input_7 "Status of Digital Input #7";
CM_ SG_ 164 INV_Digital_Input_6 "Status of Digital Input #6";
CM_ SG_ 164 INV_Digital_Input_5 "Status of Digital Input #5";
CM_ SG_ 164 INV_Digital_Input_4 "Status of Digital Input #4";
CM_ SG_ 164 INV_Digital_Input_3 "Status of Digital Input #3";
CM_ SG_ 164 INV_Digital_Input_2 "Status of Digital Input #2";
CM_ SG_ 164 INV_Digital_Input_1 "Status of Digital Input #1";
CM_ SG_ 165 INV_Delta_Resolver_Filtered "Used in calibration of resolver angle adjustment.";
CM_ SG_ 165 INV_Electrical_Output_Frequency "The actual electrical frequency of the inverter";
CM_ SG_ 165 INV_Motor_Speed "The measured speed of the motor";
CM_ SG_ 165 INV_Motor_Angle_Electrical "The Electrical Angle of the motor as read by the encoder or resolver";
CM_ SG_ 166 INV_DC_Bus_Current "The Calculated DC Bus Current";
CM_ SG_ 166 INV_Phase_C_Current "The measured value of Phase C current";
CM_ SG_ 166 INV_Phase_B_Current "The measured value of Phase B current";
CM_ SG_ 166 INV_Phase_A_Current "The measured value of Phase A current";
CM_ SG_ 167 INV_VBC_Vq_Voltage "Measured value of the voltage between Phase B and Phase C";
CM_ SG_ 167 INV_VAB_Vd_Voltage "Measured value of the voltage betwen phase A and Phase B";
CM_ SG_ 167 INV_Output_Voltage "The calculated value of the output voltage, in peak line-neutral volts";
CM_ SG_ 167 INV_DC_Bus_Voltage "The actual measured value of the DC bus voltage";
CM_ SG_ 168 INV_Iq "The measured Iq current";
CM_ SG_ 168 INV_Id "The measured Id current";
CM_ SG_ 168 INV_Flux_Feedback "The estimated flux";
CM_ SG_ 168 INV_Flux_Command "The commanded flux";
CM_ SG_ 169 INV_Reference_Voltage_12_0 "12V Input Voltage";
CM_ SG_ 169 INV_Reference_Voltage_5_0 "Transducer voltage";
CM_ SG_ 169 INV_Reference_Voltage_2_5 "Internal reference voltage";
CM_ SG_ 169 INV_Reference_Voltage_1_5 "Internal reference voltage";
CM_ SG_ 170 INV_Low_Speed_Limiting "0 = Not Limiting, 1 = Current limiting due to low motor speed";
CM_ SG_ 170 INV_Max_Speed_Limiting "0 = Not Limiting, 1 = torque limiting due to maximum speed";
CM_ SG_ 170 INV_BMS_Torque_Limiting "0 = Not Limiting, 1 = Limiting";
CM_ SG_ 170 INV_BMS_Active "0 = BMS Not Active, 1 = BMS Active";
CM_ SG_ 170 INV_Direction_Command "1 = Forward
0 = 'Reverse' if inverter enabled  & 'Stopped' if inverter is disabled";
CM_ SG_ 170 INV_Inverter_Enable_Lockout "0=Lockout Disabled, 1=Lockout Enabled";
CM_ SG_ 170 INV_Start_Mode_Active "If in Key Switch Mode 1 then indicates status of Start input being applied.  0 = not active, 1 = active";
CM_ SG_ 170 INV_Inverter_Enable_State "0=Inverter Disabled, 
1=Inverter Enabled";
CM_ SG_ 170 INV_Rolling_Counter "The current rolling counter value.";
CM_ SG_ 170 INV_Inverter_Command_Mode "0=CAN mode, 1=VSM mode";
CM_ SG_ 170 INV_Inverter_Discharge_State "0 = Disabled, 1 = Enabled, 2 = Speed Check, 3 = Active, 4 = Complete";
CM_ SG_ 170 INV_Inverter_Run_Mode "0=Torque Mode, 1=Speed Mode";
CM_ SG_ 170 INV_Relay_6_Status "0=OFF, 1=ON";
CM_ SG_ 170 INV_Relay_5_Status "0=OFF, 1=ON";
CM_ SG_ 170 INV_Relay_4_Status "0=OFF, 1=ON";
CM_ SG_ 170 INV_Relay_3_Status "0=OFF, 1=ON";
CM_ SG_ 170 INV_Relay_2_Status "0=OFF, 1=ON";
CM_ SG_ 170 INV_Relay_1_Status "0=OFF, 1=ON";
CM_ SG_ 170 INV_Inverter_State "Different states for the inverter state machine";
CM_ SG_ 170 INV_PWM_Frequency "The inverter PWM frequency";
CM_ SG_ 170 INV_VSM_State "Different states for the vehicle state machine";
CM_ SG_ 171 INV_Run_Fault_Hi "Each bit represents a fault. Please refer to PM100 Users Manual for details.";
CM_ SG_ 171 INV_Run_Fault_Lo "Each bit represents a fault. Please refer to PM100 Users Manual for details.";
CM_ SG_ 171 INV_Post_Fault_Hi "Each bit represents a fault. Please refer to PM100 Users Manual for details.";
CM_ SG_ 171 INV_Post_Fault_Lo "Each bit represents a fault. Please refer to PM100 Users Manual for details.";
CM_ SG_ 172 INV_Power_On_Timer "Updated every 3 msec. This will roll over in approximately 150 days!";
CM_ SG_ 172 INV_Torque_Feedback "Estimated motor torque feedback";
CM_ SG_ 172 INV_Commanded_Torque "The commanded Torque";
CM_ SG_ 173 INV_Iq_Command "The commanded Q-axis current";
CM_ SG_ 173 INV_Id_Command "The commanded D-axis current";
CM_ SG_ 173 INV_Flux_Weakening_Output "This is the current output of the flux regulator.";
CM_ SG_ 173 INV_Modulation_Index "This is the modulation index. The scale factor is x100. To get the actual modulation index divide the value by 100.";
CM_ BO_ 176 "To enable fast message set CAN ACTIVE MSGS HI WORD to 0xFFFE.  Setting to default value of 0xFFFF will disable the fast message.";
CM_ BO_ 192 "The command message is used to transmit data to the controller. This message is sent from a user supplied external controller to the PMxxx controller.";
CM_ BO_ 193 "Parameter Message sent as needed by VCU to request info, change EEPROM, or command a function.";
CM_ BO_ 194 "The inverter response to each Parameter message that is received.";
CM_ SG_ 194 INV_Data_Response "All EEPROM data is 16 bits and is contained in bytes 4 and 5. Bytes 6 and 7 should be ignored.";
CM_ SG_ 194 INV_Write_Success "0=Write failure, 1=Success";
CM_ SG_ 194 INV_Parameter_Address_Response "Valid EEPROM Parameter CAN addresses are between 100 and 499.";
CM_ BO_ 208 "PCU heartbeat";
CM_ BO_ 209 "Dash Heartbeat";
CM_ BO_ 210 "LVPDB Heartbeat";
CM_ BO_ 211 "DCU Heartbeat";
CM_ BO_ 212 "Sensor Node Heartbeat";
CM_ SG_ 212 error63 "Unallocated";
CM_ SG_ 212 error62 "Unallocated";
CM_ SG_ 212 error61 "Unallocated";
CM_ SG_ 212 error60 "Unallocated";
CM_ SG_ 212 error59 "Unallocated";
CM_ SG_ 212 error58 "Unallocated";
CM_ SG_ 212 error57 "Unallocated";
CM_ SG_ 212 error56 "Unallocated";
CM_ SG_ 212 error55 "Unallocated";
CM_ SG_ 212 error54 "Unallocated";
CM_ SG_ 212 error53 "Unallocated";
CM_ SG_ 212 error52 "Unallocated";
CM_ SG_ 212 error51 "Unallocated";
CM_ SG_ 212 error50 "Unallocated";
CM_ SG_ 212 error49 "Unallocated";
CM_ SG_ 212 error48 "Unallocated";
CM_ SG_ 212 error47 "Unallocated";
CM_ SG_ 212 error46 "Unallocated";
CM_ SG_ 212 error45 "Unallocated";
CM_ SG_ 212 error44 "Unallocated";
CM_ SG_ 212 error43 "Unallocated";
CM_ SG_ 212 error42 "Unallocated";
CM_ SG_ 212 error41 "Unallocated";
CM_ SG_ 212 error40 "Unallocated";
CM_ SG_ 212 error39 "Unallocated";
CM_ SG_ 212 error38 "Unallocated";
CM_ SG_ 212 error37 "Unallocated";
CM_ SG_ 212 error36 "Unallocated";
CM_ SG_ 212 error35 "Unallocated";
CM_ SG_ 212 error34 "Unallocated";
CM_ SG_ 212 error33 "Unallocated";
CM_ SG_ 212 error32 "Unallocated";
CM_ SG_ 212 error31 "Unallocated";
CM_ SG_ 212 error30 "Unallocated";
CM_ SG_ 212 error29 "Unallocated";
CM_ SG_ 212 error28 "Unallocated";
CM_ SG_ 212 error27 "Unallocated";
CM_ SG_ 212 error26 "Unallocated";
CM_ SG_ 212 error25 "Unallocated";
CM_ SG_ 212 error24 "Unallocated";
CM_ SG_ 212 error23 "CAN controller health";
CM_ SG_ 212 error22 "CAN controller health";
CM_ SG_ 212 error21 "CAN controller health";
CM_ SG_ 212 error20 "CAN controller health";
CM_ SG_ 212 error19 "CAN controller health";
CM_ SG_ 212 can_rx_overflow "CAN controller health";
CM_ SG_ 212 can_tx_overflow "CAN controller health";
CM_ SG_ 212 can_bus_off "CAN controller health";
CM_ SG_ 212 error15 "Data freshness";
CM_ SG_ 212 error14 "Data freshness";
CM_ SG_ 212 error13 "Data freshness";
CM_ SG_ 212 wss_right_no_signal "Data freshness";
CM_ SG_ 212 wss_left_no_signal "Data freshness";
CM_ SG_ 212 gps_link_slow "Data freshness";
CM_ SG_ 212 gps_stale "Data freshness";
CM_ SG_ 212 gps_no_fix "Data freshness";
CM_ SG_ 212 error7 "Device init / read fault";
CM_ SG_ 212 lp_out_of_range "Device init / read fault";
CM_ SG_ 212 fusion_uncalibrated "Device init / read fault";
CM_ SG_ 212 gps_init_failed "Device init / read fault";
CM_ SG_ 212 mag_read_failed "Device init / read fault";
CM_ SG_ 212 mag_init_failed "Device init / read fault";
CM_ SG_ 212 imu_read_failed "Device init / read fault";
CM_ SG_ 212 imu_init_failed "Device init / read fault";
CM_ BO_ 213 "Sensor Node Heartbeat";
CM_ SG_ 213 error63 "Unallocated";
CM_ SG_ 213 error62 "Unallocated";
CM_ SG_ 213 error61 "Unallocated";
CM_ SG_ 213 error60 "Unallocated";
CM_ SG_ 213 error59 "Unallocated";
CM_ SG_ 213 error58 "Unallocated";
CM_ SG_ 213 error57 "Unallocated";
CM_ SG_ 213 error56 "Unallocated";
CM_ SG_ 213 error55 "Unallocated";
CM_ SG_ 213 error54 "Unallocated";
CM_ SG_ 213 error53 "Unallocated";
CM_ SG_ 213 error52 "Unallocated";
CM_ SG_ 213 error51 "Unallocated";
CM_ SG_ 213 error50 "Unallocated";
CM_ SG_ 213 error49 "Unallocated";
CM_ SG_ 213 error48 "Unallocated";
CM_ SG_ 213 error47 "Unallocated";
CM_ SG_ 213 error46 "Unallocated";
CM_ SG_ 213 error45 "Unallocated";
CM_ SG_ 213 error44 "Unallocated";
CM_ SG_ 213 error43 "Unallocated";
CM_ SG_ 213 error42 "Unallocated";
CM_ SG_ 213 error41 "Unallocated";
CM_ SG_ 213 error40 "Unallocated";
CM_ SG_ 213 error39 "Unallocated";
CM_ SG_ 213 error38 "Unallocated";
CM_ SG_ 213 error37 "Unallocated";
CM_ SG_ 213 error36 "Unallocated";
CM_ SG_ 213 error35 "Unallocated";
CM_ SG_ 213 error34 "Unallocated";
CM_ SG_ 213 error33 "Unallocated";
CM_ SG_ 213 error32 "Unallocated";
CM_ SG_ 213 error31 "Unallocated";
CM_ SG_ 213 error30 "Unallocated";
CM_ SG_ 213 error29 "Unallocated";
CM_ SG_ 213 error28 "Unallocated";
CM_ SG_ 213 error27 "Unallocated";
CM_ SG_ 213 error26 "Unallocated";
CM_ SG_ 213 error25 "Unallocated";
CM_ SG_ 213 error24 "Unallocated";
CM_ SG_ 213 error23 "CAN controller health";
CM_ SG_ 213 error22 "CAN controller health";
CM_ SG_ 213 error21 "CAN controller health";
CM_ SG_ 213 error20 "CAN controller health";
CM_ SG_ 213 error19 "CAN controller health";
CM_ SG_ 213 can_rx_overflow "CAN controller health";
CM_ SG_ 213 can_tx_overflow "CAN controller health";
CM_ SG_ 213 can_bus_off "CAN controller health";
CM_ SG_ 213 error15 "Data freshness";
CM_ SG_ 213 error14 "Data freshness";
CM_ SG_ 213 error13 "Data freshness";
CM_ SG_ 213 wss_right_no_signal "Data freshness";
CM_ SG_ 213 wss_left_no_signal "Data freshness";
CM_ SG_ 213 gps_link_slow "Data freshness";
CM_ SG_ 213 gps_stale "Data freshness";
CM_ SG_ 213 gps_no_fix "Data freshness";
CM_ SG_ 213 error7 "Device init / read fault";
CM_ SG_ 213 lp_out_of_range "Device init / read fault";
CM_ SG_ 213 fusion_uncalibrated "Device init / read fault";
CM_ SG_ 213 gps_init_failed "Device init / read fault";
CM_ SG_ 213 mag_read_failed "Device init / read fault";
CM_ SG_ 213 mag_init_failed "Device init / read fault";
CM_ SG_ 213 imu_read_failed "Device init / read fault";
CM_ SG_ 213 imu_init_failed "Device init / read fault";
CM_ BO_ 224 "PING PONG counter1.";
CM_ BO_ 225 "PING PONG counter2.";
CM_ BO_ 226 "PING PONG counter3.";
CM_ BO_ 227 "PING PONG counter4.";
CM_ BO_ 469 "Response from Delphi DC/DC converter.";
CM_ BO_ 471 "Enable message sent to Delphi DC/DC converter.";
CM_ BO_ 514 "Message sent by BMS for inverter DC current limiting.";
CM_ SG_ 514 INV_Max_Charge_Current "Maximum charge current from BMS";
CM_ SG_ 514 INV_Max_Discharge_Current "Maximum discharge current from BMS";
CM_ BO_ 516 "Accumulator cell voltages, paged via the page multiplexer.";
CM_ SG_ 516 page "Page index: selects which cells occupy the four value slots.";
CM_ BO_ 517 "Accumulator cell temperatures, paged via the page multiplexer.";
CM_ SG_ 517 page "Page index: selects which cells occupy the four value slots.";
CM_ BO_ 1280 "EBS Pressure Status - 4 pressure sensors (scale: 1/16, unit: bar)";
CM_ BO_ 1313 "Isabellenhutte IVT-S pack current (A, FEB sign convention).";
CM_ BO_ 1314 "Isabellenhutte IVT-S voltage 1 / pack voltage (V).";
CM_ BO_ 1315 "Isabellenhutte IVT-S voltage 2 (V).";
CM_ BO_ 1316 "Isabellenhutte IVT-S voltage 3 (V).";
CM_ BO_ 1317 "Isabellenhutte IVT-S temperature (degC).";
CM_ SG_ 2550588916 Control "Toggle charging";
CM_ SG_ 2550588916 MaxCurrent "Max Allowable Charging Current";
CM_ SG_ 2550588916 MaxVoltage "Max Allowable Charging Terminal Voltage";
CM_ SG_ 2566869221 CommunicationState "Charger communication state";
CM_ SG_ 2566869221 State "Charger starting state";
CM_ SG_ 2566869221 InputVoltage "Charger input voltage";
CM_ SG_ 2566869221 Temperature "Charger temperature";
CM_ SG_ 2566869221 HWStatus "Charger status";
CM_ SG_ 2566869221 OutputCurrent "Output Current";
CM_ SG_ 2566869221 OutputVoltage "Output Voltage";
BA_DEF_  "BusType" STRING ;
BA_DEF_ BO_  "SystemMessageLongSymbol" STRING ;
BA_DEF_ SG_  "SystemSignalLongSymbol" STRING ;
BA_DEF_ BO_  "GenMsgCycleTime" INT 0 65535;
BA_DEF_DEF_  "BusType" "CAN";
BA_DEF_DEF_  "SystemMessageLongSymbol" "";
BA_DEF_DEF_  "SystemSignalLongSymbol" "";
BA_DEF_DEF_  "GenMsgCycleTime" 0;
BA_ "GenMsgCycleTime" BO_ 1 100;
BA_ "GenMsgCycleTime" BO_ 2 100;
BA_ "GenMsgCycleTime" BO_ 3 100;
BA_ "GenMsgCycleTime" BO_ 4 100;
BA_ "GenMsgCycleTime" BO_ 5 100;
BA_ "GenMsgCycleTime" BO_ 9 100;
BA_ "GenMsgCycleTime" BO_ 10 100;
BA_ "GenMsgCycleTime" BO_ 11 100;
BA_ "GenMsgCycleTime" BO_ 16 100;
BA_ "SystemMessageLongSymbol" BO_ 22 "lvpdb_lv_24v_bus_and_12v_bus_voltages";
BA_ "GenMsgCycleTime" BO_ 22 100;
BA_ "GenMsgCycleTime" BO_ 23 100;
BA_ "GenMsgCycleTime" BO_ 24 100;
BA_ "GenMsgCycleTime" BO_ 30 20;
BA_ "GenMsgCycleTime" BO_ 31 20;
BA_ "GenMsgCycleTime" BO_ 32 1000;
BA_ "GenMsgCycleTime" BO_ 33 1000;
BA_ "GenMsgCycleTime" BO_ 34 1000;
BA_ "GenMsgCycleTime" BO_ 35 1000;
BA_ "GenMsgCycleTime" BO_ 36 20;
BA_ "GenMsgCycleTime" BO_ 37 20;
BA_ "GenMsgCycleTime" BO_ 38 100;
BA_ "GenMsgCycleTime" BO_ 39 100;
BA_ "GenMsgCycleTime" BO_ 40 100;
BA_ "GenMsgCycleTime" BO_ 41 100;
BA_ "GenMsgCycleTime" BO_ 42 100;
BA_ "GenMsgCycleTime" BO_ 43 100;
BA_ "GenMsgCycleTime" BO_ 45 100;
BA_ "GenMsgCycleTime" BO_ 46 100;
BA_ "GenMsgCycleTime" BO_ 52 100;
BA_ "GenMsgCycleTime" BO_ 53 100;
BA_ "GenMsgCycleTime" BO_ 54 100;
BA_ "GenMsgCycleTime" BO_ 55 100;
BA_ "GenMsgCycleTime" BO_ 56 50;
BA_ "GenMsgCycleTime" BO_ 57 100;
BA_ "GenMsgCycleTime" BO_ 64 200;
BA_ "GenMsgCycleTime" BO_ 65 200;
BA_ "GenMsgCycleTime" BO_ 66 200;
BA_ "GenMsgCycleTime" BO_ 67 200;
BA_ "GenMsgCycleTime" BO_ 68 200;
BA_ "GenMsgCycleTime" BO_ 69 200;
BA_ "GenMsgCycleTime" BO_ 71 100;
BA_ "GenMsgCycleTime" BO_ 72 100;
BA_ "GenMsgCycleTime" BO_ 73 100;
BA_ "GenMsgCycleTime" BO_ 74 100;
BA_ "GenMsgCycleTime" BO_ 75 100;
BA_ "GenMsgCycleTime" BO_ 78 100;
BA_ "GenMsgCycleTime" BO_ 80 200;
BA_ "GenMsgCycleTime" BO_ 81 200;
BA_ "GenMsgCycleTime" BO_ 82 200;
BA_ "GenMsgCycleTime" BO_ 83 200;
BA_ "GenMsgCycleTime" BO_ 84 200;
BA_ "GenMsgCycleTime" BO_ 85 200;
BA_ "GenMsgCycleTime" BO_ 87 100;
BA_ "GenMsgCycleTime" BO_ 88 100;
BA_ "GenMsgCycleTime" BO_ 89 100;
BA_ "GenMsgCycleTime" BO_ 90 100;
BA_ "GenMsgCycleTime" BO_ 91 100;
BA_ "GenMsgCycleTime" BO_ 160 100;
BA_ "GenMsgCycleTime" BO_ 161 100;
BA_ "GenMsgCycleTime" BO_ 162 100;
BA_ "GenMsgCycleTime" BO_ 163 10;
BA_ "GenMsgCycleTime" BO_ 164 10;
BA_ "GenMsgCycleTime" BO_ 165 10;
BA_ "GenMsgCycleTime" BO_ 166 10;
BA_ "GenMsgCycleTime" BO_ 167 10;
BA_ "GenMsgCycleTime" BO_ 168 10;
BA_ "GenMsgCycleTime" BO_ 169 100;
BA_ "GenMsgCycleTime" BO_ 170 100;
BA_ "GenMsgCycleTime" BO_ 171 100;
BA_ "GenMsgCycleTime" BO_ 172 10;
BA_ "GenMsgCycleTime" BO_ 175 3;
BA_ "GenMsgCycleTime" BO_ 176 3;
BA_ "GenMsgCycleTime" BO_ 192 5;
BA_ "SystemSignalLongSymbol" SG_ 193 VCU_INV_Parameter_Address_Comman "VCU_INV_Parameter_Address_Command";
BA_ "GenMsgCycleTime" BO_ 208 100;
BA_ "GenMsgCycleTime" BO_ 209 100;
BA_ "GenMsgCycleTime" BO_ 210 100;
BA_ "GenMsgCycleTime" BO_ 211 100;
BA_ "GenMsgCycleTime" BO_ 212 100;
BA_ "GenMsgCycleTime" BO_ 213 100;
BA_ "GenMsgCycleTime" BO_ 224 100;
BA_ "GenMsgCycleTime" BO_ 225 100;
BA_ "GenMsgCycleTime" BO_ 226 100;
BA_ "GenMsgCycleTime" BO_ 227 100;
BA_ "SystemSignalLongSymbol" SG_ 469 INV_HV_Input_Current_Sensor_Vali "INV_HV_Input_Current_Sensor_Validity";
BA_ "GenMsgCycleTime" BO_ 516 10;
BA_ "GenMsgCycleTime" BO_ 517 10;
BA_ "GenMsgCycleTime" BO_ 1280 100;
BA_ "GenMsgCycleTime" BO_ 2550588916 1000;
BA_ "GenMsgCycleTime" BO_ 2566869221 1000;
VAL_ 5 bms_state 0 "BMS_STATE_BOOT" 1 "BMS_STATE_LV_POWER" 2 "BMS_STATE_BUS_HEALTH_CHECK" 3 "BMS_STATE_PRECHARGE" 4 "BMS_STATE_ENERGIZED" 5 "BMS_STATE_DRIVE" 6 "BMS_STATE_BATTERY_FREE" 7 "BMS_STATE_CHARGER_PRECHARGE" 8 "BMS_STATE_CHARGING" 9 "BMS_STATE_BALANCE" 10 "BMS_STATE_FAULT_BMS" 11 "BMS_STATE_FAULT_BSPD" 12 "BMS_STATE_FAULT_IMD" 13 "BMS_STATE_FAULT_CHARGING" 14 "BMS_STATE_COUNT" ;
VAL_ 170 INV_Inverter_State 0 "Power up" 1 "Stop" 2 "Open Loop" 3 "Closed Loop" 4 "Internal State" 5 "Internal State" 6 "Internal State" 7 "Internal State" 8 "Idle Run" 9 "Idle Stop" 10 "Internal State" 11 "Intern State" 12 "Internal State" ;
VAL_ 170 INV_VSM_State 0 "VSM Start State" 1 "Pre-Charge Init state" 2 "pre-charge active state" 3 "pre-charge complete state" 4 "VSM wait state" 5 "VSM ready state" 6 "Motor Running State" 7 "blink fault code state" 14 "Shutdown state for Key Switch Mode 1" 15 "Reset the inverter" ;
VAL_ 2550588916 Control 1 "CHARGING_STOP" 0 "CHARGING_START" ;
VAL_ 2566869221 CommunicationState 0 "COMM_STATE_OK" 1 "COMM_STATE_TIMEOUT" ;
VAL_ 2566869221 State 0 "STATE_CHARGING" 1 "STATE_OFF" ;
VAL_ 2566869221 InputVoltage 0 "INPUT_VOLTAGE_OK" 1 "INPUT_VOLTAGE_FAULT" ;
VAL_ 2566869221 Temperature 0 "TEMP_OK" 1 "TEMP_FAULT" ;
VAL_ 2566869221 HWStatus 0 "HW_STATUS_OK" 1 "HW_STATUS_FAIL" ;
